VERSION "$Format:%h$"

NS_ :

BS_:

BU_: APB APP APS BCCEN BDY DAS DBG EAS EPAS EPAS2 EPAS3S EPB EPBM ESP GTW GTWU IBST IC MCU OCS PARK PARK3 RADAR RCM RT3000 SCCM SDM SEC TAS TAS2 TAS2DBG TOOL TPMS VCSEATD VCSEATP

BO_ 1481 APS_alertLog: 8 APS
 SG_ APS_alertID M : 0|14@1+ (1,0) [0|0] "" GTW
 SG_ APS_alertSource : 14|1@1+ (1,0) [0|0] "" GTW
 SG_ APS_alertType : 15|1@1+ (1,0) [0|0] "" GTW
 SG_ APS_alertDataW0 m0 : 16|16@1+ (1,0) [0|0] "" GTW
 SG_ APS_alertDataW1 m0 : 32|16@1+ (1,0) [0|0] "" GTW
 SG_ APS_alertDataW2 m0 : 48|16@1+ (1,0) [0|0] "" GTW
 SG_ APS_sw004_radIssue m4 : 16|1@1+ (1,0) [0|0] "" GTW
 SG_ APS_sw004_radHWFailure m4 : 17|1@1+ (1,0) [0|0] "" GTW
 SG_ APS_sw004_radSensorBlind m4 : 18|1@1+ (1,0) [0|0] "" GTW
 SG_ APS_sw004_radSGUFailure m4 : 19|1@1+ (1,0) [0|0] "" GTW
 SG_ APS_sw004_radMia m4 : 20|1@1+ (1,0) [0|0] "" GTW
 SG_ APS_sw004_radDynamicsError m4 : 21|1@1+ (1,0) [0|0] "" GTW
 SG_ APS_sw004_espMIA m4 : 23|1@1+ (1,0) [0|0] "" GTW
 SG_ APS_sw004_accState m4 : 24|4@1+ (1,0) [0|0] "" GTW
 SG_ APS_sw004_appMobileyeStatus m4 : 28|5@1+ (1,0) [0|0] "" GTW
 SG_ APS_sw004_diCruiseStateFault m4 : 33|1@1+ (1,0) [0|0] "" GTW
 SG_ APS_sw004_diMIA m4 : 34|1@1+ (1,0) [0|0] "" GTW
 SG_ APS_sw004_accelPedalInvalid m4 : 35|1@1+ (1,0) [0|0] "" GTW
 SG_ APS_sw004_stwAngleInvalid m4 : 36|1@1+ (1,0) [0|0] "" GTW
 SG_ APS_sw004_accelerationInvalid m4 : 37|1@1+ (1,0) [0|0] "" GTW
 SG_ APS_sw004_diSpeedInvalid m4 : 38|1@1+ (1,0) [0|0] "" GTW
 SG_ APS_sw004_APSFeaturesDisabled m4 : 40|1@1+ (1,0) [0|0] "" GTW
 SG_ APS_sw004_appMobileyeNotInVision m4 : 41|1@1+ (1,0) [0|0] "" GTW
 SG_ APS_sw004_CamCommonMIA m4 : 42|1@1+ (1,0) [0|0] "" GTW
 SG_ APS_sw004_CamObjectsMIA m4 : 43|1@1+ (1,0) [0|0] "" GTW
 SG_ APS_sw004_CamWatchdog m4 : 44|1@1+ (1,0) [0|0] "" GTW
 SG_ APS_sw004_RadarLowVisibility m4 : 45|1@1+ (1,0) [0|0] "" GTW
 SG_ APS_sw004_RadarMisalignment m4 : 46|1@1+ (1,0) [0|0] "" GTW
 SG_ APS_sw004_OutOfFocusImage m4 : 47|1@1+ (1,0) [0|0] "" GTW
 SG_ APS_sw004_ImpairedVD m4 : 48|1@1+ (1,0) [0|0] "" GTW
 SG_ APS_sw004_SunRay m4 : 49|1@1+ (1,0) [0|0] "" GTW
 SG_ APS_sw004_Splashes m4 : 50|1@1+ (1,0) [0|0] "" GTW
 SG_ APS_sw004_BlurredImage m4 : 51|1@1+ (1,0) [0|0] "" GTW
 SG_ APS_sw004_LowSun m4 : 52|1@1+ (1,0) [0|0] "" GTW
 SG_ APS_sw004_SmearedSpots m4 : 53|1@1+ (1,0) [0|0] "" GTW
 SG_ APS_sw004_PartialBlockage m4 : 54|1@1+ (1,0) [0|0] "" GTW
 SG_ APS_sw004_AutofixOutOfCalib m4 : 55|1@1+ (1,0) [0|0] "" GTW
 SG_ APS_sw004_AutofixOutOfCalibHorzn m4 : 56|1@1+ (1,0) [0|0] "" GTW
 SG_ APS_sw004_AutofixOutOfCalibYaw m4 : 57|1@1+ (1,0) [0|0] "" GTW
 SG_ APS_sw004_FullBlockage m4 : 58|1@1+ (1,0) [0|0] "" GTW
 SG_ APS_sw004_SmearedHalos m4 : 59|1@1+ (1,0) [0|0] "" GTW
 SG_ APS_sw004_FoggyLights m4 : 60|1@1+ (1,0) [0|0] "" GTW
 SG_ APS_sw004_SelfGlare m4 : 61|1@1+ (1,0) [0|0] "" GTW
 SG_ APS_sw004_visionNotRunning m4 : 62|1@1+ (1,0) [0|1] "" GTW
 SG_ APS_sw005_AutofixOutOfCalib m5 : 16|1@1+ (1,0) [0|0] "" GTW
 SG_ APS_sw005_AutofixOutOfCalibYaw m5 : 17|1@1+ (1,0) [0|0] "" GTW
 SG_ APS_sw005_RadarMisalignment m5 : 18|1@1+ (1,0) [0|0] "" GTW
 SG_ APS_sw005_partialBlockage m5 : 20|1@1+ (1,0) [0|0] "" GTW
 SG_ APS_sw005_fullBlockage m5 : 21|1@1+ (1,0) [0|0] "" GTW
 SG_ APS_sw005_camObjHeader m5 : 22|1@1+ (1,0) [0|0] "" GTW
 SG_ APS_sw005_camCommonMsg m5 : 23|1@1+ (1,0) [0|0] "" GTW
 SG_ APS_sw005_camFcwPcwMsg m5 : 24|1@1+ (1,0) [0|0] "" GTW
 SG_ APS_sw005_radHWFailure m5 : 25|1@1+ (1,0) [0|0] "" GTW
 SG_ APS_sw005_radSensorBlind m5 : 26|1@1+ (1,0) [0|0] "" GTW
 SG_ APS_sw005_radSGUFailure m5 : 27|1@1+ (1,0) [0|0] "" GTW
 SG_ APS_sw005_radMia m5 : 28|1@1+ (1,0) [0|0] "" GTW
 SG_ APS_sw005_brakePedal m5 : 29|1@1+ (1,0) [0|0] "" GTW
 SG_ APS_sw005_steeringAngle m5 : 30|1@1+ (1,0) [0|0] "" GTW
 SG_ APS_sw005_steeringAngleRate m5 : 31|1@1+ (1,0) [0|0] "" GTW
 SG_ APS_sw005_speed m5 : 32|1@1+ (1,0) [0|0] "" GTW
 SG_ APS_sw005_gear m5 : 33|1@1+ (1,0) [0|0] "" GTW
 SG_ APS_sw005_stabilityControl m5 : 34|1@1+ (1,0) [0|0] "" GTW
 SG_ APS_sw005_blinkers m5 : 35|1@1+ (1,0) [0|0] "" GTW
 SG_ APS_sw005_yaw m5 : 36|1@1+ (1,0) [0|0] "" GTW
 SG_ APS_sw005_longAccel m5 : 37|1@1+ (1,0) [0|0] "" GTW
 SG_ APS_sw005_accelPedal m5 : 38|1@1+ (1,0) [0|0] "" GTW
 SG_ APS_sw005_fcmSensitivity m5 : 41|1@1+ (1,0) [0|0] "" GTW
 SG_ APS_sw005_dasDisabled m5 : 42|1@1+ (1,0) [0|0] "" GTW
 SG_ APS_sw005_speedDerivative m5 : 43|1@1+ (1,0) [0|0] "" GTW
 SG_ APS_sw005_camWatchdog m5 : 44|1@1+ (1,0) [0|0] "" GTW
 SG_ APS_sw005_AutofixOutOfCalibHorzn m5 : 45|1@1+ (1,0) [0|0] "" GTW
 SG_ APS_sw005_RadarLowVisibility m5 : 46|1@1+ (1,0) [0|0] "" GTW
 SG_ APS_sw005_radCalibration m5 : 47|1@1+ (1,0) [0|0] "" GTW
 SG_ APS_sw006_RadarLowVisibility m6 : 16|1@1+ (1,0) [0|0] "" GTW
 SG_ APS_sw006_RadarMisaligned m6 : 17|1@1+ (1,0) [0|0] "" GTW
 SG_ APS_sw006_OutOfFocusImage m6 : 18|1@1+ (1,0) [0|0] "" GTW
 SG_ APS_sw006_SunRay m6 : 19|1@1+ (1,0) [0|0] "" GTW
 SG_ APS_sw006_Splashes m6 : 20|1@1+ (1,0) [0|0] "" GTW
 SG_ APS_sw006_BlurredImage m6 : 21|1@1+ (1,0) [0|0] "" GTW
 SG_ APS_sw006_LowSun m6 : 22|1@1+ (1,0) [0|0] "" GTW
 SG_ APS_sw006_SmearedSpots m6 : 23|1@1+ (1,0) [0|0] "" GTW
 SG_ APS_sw006_PartialBlockage m6 : 24|1@1+ (1,0) [0|0] "" GTW
 SG_ APS_sw006_AutofixOutOfCalib m6 : 25|1@1+ (1,0) [0|0] "" GTW
 SG_ APS_sw006_AutofixOutOfCalibHorzn m6 : 26|1@1+ (1,0) [0|0] "" GTW
 SG_ APS_sw006_AutofixOutOfCalibYaw m6 : 27|1@1+ (1,0) [0|0] "" GTW
 SG_ APS_sw006_FullBlockage m6 : 28|1@1+ (1,0) [0|0] "" GTW
 SG_ APS_sw006_SmearedHalos m6 : 29|1@1+ (1,0) [0|0] "" GTW
 SG_ APS_sw006_FoggyLights m6 : 30|1@1+ (1,0) [0|0] "" GTW
 SG_ APS_sw006_SelfGlare m6 : 31|1@1+ (1,0) [0|0] "" GTW
 SG_ APS_sw006_blinkers m6 : 32|1@1+ (1,0) [0|0] "" GTW
 SG_ APS_sw006_seatbelt m6 : 33|1@1+ (1,0) [0|0] "" GTW
 SG_ APS_sw006_accelPedal m6 : 34|1@1+ (1,0) [0|0] "" GTW
 SG_ APS_sw006_radMia m6 : 35|1@1+ (1,0) [0|0] "" GTW
 SG_ APS_sw006_radHWFailure m6 : 37|1@1+ (1,0) [0|0] "" GTW
 SG_ APS_sw006_radSensorBlind m6 : 38|1@1+ (1,0) [0|0] "" GTW
 SG_ APS_sw006_radSGUFailure m6 : 39|1@1+ (1,0) [0|0] "" GTW
 SG_ APS_sw006_brakePedal m6 : 40|1@1+ (1,0) [0|0] "" GTW
 SG_ APS_sw006_steeringAngle m6 : 41|1@1+ (1,0) [0|0] "" GTW
 SG_ APS_sw006_steeringAngleRate m6 : 42|1@1+ (1,0) [0|0] "" GTW
 SG_ APS_sw006_speed m6 : 43|1@1+ (1,0) [0|0] "" GTW
 SG_ APS_sw006_gear m6 : 44|1@1+ (1,0) [0|0] "" GTW
 SG_ APS_sw006_stabilityControl m6 : 45|1@1+ (1,0) [0|0] "" GTW
 SG_ APS_sw006_dasDisabled m6 : 47|1@1+ (1,0) [0|0] "" GTW
 SG_ APS_sw006_speedDerivative m6 : 48|1@1+ (1,0) [0|0] "" GTW
 SG_ APS_sw006_camWatchdog m6 : 49|1@1+ (1,0) [0|0] "" GTW
 SG_ APS_sw006_camObjHeader m6 : 50|1@1+ (1,0) [0|0] "" GTW
 SG_ APS_sw006_camCommonMsg m6 : 51|1@1+ (1,0) [0|0] "" GTW
 SG_ APS_sw006_camFcwPcwMsg m6 : 52|1@1+ (1,0) [0|0] "" GTW
 SG_ APS_sw006_longAccel m6 : 53|1@1+ (1,0) [0|0] "" GTW
 SG_ APS_sw006_yawRate m6 : 54|1@1+ (1,0) [0|0] "" GTW
 SG_ APS_sw006_DIaebState_SNA m6 : 55|1@1+ (1,0) [0|0] "" GTW
 SG_ APS_sw006_DIaebStateUnavailable m6 : 56|1@1+ (1,0) [0|0] "" GTW
 SG_ APS_sw006_brakeLights m6 : 57|1@1+ (1,0) [0|0] "" GTW
 SG_ APS_sw006_trailerMode m6 : 58|1@1+ (1,0) [0|0] "" GTW
 SG_ APS_sw006_timeOfDay m6 : 59|2@1+ (1,0) [0|0] "" GTW
 SG_ APS_sw006_radCalibration m6 : 61|1@1+ (1,0) [0|0] "" GTW
 SG_ APS_sw009_DIaebState_fault m9 : 16|1@1+ (1,0) [0|0] "" GTW
 SG_ APS_sw009_DI_aeb_unresponsive m9 : 17|1@1+ (1,0) [0|0] "" GTW
 SG_ APS_sw009_DI_MIA m9 : 18|1@1+ (1,0) [0|0] "" GTW
 SG_ APS_sw010_a04calibNotDone m10 : 16|1@1+ (1,0) [0|0] "" GTW
 SG_ APS_sw010_a05calibReqd m10 : 17|1@1+ (1,0) [0|0] "" GTW
 SG_ APS_sw010_a06calibNotOK m10 : 18|1@1+ (1,0) [0|0] "" GTW
 SG_ APS_sw010_a08PlantMode m10 : 19|1@1+ (1,0) [0|0] "" GTW
 SG_ APS_sw010_HorizontalMisalignment m10 : 20|16@1+ (0.00137332,-45) [-45|45.0005262] "deg" GTW
 SG_ APS_sw010_VerticalMisalignment m10 : 36|10@1+ (0.087977,-45) [-45|45.000471] "deg" GTW
 SG_ APS_sw010_unusedBits m10 : 46|2@1+ (1,0) [0|0] "" GTW
 SG_ APS_sw010_VmaPlausibility m10 : 48|16@1+ (1.52587890625005E-05,0) [0|0.99998474121097] "" GTW
 SG_ APS_sw011_scaState m11 : 16|3@1+ (1,0) [0|7] "" GTW
 SG_ APS_sw011_scaLeft m11 : 19|1@1+ (1,0) [0|1] "" GTW
 SG_ APS_sw011_scaRight m11 : 20|1@1+ (1,0) [0|1] "" GTW
 SG_ APS_sw011_scaBlinker m11 : 21|2@1+ (1,0) [0|3] "" GTW
 SG_ APS_sw011_scaThreshold m11 : 23|1@1+ (1,0) [0|1] "" GTW
 SG_ APS_sw011_scaSpeed m11 : 24|7@1+ (1,0) [0|127] "MPH" GTW
 SG_ APS_sw011_scaSonicDist m11 : 31|5@1+ (0.05,0) [0|1.5] "m" GTW
 SG_ APS_sw011_scaSteerAngle m11 : 38|10@1+ (0.1,-51.2) [-51.2|51.1] "deg" GTW
 SG_ APS_sw011_egoRightOfCenter m11 : 48|1@1+ (1,0) [0|1] "" GTW
 SG_ APS_sw011_egoMovingRight m11 : 49|1@1+ (1,0) [0|1] "" GTW
 SG_ APS_sw011_egoLeftOfCenter m11 : 50|1@1+ (1,0) [0|1] "" GTW
 SG_ APS_sw011_egoMovingLeft m11 : 51|1@1+ (1,0) [0|1] "" GTW
 SG_ APS_sw011_polyValid m11 : 52|1@1+ (1,0) [0|1] "" GTW
 SG_ APS_sw011_egoCentered m11 : 53|1@1+ (1,0) [0|1] "" GTW
 SG_ APS_sw011_scaReasonEldw m11 : 54|1@1+ (1,0) [0|1] "" GTW
 SG_ APS_sw011_laneWidth m11 : 56|8@1+ (0.025,0) [0|6.375] "m" GTW
 SG_ APS_sw012_bootTestResults m12 : 16|16@1+ (1,0) [0|65535] "" GTW
 SG_ APS_sw012_bootDDRTempStatus m12 : 32|2@1+ (1,0) [0|3] "" GTW
 SG_ APS_sw012_mespFatalErrCode m12 : 34|8@1+ (1,0) [0|255] "" GTW
 SG_ APS_sw012_mespFatalErrDetails m12 : 42|8@1+ (1,0) [0|255] "" GTW
 SG_ APS_sw012_mespDDRTempStatus m12 : 50|3@1+ (1,0) [0|7] "" GTW
 SG_ APS_sw012_freescaleTemp m12 : 56|8@1- (1,0) [-128|127] "degC" GTW
 SG_ APS_sw013_stateBeforeWatchdog m13 : 16|5@1+ (1,0) [0|0] "" GTW
 SG_ APS_sw013_numEyeqResets m13 : 21|3@1+ (1,0) [0|0] "" GTW
 SG_ APS_sw013_numCrcErrors m13 : 24|8@1+ (1,0) [0|0] "" GTW
 SG_ APS_sw013_numSeqErrors m13 : 32|8@1+ (1,0) [0|0] "" GTW
 SG_ APS_sw013_numNaksReceived m13 : 40|8@1+ (1,0) [0|0] "" GTW
 SG_ APS_sw013_highestSeqRecd m13 : 48|12@1+ (1,0) [0|0] "" GTW
 SG_ APS_sw013_numTransportErrors m13 : 60|4@1+ (1,0) [0|0] "" GTW
 SG_ APS_sw014_fileNameHash m14 : 16|16@1+ (1,0) [0|0] "" GTW
 SG_ APS_sw014_lineNumberInCode m14 : 32|16@1+ (1,0) [0|0] "" GTW
 SG_ APS_sw014_assertData m14 : 48|16@1+ (1,0) [0|0] "" GTW
 SG_ APS_sw015_RadarLowVisibility m15 : 16|2@1+ (1,0) [0|1] "" GTW
 SG_ APS_sw015_RadarMisalignment m15 : 18|2@1+ (1,0) [0|1] "" GTW
 SG_ APS_sw015_LowSun m15 : 20|2@1+ (1,0) [0|1] "" GTW
 SG_ APS_sw015_BlurredImage m15 : 22|2@1+ (1,0) [0|1] "" GTW
 SG_ APS_sw015_FullBlockage m15 : 24|2@1+ (1,0) [0|1] "" GTW
 SG_ APS_sw015_PartialBlockage m15 : 26|2@1+ (1,0) [0|1] "" GTW
 SG_ APS_sw015_AutofixOutOfCalib m15 : 28|2@1+ (1,0) [0|1] "" GTW
 SG_ APS_sw015_AutofixOutOfCalibYaw m15 : 30|2@1+ (1,0) [0|1] "" GTW
 SG_ APS_sw015_AutofixOOfCalibHorizon m15 : 32|2@1+ (1,0) [0|1] "" GTW
 SG_ APS_sw015_Splashes m15 : 34|2@1+ (1,0) [0|1] "" GTW
 SG_ APS_sw015_SmearedSpots m15 : 36|2@1+ (1,0) [0|1] "" GTW
 SG_ APS_sw015_SmearedHalos m15 : 38|2@1+ (1,0) [0|1] "" GTW
 SG_ APS_sw015_FoggyLights m15 : 40|2@1+ (1,0) [0|1] "" GTW
 SG_ APS_sw015_SunRay m15 : 42|2@1+ (1,0) [0|1] "" GTW
 SG_ APS_sw015_ImpairedVD m15 : 44|2@1+ (1,0) [0|1] "" GTW
 SG_ APS_sw015_SelfGlare m15 : 46|2@1+ (1,0) [0|1] "" GTW
 SG_ APS_sw015_OutOfFocusImage m15 : 48|2@1+ (1,0) [0|1] "" GTW
 SG_ APS_sw016_targetDist m16 : 16|9@1+ (0.2,0) [0|102.2] "m" GTW
 SG_ APS_sw016_targetRelSpeed m16 : 25|9@1+ (0.0625,-31) [-31|0.9375] "m/s" GTW
 SG_ APS_sw016_targetOverlap m16 : 34|6@1+ (0.1,0) [0|6.3] "m" GTW
 SG_ APS_sw016_hostSpeed m16 : 40|8@1+ (1,0) [0|255] "kph" GTW
 SG_ APS_sw016_hostLongAccel m16 : 48|7@1+ (0.15625,-10) [-10|10] "m/s^2" GTW
 SG_ APS_sw016_driverPressedAccelPed m16 : 55|1@1+ (1,0) [0|1] "" GTW
 SG_ APS_sw016_driverPressedBrakePed m16 : 56|1@1+ (1,0) [0|1] "" GTW
 SG_ APS_sw016_aebEnable m16 : 57|1@1+ (1,0) [0|1] "" GTW
 SG_ APS_sw016_overrideBlinker m16 : 58|1@1+ (1,0) [0|1] "" GTW
 SG_ APS_sw016_overrideBrake m16 : 59|1@1+ (1,0) [0|1] "" GTW
 SG_ APS_sw016_overrideSteer m16 : 60|1@1+ (1,0) [0|1] "" GTW
 SG_ APS_sw016_fcmModeAtEvent m16 : 61|2@1+ (1,0) [0|3] "" GTW
 SG_ APS_sw016_accActive m16 : 63|1@1+ (1,0) [0|1] "" GTW
 SG_ APS_sw017_Camera_Msg_Lanes_MIA m17 : 16|1@1+ (1,0) [0|1] "" GTW
 SG_ APS_sw017_Camera_Msg_Objects_MIA m17 : 17|1@1+ (1,0) [0|1] "" GTW
 SG_ APS_sw017_Camera_Msg_Tsr_MIA m17 : 18|1@1+ (1,0) [0|1] "" GTW
 SG_ APS_sw017_Camera_Msg_Hlb_MIA m17 : 19|1@1+ (1,0) [0|1] "" GTW
 SG_ APS_sw017_Camera_Msg_Common_MIA m17 : 20|1@1+ (1,0) [0|1] "" GTW
 SG_ APS_sw017_Camera_Msg_FCW_PCW_MIA m17 : 21|1@1+ (1,0) [0|1] "" GTW
 SG_ APS_sw017_Camera_Msg_TFL_MIA m17 : 22|1@1+ (1,0) [0|1] "" GTW
 SG_ APS_sw017_Any_Lanes_Msg_Recd m17 : 23|1@1+ (1,0) [0|1] "" GTW
 SG_ APS_sw017_Any_Objects_Msg_Recd m17 : 24|1@1+ (1,0) [0|1] "" GTW
 SG_ APS_sw017_Any_TFL_Msg_Recd m17 : 25|1@1+ (1,0) [0|1] "" GTW
 SG_ APS_sw017_numCrcErrors m17 : 26|6@1+ (1,0) [0|63] "" GTW
 SG_ APS_sw017_numSeqErrors m17 : 32|8@1+ (1,0) [0|255] "" GTW
 SG_ APS_sw017_numTransportErrors m17 : 40|8@1+ (1,0) [0|0] "" GTW
 SG_ APS_sw017_highestSeqRecd m17 : 48|12@1+ (1,0) [0|0] "" GTW
 SG_ APS_sw017_Any_Tsr_Msg_Recd m17 : 60|1@1+ (1,0) [0|1] "" GTW
 SG_ APS_sw017_Any_Hlb_Msg_Recd m17 : 61|1@1+ (1,0) [0|1] "" GTW
 SG_ APS_sw017_Any_Common_Msg_Recd m17 : 62|1@1+ (1,0) [0|1] "" GTW
 SG_ APS_sw017_Any_FCW_PCW_Msg_Recd m17 : 63|1@1+ (1,0) [0|1] "" GTW
 SG_ APS_sw018_minThreshold m18 : 16|13@1+ (1,0) [0|4500] "mV" GTW
 SG_ APS_sw018_railID m18 : 29|2@1+ (1,0) [0|3] "" GTW
 SG_ APS_sw018_powerSequnceError m18 : 31|1@1+ (1,0) [0|3] "" GTW
 SG_ APS_sw018_maxThreshold m18 : 32|15@1+ (1,0) [50|5500] "mV" GTW
 SG_ APS_sw018_railControl m18 : 47|1@1+ (1,0) [0|1] "" GTW
 SG_ APS_sw018_currentVoltage m18 : 48|16@1+ (1,0) [0|6600] "mV" GTW
 SG_ APS_sw019_taskId m19 : 16|8@1+ (1,0) [0|0] "" GTW
 SG_ APS_sw019_numFreeBytes m19 : 24|8@1+ (1,-191) [-191|64] "# of bytes" GTW
 SG_ APS_sw019_timeStamp m19 : 32|32@1+ (1,0) [0|4294967295] "ms" GTW
 SG_ APS_sw020_unusedW0 m20 : 16|16@1+ (1,0) [0|0] "" GTW
 SG_ APS_sw020_unusedW1 m20 : 32|16@1+ (1,0) [0|0] "" GTW
 SG_ APS_sw020_unusedW2 m20 : 48|16@1+ (1,0) [0|0] "" GTW
 SG_ APS_sw021_tempSensorId m21 : 16|8@1+ (1,0) [0|4] "" GTW
 SG_ APS_sw021_minThreshold m21 : 24|8@1- (1,0) [-128|127] "degC" GTW
 SG_ APS_sw021_maxThreshold m21 : 32|8@1- (1,0) [-128|127] "degC" GTW
 SG_ APS_sw021_currentTemperature m21 : 40|8@1- (1,0) [-128|127] "degC" GTW
 SG_ APS_sw021_unusedWord m21 : 48|16@1+ (1,0) [0|0] "" GTW
 SG_ APS_sw022_operation m22 : 16|4@1+ (1,0) [0|0] "" GTW
 SG_ APS_sw022_recordId m22 : 20|12@1+ (1,0) [0|0] "" GTW
 SG_ APS_sw022_errorCode m22 : 32|32@1+ (1,0) [0|0] "" GTW
 SG_ APS_sw024_Task_ID m24 : 16|4@1+ (1,0) [0|0] "" GTW
 SG_ APS_sw024_numVirtualLaneVeh m24 : 20|4@1+ (1,0) [0|0] "" GTW
 SG_ APS_sw024_currentVehicleApp m24 : 24|8@1+ (1,0) [0|0] "" GTW
 SG_ APS_sw024_taskProgramCounter m24 : 32|32@1+ (1,0) [0|0] "" GTW
 SG_ APS_sw025_state_before_override m25 : 16|4@1+ (1,0) [0|15] "" GTW
 SG_ APS_sw025_road_class m25 : 20|3@1+ (1,0) [0|0] "" GTW
 SG_ APS_sw025_road_match m25 : 23|1@1+ (1,0) [0|0] "" GTW
 SG_ APS_sw025_controlled_access m25 : 24|1@1+ (1,0) [0|0] "" GTW
 SG_ APS_sw025_leftLaneUsage m25 : 25|2@1+ (1,0) [0|3] "" GTW
 SG_ APS_sw025_rightLaneUsage m25 : 27|2@1+ (1,0) [0|3] "" GTW
 SG_ APS_sw025_vehiclesUsage m25 : 29|2@1+ (1,0) [0|3] "" GTW
 SG_ APS_sw025_hppUsage m25 : 31|2@1+ (1,0) [0|3] "" GTW
 SG_ APS_sw025_navigationUsage m25 : 33|2@1+ (1,0) [0|3] "" GTW
 SG_ APS_sw025_modelUsage m25 : 35|2@1+ (1,0) [0|3] "" GTW
 SG_ APS_sw025_bottsDotsUsage m25 : 37|2@1+ (1,0) [0|3] "" GTW
 SG_ APS_sw025_offsetSide m25 : 39|2@1+ (1,0) [0|3] "" GTW
 SG_ APS_sw025_torsionBarTorque m25 : 41|8@1+ (0.1,-12.8) [-12.8|12.7] "Nm" GTW
 SG_ APS_sw026_task_id m26 : 16|2@1+ (1,0) [0|3] "" GTW
 SG_ APS_sw026_tardiness m26 : 18|9@1+ (0.25,0) [0|127.75] "ms" GTW
 SG_ APS_sw026_execution_time m26 : 27|9@1+ (0.125,0) [0|65.411] "ms" GTW
 SG_ APS_sw026_can_mean_utilization m26 : 36|7@1+ (1,0) [0|127] "percent" GTW
 SG_ APS_sw026_uds_mean_utilization m26 : 43|7@1+ (1,0) [0|127] "percent" GTW
 SG_ APS_sw026_mob_mean_utilization m26 : 50|7@1+ (1,0) [0|127] "percent" GTW
 SG_ APS_sw026_veh_mean_utilization m26 : 57|7@1+ (1,0) [0|127] "percent" GTW
 SG_ APS_sw027_JTAG_Reset m27 : 16|1@1+ (1,0) [0|0] "" GTW
 SG_ APS_sw027_Core_Reset m27 : 17|1@1+ (1,0) [0|0] "" GTW
 SG_ APS_sw027_Unused_Bit_0 m27 : 18|1@1+ (1,0) [0|0] "" GTW
 SG_ APS_sw027_CPU_Checkstop_Error m27 : 19|1@1+ (1,0) [0|0] "" GTW
 SG_ APS_sw027_PLL_0_Failure m27 : 20|1@1+ (1,0) [0|0] "" GTW
 SG_ APS_sw027_Clock_Monitor_0_Low m27 : 21|1@1+ (1,0) [0|0] "" GTW
 SG_ APS_sw027_Clock_Monitor_0_Off m27 : 22|1@1+ (1,0) [0|0] "" GTW
 SG_ APS_sw027_LVD_4v5 m27 : 23|1@1+ (1,0) [0|0] "" GTW
 SG_ APS_sw027_Flash_Fatal_Error m27 : 24|1@1+ (1,0) [0|0] "" GTW
 SG_ APS_sw027_PLL_1_Failure m27 : 25|1@1+ (1,0) [0|0] "" GTW
 SG_ APS_sw027_Unused_Bit_1 m27 : 26|1@1+ (1,0) [0|0] "" GTW
 SG_ APS_sw027_f_PLL_1_Off m27 : 27|1@1+ (1,0) [0|0] "" GTW
 SG_ APS_sw027_Unused_Nibble m27 : 28|4@1+ (1,0) [0|0] "" GTW
 SG_ APS_sw027_LVD_1v2 m27 : 32|1@1+ (1,0) [0|0] "" GTW
 SG_ APS_sw027_Unused_Bit_2 m27 : 33|1@1+ (1,0) [0|0] "" GTW
 SG_ APS_sw027_Watchdog m27 : 34|1@1+ (1,0) [0|0] "" GTW
 SG_ APS_sw027_Unused_Bit_3 m27 : 35|1@1+ (1,0) [0|0] "" GTW
 SG_ APS_sw027_LVD_2v7_VREG m27 : 36|1@1+ (1,0) [0|0] "" GTW
 SG_ APS_sw027_LVD_2v7_Flash m27 : 37|1@1+ (1,0) [0|0] "" GTW
 SG_ APS_sw027_LVD_2v7_IO m27 : 38|1@1+ (1,0) [0|0] "" GTW
 SG_ APS_sw027_Unused_Bit_4 m27 : 39|1@1+ (1,0) [0|0] "" GTW
 SG_ APS_sw027_Unused_Byte m27 : 40|8@1+ (1,0) [0|0] "" GTW
 SG_ APS_sw027_ESR0 m27 : 48|1@1+ (1,0) [0|0] "" GTW
 SG_ APS_sw027_ESR1 m27 : 49|1@1+ (1,0) [0|0] "" GTW
 SG_ APS_sw027_SW m27 : 50|1@1+ (1,0) [0|0] "" GTW
 SG_ APS_sw027_STM0 m27 : 51|1@1+ (1,0) [0|0] "" GTW
 SG_ APS_sw027_STM1 m27 : 52|1@1+ (1,0) [0|0] "" GTW
 SG_ APS_sw027_STM2 m27 : 53|1@1+ (1,0) [0|0] "" GTW
 SG_ APS_sw027_CBS_SYSTEM m27 : 54|1@1+ (1,0) [0|0] "" GTW
 SG_ APS_sw027_CBS_DEBUG m27 : 55|1@1+ (1,0) [0|0] "" GTW
 SG_ APS_sw027_CBS_APP m27 : 56|1@1+ (1,0) [0|0] "" GTW
 SG_ APS_sw027_EVR13 m27 : 57|1@1+ (1,0) [0|0] "" GTW
 SG_ APS_sw027_EVR33 m27 : 58|1@1+ (1,0) [0|0] "" GTW
 SG_ APS_sw027_SWD m27 : 59|1@1+ (1,0) [0|0] "" GTW
 SG_ APS_sw027_STDBY_WDG m27 : 60|1@1+ (1,0) [0|0] "" GTW
 SG_ APS_sw027_PORST m27 : 61|1@1+ (1,0) [0|0] "" GTW
 SG_ APS_sw027_Unused_word m27 : 62|2@1+ (1,0) [0|0] "" GTW
 SG_ APS_sw028_rx_buffer_full m28 : 16|1@1+ (1,0) [0|0] "" GTW
 SG_ APS_sw028_rx_inv_len m28 : 17|1@1+ (1,0) [0|0] "" GTW
 SG_ APS_sw028_inv_multifrm_1st m28 : 18|1@1+ (1,0) [0|0] "" GTW
 SG_ APS_sw028_inv_multifrm_id m28 : 19|1@1+ (1,0) [0|0] "" GTW
 SG_ APS_sw028_inv_multifrm_next m28 : 20|1@1+ (1,0) [0|0] "" GTW
 SG_ APS_sw028_unusedBits m28 : 21|11@1+ (1,0) [0|0] "" GTW
 SG_ APS_sw028_highestSeqRcvd m28 : 32|16@1+ (1,0) [0|0] "" GTW
 SG_ APS_sw028_multifrm_rx_len m28 : 48|16@1+ (1,0) [0|0] "" GTW
 SG_ APS_sw029_tx_buffer_full m29 : 16|1@1+ (1,0) [0|0] "" GTW
 SG_ APS_sw029_unusedBits m29 : 17|15@1+ (1,0) [0|0] "" GTW
 SG_ APS_sw029_highestSeqRcvd m29 : 32|16@1+ (1,0) [0|0] "" GTW
 SG_ APS_sw029_unusedW1 m29 : 48|16@1+ (1,0) [0|0] "" GTW
 SG_ APS_sw030_heaterState m30 : 16|8@1+ (1,0) [0|0] "" GTW
 SG_ APS_sw030_unusedByte m30 : 24|8@1+ (1,0) [0|0] "" GTW
 SG_ APS_sw030_unusedW0 m30 : 32|16@1+ (1,0) [0|0] "" GTW
 SG_ APS_sw030_unusedW1 m30 : 48|16@1+ (1,0) [0|0] "" GTW
 SG_ APS_sw031_canBus m31 : 16|4@1+ (1,0) [0|0] "" GTW
 SG_ APS_sw031_errorType m31 : 24|8@1+ (1,0) [0|0] "" GTW
 SG_ APS_sw031_errorData1 m31 : 32|16@1+ (1,0) [0|0] "" GTW
 SG_ APS_sw031_errorData2 m31 : 48|16@1+ (1,0) [0|0] "" GTW
 SG_ APS_sw032_canBus m32 : 16|4@1+ (1,0) [0|0] "" GTW
 SG_ APS_sw032_errorType m32 : 24|8@1+ (1,0) [0|0] "" GTW
 SG_ APS_sw032_errorData1 m32 : 32|16@1+ (1,0) [0|0] "" GTW
 SG_ APS_sw032_errorData2 m32 : 48|16@1+ (1,0) [0|0] "" GTW
 SG_ APS_sw033_gtwMia m33 : 16|8@1+ (1,0) [0|0] "" GTW
 SG_ APS_sw033_unusedByte m33 : 24|8@1+ (1,0) [0|0] "" GTW
 SG_ APS_sw033_bcStatus m33 : 32|1@1+ (1,0) [0|0] "" GTW
 SG_ APS_sw033_carConfig m33 : 33|1@1+ (1,0) [0|0] "" GTW
 SG_ APS_sw033_carState m33 : 34|1@1+ (1,0) [0|0] "" GTW
 SG_ APS_sw033_chNm m33 : 35|1@1+ (1,0) [0|0] "" GTW
 SG_ APS_sw033_odo m33 : 36|1@1+ (1,0) [0|0] "" GTW
 SG_ APS_sw033_status m33 : 37|1@1+ (1,0) [0|0] "" GTW
 SG_ APS_sw033_vip m33 : 38|1@1+ (1,0) [0|0] "" GTW
 SG_ APS_sw034_sccmMia m34 : 16|8@1+ (1,0) [0|0] "" GTW
 SG_ APS_sw034_unusedByte m34 : 24|8@1+ (1,0) [0|0] "" GTW
 SG_ APS_sw034_sbwRq m34 : 32|1@1+ (1,0) [0|0] "" GTW
 SG_ APS_sw034_stwActnRq m34 : 33|1@1+ (1,0) [0|0] "" GTW
 SG_ APS_sw034_stwAnglHpStat m34 : 34|1@1+ (1,0) [0|0] "" GTW
 SG_ APS_sw035_espMia m35 : 16|8@1+ (1,0) [0|0] "" GTW
 SG_ APS_sw035_unusedByte m35 : 24|8@1+ (1,0) [0|0] "" GTW
 SG_ APS_sw035_115h m35 : 32|1@1+ (1,0) [0|0] "" GTW
 SG_ APS_sw035_125h m35 : 33|1@1+ (1,0) [0|0] "" GTW
 SG_ APS_sw035_135h m35 : 34|1@1+ (1,0) [0|0] "" GTW
 SG_ APS_sw035_145h m35 : 35|1@1+ (1,0) [0|0] "" GTW
 SG_ APS_sw035_B m35 : 36|1@1+ (1,0) [0|0] "" GTW
 SG_ APS_sw035_C m35 : 37|1@1+ (1,0) [0|0] "" GTW
 SG_ APS_sw035_wheelSpeeds m35 : 38|1@1+ (1,0) [0|0] "" GTW
 SG_ APS_sw036_bdyMia m36 : 16|8@1+ (1,0) [0|0] "" GTW
 SG_ APS_sw036_unusedByte m36 : 24|8@1+ (1,0) [0|0] "" GTW
 SG_ APS_sw036_status m36 : 32|1@1+ (1,0) [0|0] "" GTW
 SG_ APS_sw037_camera m37 : 16|8@1+ (1,0) [0|0] "" GTW
 SG_ APS_sw037_issue m37 : 24|8@1+ (1,0) [0|0] "" GTW
 SG_ APS_sw037_unusedW0 m37 : 32|16@1+ (1,0) [0|0] "" GTW
 SG_ APS_sw037_unusedW1 m37 : 48|16@1+ (1,0) [0|0] "" GTW
 SG_ APS_sw038_RadarMisalignment m38 : 17|1@1+ (1,0) [0|1] "" GTW
 SG_ APS_sw038_OutOfFocusImage m38 : 18|1@1+ (1,0) [0|1] "" GTW
 SG_ APS_sw038_AutofixOutOfCalib m38 : 19|1@1+ (1,0) [0|1] "" GTW
 SG_ APS_sw038_AutofixOutOfCalibHorzn m38 : 20|1@1+ (1,0) [0|1] "" GTW
 SG_ APS_sw038_AutofixOutOfCalibYaw m38 : 21|1@1+ (1,0) [0|1] "" GTW
 SG_ APS_sw038_FullBlockage m38 : 22|1@1+ (1,0) [0|1] "" GTW
 SG_ APS_sw038_TooManyResets m38 : 23|1@1+ (1,0) [0|1] "" GTW
 SG_ APS_sw039_sdm_rcm_Mia m39 : 16|8@1+ (1,0) [0|0] "" GTW
 SG_ APS_sw039_unusedByte m39 : 24|8@1+ (1,0) [0|0] "" GTW
 SG_ APS_sw039_status m39 : 32|1@1+ (1,0) [0|0] "" GTW
 SG_ APS_sw039_sdm1 m39 : 33|1@1+ (1,0) [0|0] "" GTW
 SG_ APS_sw040_accel_pedal_pos m40 : 16|8@1+ (0.5,0) [0|127.5] "%" GTW
 SG_ APS_sw040_ego_veh_speed m40 : 24|8@1+ (0.2,0) [0|51] "m/s" GTW
 SG_ APS_sw040_das_steering_req m40 : 32|8@1+ (1,-128) [-128|127] "deg" GTW
 SG_ APS_sw040_epas_internal_sas m40 : 40|8@1+ (1,-128) [-128|127] "deg" GTW
 SG_ APS_sw040_torsion_bar_torque m40 : 48|8@1+ (0.1,-12.8) [-12.8|12.7] "Nm" GTW
 SG_ APS_sw040_view_range m40 : 56|8@1+ (1,0) [0|255] "m" GTW
 SG_ APS_sw041_rate m41 : 16|10@1- (1,0) [-512|511] "deg/s" GTW
 SG_ APS_sw041_max_rate m41 : 26|10@1- (1,0) [-512|511] "deg/s" GTW
 SG_ APS_sw041_ego_speed m41 : 36|10@1+ (0.05,0) [0|51.15] "m/s" GTW
 SG_ APS_sw041_unusedW2 m41 : 46|18@1+ (1,0) [0|0] "" GTW
 SG_ APS_sw042_health_state m42 : 16|3@1+ (1,0) [0|0] "" GTW
 SG_ APS_sw042_abort_reason m42 : 19|5@1+ (1,0) [0|31] "" GTW
 SG_ APS_sw042_view_range m42 : 24|8@1+ (1,0) [0|0] "" GTW
 SG_ APS_sw042_state_before_abort m42 : 32|4@1+ (1,0) [0|15] "" GTW
 SG_ APS_sw042_epas_error_code m42 : 36|4@1+ (1,0) [0|15] "" GTW
 SG_ APS_sw042_cam_SunRay m42 : 40|1@1+ (1,0) [0|1] "" GTW
 SG_ APS_sw042_cam_RoadSpray m42 : 41|1@1+ (1,0) [0|1] "" GTW
 SG_ APS_sw042_cam_BlurredImage m42 : 42|1@1+ (1,0) [0|1] "" GTW
 SG_ APS_sw042_cam_LowSun m42 : 43|1@1+ (1,0) [0|1] "" GTW
 SG_ APS_sw042_cam_SmearedSpots m42 : 44|1@1+ (1,0) [0|1] "" GTW
 SG_ APS_sw042_cam_PartialBlock m42 : 45|1@1+ (1,0) [0|1] "" GTW
 SG_ APS_sw042_cam_Autofix m42 : 46|1@1+ (1,0) [0|1] "" GTW
 SG_ APS_sw042_cam_AutofixHorizon m42 : 47|1@1+ (1,0) [0|1] "" GTW
 SG_ APS_sw042_cam_AutofixYaw m42 : 48|1@1+ (1,0) [0|1] "" GTW
 SG_ APS_sw042_cam_FullBlock m42 : 49|1@1+ (1,0) [0|1] "" GTW
 SG_ APS_sw042_cam_SmearedHalos m42 : 50|1@1+ (1,0) [0|1] "" GTW
 SG_ APS_sw042_cam_FoggySpots m42 : 51|1@1+ (1,0) [0|1] "" GTW
 SG_ APS_sw042_cam_SelfGlare m42 : 52|1@1+ (1,0) [0|1] "" GTW
 SG_ APS_sw042_cam_OutofFocus m42 : 53|1@1+ (1,0) [0|1] "" GTW
 SG_ APS_sw042_road_match m42 : 54|1@1+ (1,0) [0|1] "" GTW
 SG_ APS_sw042_controlled_access m42 : 55|1@1+ (1,0) [0|1] "" GTW
 SG_ APS_sw042_road_class m42 : 56|3@1+ (1,0) [0|7] "" GTW
 SG_ APS_sw043_mobileye_status m43 : 16|16@1+ (1,0) [0|0] "" GTW
 SG_ APS_sw043_mesp_health_main_state m43 : 32|16@1+ (1,0) [0|0] "" GTW
 SG_ APS_sw043_camLongRunTime_unused m43 : 48|16@1+ (1,0) [0|0] "" GTW
 SG_ APS_sw044_countLSB m44 : 16|8@1+ (1,0) [0|0] "" GTW
 SG_ APS_sw044_meMainState m44 : 28|4@1+ (1,0) [0|15] "" GTW
 SG_ APS_sw044_timestampms m44 : 32|24@1+ (1,0) [0|16777215] "ms" GTW
 SG_ APS_sw044_appStatus m44 : 56|8@1+ (1,0) [0|63] "" GTW
 SG_ APS_sw045_radMia m45 : 16|8@1+ (1,0) [0|0] "" GTW
 SG_ APS_sw045_unusedByte m45 : 24|8@1+ (1,0) [0|0] "" GTW
 SG_ APS_sw045_radcAlertMatrix m45 : 32|1@1+ (1,0) [0|0] "" GTW
 SG_ APS_sw045_radcInfo m45 : 33|1@1+ (1,0) [0|0] "" GTW
 SG_ APS_sw045_radcAccTargObj1A m45 : 34|1@1+ (1,0) [0|0] "" GTW
 SG_ APS_sw045_lrrAlertMatrix0 m45 : 35|1@1+ (1,0) [0|0] "" GTW
 SG_ APS_sw045_lrrPacketEnder m45 : 36|1@1+ (1,0) [0|0] "" GTW
 SG_ APS_sw045_lrrRadarStatus m45 : 37|1@1+ (1,0) [0|0] "" GTW
 SG_ APS_sw045_lrrObj00A m45 : 38|1@1+ (1,0) [0|0] "" GTW
 SG_ APS_sw046_recordId m46 : 16|16@1+ (1,0) [0|0] "" GTW
 SG_ APS_sw046_errorCode m46 : 32|32@1+ (1,0) [0|0] "" GTW
 SG_ APS_sw047_edrStatus m47 : 16|4@1+ (1,0) [0|0] "" GTW
 SG_ APS_sw047_roadClass m47 : 20|3@1+ (1,0) [0|0] "" GTW
 SG_ APS_sw047_controlledAccess m47 : 23|1@1+ (1,0) [0|0] "" GTW
 SG_ APS_sw047_edrType m47 : 24|6@1+ (1,0) [0|0] "" GTW
 SG_ APS_sw047_edrBlackBox m47 : 30|2@1+ (1,0) [0|0] "" GTW
 SG_ APS_sw047_edrReturn m47 : 32|16@1+ (1,0) [0|0] "" GTW
 SG_ APS_sw047_edrStateMachine m47 : 48|8@1+ (1,0) [0|0] "" GTW
 SG_ APS_sw047_edrLoggerBuffer m47 : 56|2@1+ (1,0) [0|0] "" GTW
 SG_ APS_sw047_unused m47 : 58|6@1+ (1,0) [0|0] "" GTW
 SG_ APS_sw048_swAssert m48 : 16|1@1+ (1,0) [0|1] "" GTW
 SG_ APS_sw048_thermalIssue m48 : 17|1@1+ (1,0) [0|1] "" GTW
 SG_ APS_sw048_powerIssue m48 : 18|1@1+ (1,0) [0|1] "" GTW
 SG_ APS_sw048_stackOverflow m48 : 19|1@1+ (1,0) [0|1] "" GTW
 SG_ APS_sw048_checkStop m48 : 20|1@1+ (1,0) [0|1] "" GTW
 SG_ APS_sw048_ecuWatchdog m48 : 21|1@1+ (1,0) [0|1] "" GTW
 SG_ APS_sw048_ecuReset m48 : 22|1@1+ (1,0) [0|1] "" GTW
 SG_ APS_sw048_radcVersionMismatch m48 : 23|1@1+ (1,0) [0|1] "" GTW
 SG_ APS_sw048_radcCalibration m48 : 24|1@1+ (1,0) [0|1] "" GTW
 SG_ APS_sw048_radcMia m48 : 25|1@1+ (1,0) [0|1] "" GTW
 SG_ APS_sw048_eyeQVersionMismatch m48 : 26|1@1+ (1,0) [0|1] "" GTW
 SG_ APS_sw048_camIssue m48 : 27|1@1+ (1,0) [0|1] "" GTW
 SG_ APS_sw048_parkerIssue m48 : 28|1@1+ (1,0) [0|1] "" GTW
 SG_ APS_sw048_prolongedUiMia m48 : 29|1@1+ (1,0) [0|1] "" GTW
 SG_ APS_sw048_uiMiaAtBootup m48 : 30|1@1+ (1,0) [0|1] "" GTW
 SG_ APS_sw049_boot_version_msw m49 : 16|16@1+ (1,0) [0|0] "" GTW
 SG_ APS_sw049_app_version_msw m49 : 32|16@1+ (1,0) [0|0] "" GTW
 SG_ APS_sw049_ffs_version_msw m49 : 48|16@1+ (1,0) [0|0] "" GTW
 SG_ APS_sw050_targetDist m50 : 16|9@1+ (0.2,0) [0|102.2] "m" GTW
 SG_ APS_sw050_targetRelSpeed m50 : 25|9@1+ (0.0625,-31) [-31|0.9375] "m/s" GTW
 SG_ APS_sw050_targetOverlap m50 : 34|6@1+ (0.1,0) [0|6.3] "m" GTW
 SG_ APS_sw050_hostSpeed m50 : 40|8@1+ (1,0) [0|255] "kph" GTW
 SG_ APS_sw050_hostLongAccel m50 : 48|7@1+ (0.15625,-10) [-10|10] "m/s^2" GTW
 SG_ APS_sw050_driverPressedAccelPed m50 : 55|1@1+ (1,0) [0|1] "" GTW
 SG_ APS_sw050_driverPressedBrakePed m50 : 56|1@1+ (1,0) [0|1] "" GTW
 SG_ APS_sw050_aebEnable m50 : 57|1@1+ (1,0) [0|1] "" GTW
 SG_ APS_sw050_overrideBlinker m50 : 58|1@1+ (1,0) [0|1] "" GTW
 SG_ APS_sw050_overrideBrake m50 : 59|1@1+ (1,0) [0|1] "" GTW
 SG_ APS_sw050_overrideSteer m50 : 60|1@1+ (1,0) [0|1] "" GTW
 SG_ APS_sw050_fcmModeAtEvent m50 : 61|2@1+ (1,0) [0|3] "" GTW
 SG_ APS_sw050_accActive m50 : 63|1@1+ (1,0) [0|1] "" GTW
 SG_ APS_sw051_a01ecuInternalPerf m51 : 16|1@1+ (1,0) [0|1] "" GTW
 SG_ APS_sw051_a02flashPerformance m51 : 17|1@1+ (1,0) [0|1] "" GTW
 SG_ APS_sw051_a03vBatHigh m51 : 18|1@1+ (1,0) [0|1] "" GTW
 SG_ APS_sw051_a09configMismatch m51 : 19|1@1+ (1,0) [0|1] "" GTW
 SG_ APS_sw051_a52radomeHtrInop m51 : 20|1@1+ (1,0) [0|1] "" GTW
 SG_ APS_sw051_unused m51 : 21|3@1+ (1,0) [0|1] "" GTW
 SG_ APS_sw051_SCUTemperature m51 : 24|8@1- (1,0) [-128|127] "" GTW
 SG_ APS_sw051_HWFail m51 : 32|1@1+ (1,0) [0|1] "" GTW
 SG_ APS_sw051_SGUFail m51 : 33|1@1+ (1,0) [0|1] "" GTW
 SG_ APS_sw051_unusedBits m51 : 34|6@1+ (1,0) [0|1] "" GTW
 SG_ APS_sw051_unusedB0 m51 : 40|8@1+ (1,0) [0|1] "" GTW
 SG_ APS_sw051_unusedW1 m51 : 48|16@1+ (1,0) [0|1] "" GTW
 SG_ APS_sw052_a07sensorBlinded m52 : 16|1@1+ (1,0) [0|1] "" GTW
 SG_ APS_sw052_sensorDirty m52 : 17|1@1+ (1,0) [0|1] "" GTW
 SG_ APS_sw052_HWFail m52 : 18|1@1+ (1,0) [0|1] "" GTW
 SG_ APS_sw052_overTemperature m52 : 19|1@1+ (1,0) [0|1] "" GTW
 SG_ APS_sw052_underTemperature m52 : 20|1@1+ (1,0) [0|1] "" GTW
 SG_ APS_sw052_chirpError m52 : 21|1@1+ (1,0) [0|1] "" GTW
 SG_ APS_sw052_rspError m52 : 22|1@1+ (1,0) [0|1] "" GTW
 SG_ APS_sw052_sensorBlocked m52 : 23|1@1+ (1,0) [0|1] "" GTW
 SG_ APS_sw053_a10canBusOff m53 : 16|1@1+ (1,0) [0|1] "" GTW
 SG_ APS_sw053_a11bdyMIA m53 : 17|1@1+ (1,0) [0|1] "" GTW
 SG_ APS_sw053_a12espMIA m53 : 18|1@1+ (1,0) [0|1] "" GTW
 SG_ APS_sw053_a13gtwMIA m53 : 19|1@1+ (1,0) [0|1] "" GTW
 SG_ APS_sw053_a14sccmMIA m53 : 20|1@1+ (1,0) [0|1] "" GTW
 SG_ APS_sw053_a15adasMIA m53 : 21|1@1+ (1,0) [0|1] "" GTW
 SG_ APS_sw053_a16bdyInvalidCount m53 : 22|1@1+ (1,0) [0|1] "" GTW
 SG_ APS_sw053_a17adasInvalidCount m53 : 23|1@1+ (1,0) [0|1] "" GTW
 SG_ APS_sw053_a18espInvalidCount m53 : 24|1@1+ (1,0) [0|1] "" GTW
 SG_ APS_sw053_a19sccmInvalidCount m53 : 25|1@1+ (1,0) [0|1] "" GTW
 SG_ APS_sw053_a20bdyInvalidChkSm m53 : 26|1@1+ (1,0) [0|1] "" GTW
 SG_ APS_sw053_a21espInvalidChkSm m53 : 27|1@1+ (1,0) [0|1] "" GTW
 SG_ APS_sw053_a22sccmInvalidChkSm m53 : 28|1@1+ (1,0) [0|1] "" GTW
 SG_ APS_sw053_a23sccmInvalidChkSm m53 : 29|1@1+ (1,0) [0|1] "" GTW
 SG_ APS_sw053_a24absValidity m53 : 30|1@1+ (1,0) [0|1] "" GTW
 SG_ APS_sw053_a25ambTValidity m53 : 31|1@1+ (1,0) [0|1] "" GTW
 SG_ APS_sw053_a26brakeValidity m53 : 32|1@1+ (1,0) [0|1] "" GTW
 SG_ APS_sw053_a27CntryCdValidity m53 : 33|1@1+ (1,0) [0|1] "" GTW
 SG_ APS_sw053_a28espValidity m53 : 34|1@1+ (1,0) [0|0] "" GTW
 SG_ APS_sw053_a29longAccOffValidity m53 : 35|1@1+ (1,0) [0|1] "" GTW
 SG_ APS_sw053_a30longAccValidity m53 : 36|1@1+ (1,0) [0|1] "" GTW
 SG_ APS_sw053_a31odoValidity m53 : 37|1@1+ (1,0) [0|1] "" GTW
 SG_ APS_sw053_a32gearValidity m53 : 38|1@1+ (1,0) [0|1] "" GTW
 SG_ APS_sw053_a33steerAngValidity m53 : 39|1@1+ (1,0) [0|1] "" GTW
 SG_ APS_sw053_a34steerAngSpdValidity m53 : 40|1@1+ (1,0) [0|1] "" GTW
 SG_ APS_sw053_a35indctrValidity m53 : 41|1@1+ (1,0) [0|1] "" GTW
 SG_ APS_sw053_a36vehStndStllValidty m53 : 42|1@1+ (1,0) [0|1] "" GTW
 SG_ APS_sw053_a37vinValidity m53 : 43|1@1+ (1,0) [0|1] "" GTW
 SG_ APS_sw053_a38whlRotValidity m53 : 44|1@1+ (1,0) [0|1] "" GTW
 SG_ APS_sw053_a39whlSpdValidity m53 : 45|1@1+ (1,0) [0|1] "" GTW
 SG_ APS_sw053_a40whlStndStllValidty m53 : 46|1@1+ (1,0) [0|1] "" GTW
 SG_ APS_sw053_a41wiperValidity m53 : 47|1@1+ (1,0) [0|1] "" GTW
 SG_ APS_sw053_a42xwdValidity m53 : 48|1@1+ (1,0) [0|1] "" GTW
 SG_ APS_sw053_a43yawOffValidity m53 : 49|1@1+ (1,0) [0|1] "" GTW
 SG_ APS_sw053_a44yawValidity m53 : 50|1@1+ (1,0) [0|1] "" GTW
 SG_ APS_sw053_a48steerAngOffSanity m53 : 51|1@1+ (1,0) [0|1] "" GTW
 SG_ APS_sw053_a49tireSizeSanity m53 : 52|1@1+ (1,0) [0|1] "" GTW
 SG_ APS_sw053_a50velocitySanity m53 : 53|1@1+ (1,0) [0|1] "" GTW
 SG_ APS_sw053_a51yawSanity m53 : 54|1@1+ (1,0) [0|1] "" GTW
 SG_ APS_sw053_a53espmodValidity m53 : 55|1@1+ (1,0) [0|1] "" GTW
 SG_ APS_sw053_a54gtwmodValidity m53 : 56|1@1+ (1,0) [0|1] "" GTW
 SG_ APS_sw053_a55stwmodValidity m53 : 57|1@1+ (1,0) [0|1] "" GTW
 SG_ APS_sw053_a56bcmodValidity m53 : 58|1@1+ (1,0) [0|1] "" GTW
 SG_ APS_sw053_a57dimodValidity m53 : 59|1@1+ (1,0) [0|1] "" GTW
 SG_ APS_sw053_a59drmiInvalidChkSm m53 : 60|1@1+ (1,0) [0|1] "" GTW
 SG_ APS_sw053_a60drmiInvalidCount m53 : 61|1@1+ (1,0) [0|1] "" GTW
 SG_ APS_sw053_a61radPositionMismatch m53 : 62|1@1+ (1,0) [0|1] "" GTW
 SG_ APS_sw053_a62strRackMismatch m53 : 63|1@1+ (1,0) [0|1] "" GTW
 SG_ APS_sw054_Autofix_cnvrgnceStatus m54 : 16|8@1+ (1,0) [0|0] "" GTW
 SG_ APS_sw054_Autofix_horizon m54 : 24|8@1+ (1,0) [0|0] "" GTW
 SG_ APS_sw054_Autofix_yaw m54 : 32|8@1+ (1,0) [0|0] "" GTW
 SG_ APS_sw054_unusedByte m54 : 40|8@1+ (1,0) [0|0] "" GTW
 SG_ APS_sw054_unusedW0 m54 : 48|16@1+ (1,0) [0|0] "" GTW
 SG_ APS_sw055_detectedRadcVersion m55 : 16|32@1+ (1,0) [0|0] "" GTW
 SG_ APS_sw055_expectedCrcLsw m55 : 48|16@1+ (1,0) [0|0] "" GTW
 SG_ APS_sw056_diMia m56 : 16|8@1+ (1,0) [0|1] "" GTW
 SG_ APS_sw056_unusedByte m56 : 24|8@1+ (1,0) [0|0] "" GTW
 SG_ APS_sw056_espControl m56 : 32|1@1+ (1,0) [0|0] "" GTW
 SG_ APS_sw056_state2 m56 : 33|1@1+ (1,0) [0|0] "" GTW
 SG_ APS_sw056_state m56 : 34|1@1+ (1,0) [0|0] "" GTW
 SG_ APS_sw056_torque1 m56 : 35|1@1+ (1,0) [0|0] "" GTW
 SG_ APS_sw056_torque2 m56 : 36|1@1+ (1,0) [0|0] "" GTW
 SG_ APS_sw057_chCtrlMia m57 : 32|1@1+ (1,0) [0|1] "" GTW
 SG_ APS_sw057_csaOfframpCurvMia m57 : 33|1@1+ (1,0) [0|1] "" GTW
 SG_ APS_sw057_csaRoadCurvMia m57 : 34|1@1+ (1,0) [0|1] "" GTW
 SG_ APS_sw057_dasControlMia m57 : 35|1@1+ (1,0) [0|1] "" GTW
 SG_ APS_sw057_dasMapDataMia m57 : 36|1@1+ (1,0) [0|1] "" GTW
 SG_ APS_sw057_gpsVehSpeedMia m57 : 37|1@1+ (1,0) [0|1] "" GTW
 SG_ APS_sw057_locStatusMia m57 : 38|1@1+ (1,0) [0|1] "" GTW
 SG_ APS_sw057_radarMapDataMia m57 : 39|1@1+ (1,0) [0|1] "" GTW
 SG_ APS_sw057_roadCurvMia m57 : 40|1@1+ (1,0) [0|1] "" GTW
 SG_ APS_sw057_solarDataMia m57 : 41|1@1+ (1,0) [0|1] "" GTW
 SG_ APS_sw057_telemetryControlMia m57 : 42|1@1+ (1,0) [0|1] "" GTW
 SG_ APS_sw057_statusMia m57 : 43|1@1+ (1,0) [0|1] "" GTW
 SG_ APS_sw057_autopilotControlMia m57 : 44|1@1+ (1,0) [0|1] "" GTW
 SG_ APS_sw057_phoneLocStatusMia m57 : 45|1@1+ (1,0) [0|1] "" GTW
 SG_ APS_sw058_epbMia m58 : 16|8@1+ (1,0) [0|1] "" GTW
 SG_ APS_sw058_unusedByte m58 : 24|8@1+ (1,0) [0|0] "" GTW
 SG_ APS_sw058_status m58 : 32|1@1+ (1,0) [0|0] "" GTW
 SG_ APS_sw059_parkMia m59 : 16|8@1+ (1,0) [0|1] "" GTW
 SG_ APS_sw059_unusedByte m59 : 24|8@1+ (1,0) [0|0] "" GTW
 SG_ APS_sw059_oloDict m59 : 32|1@1+ (1,0) [0|0] "" GTW
 SG_ APS_sw059_oocStatus m59 : 33|1@1+ (1,0) [0|0] "" GTW
 SG_ APS_sw059_pasFrontMiddle m59 : 34|1@1+ (1,0) [0|0] "" GTW
 SG_ APS_sw059_pasRearMiddle m59 : 35|1@1+ (1,0) [0|0] "" GTW
 SG_ APS_sw059_pscStatus m59 : 36|1@1+ (1,0) [0|0] "" GTW
 SG_ APS_sw059_pscVehSlot m59 : 37|1@1+ (1,0) [0|0] "" GTW
 SG_ APS_sw059_sdiFront m59 : 38|1@1+ (1,0) [0|0] "" GTW
 SG_ APS_sw059_sdiRear m59 : 39|1@1+ (1,0) [0|0] "" GTW
 SG_ APS_sw059_sensorStatusFront m59 : 40|1@1+ (1,0) [0|0] "" GTW
 SG_ APS_sw059_sensorStatusRear m59 : 41|1@1+ (1,0) [0|0] "" GTW
 SG_ APS_sw059_status2 m59 : 42|1@1+ (1,0) [0|0] "" GTW
 SG_ APS_sw059_status m59 : 43|1@1+ (1,0) [0|0] "" GTW
 SG_ APS_sw060_targetDist m60 : 16|9@1+ (0.2,0) [0|102.2] "m" GTW
 SG_ APS_sw060_targetRelSpeed m60 : 25|9@1+ (0.0625,-31) [-31|0.9375] "m/s" GTW
 SG_ APS_sw060_targetOverlap m60 : 34|6@1+ (0.1,0) [0|6.3] "m" GTW
 SG_ APS_sw060_hostSpeed m60 : 40|7@1+ (2,0) [0|254] "kph" GTW
 SG_ APS_sw060_hostLongAccel m60 : 47|4@1+ (1,-7.5) [-7.5|7.5] "m/s^2" GTW
 SG_ APS_sw060_RadarAssociationAge m60 : 51|4@1+ (100,0) [0|1500] "ms" GTW
 SG_ APS_sw060_driverPressedBrakePed m60 : 55|1@1+ (1,0) [0|1] "" GTW
 SG_ APS_sw060_overrideAccelPed m60 : 56|1@1+ (1,0) [0|1] "" GTW
 SG_ APS_sw060_overrideBlinker m60 : 57|1@1+ (1,0) [0|1] "" GTW
 SG_ APS_sw060_overrideBrake m60 : 58|1@1+ (1,0) [0|1] "" GTW
 SG_ APS_sw060_overrideSteer m60 : 59|1@1+ (1,0) [0|1] "" GTW
 SG_ APS_sw060_collisionWarningSource m60 : 60|3@1+ (1,0) [0|7] "" GTW
 SG_ APS_sw060_accActive m60 : 63|1@1+ (1,0) [0|1] "" GTW
 SG_ APS_sw061_airSuspensionMia m61 : 16|8@1+ (1,0) [0|1] "" GTW
 SG_ APS_sw061_unusedByte m61 : 24|8@1+ (1,0) [0|0] "" GTW
 SG_ APS_sw061_asdA2 m61 : 32|1@1+ (1,0) [0|0] "" GTW
 SG_ APS_sw061_states m61 : 33|1@1+ (1,0) [0|0] "" GTW
 SG_ APS_sw062_HorizontalMisalignment m62 : 16|16@1+ (0.00137332,-45) [-45|45.0005262] "deg" GTW
 SG_ APS_sw062_VerticalMisalignment m62 : 32|10@1+ (0.087977,-45) [-45|45.000471] "deg" GTW
 SG_ APS_sw062_unusedBits m62 : 42|6@1+ (1,0) [0|1] "" GTW
 SG_ APS_sw062_VmaPlausibility m62 : 48|16@1+ (1.52587890625005E-05,0) [0|0.99998474121097] "" GTW
 SG_ APS_sw063_expectedMajorVer m63 : 16|8@1+ (1,0) [0|255] "" GTW
 SG_ APS_sw063_detectedMajorVer m63 : 24|8@1+ (1,0) [0|255] "" GTW
 SG_ APS_sw063_expectedMinorVer m63 : 32|8@1+ (1,0) [0|255] "" GTW
 SG_ APS_sw063_detectedMinorVer m63 : 40|8@1+ (1,0) [0|255] "" GTW
 SG_ APS_sw063_expectedSubMinorVer m63 : 48|8@1+ (1,0) [0|255] "" GTW
 SG_ APS_sw063_detectedSubMinorVer m63 : 56|8@1+ (1,0) [0|255] "" GTW
 SG_ APS_sw064_epasMia m64 : 16|8@1+ (1,0) [0|1] "" GTW
 SG_ APS_sw064_unusedByte m64 : 24|8@1+ (1,0) [0|0] "" GTW
 SG_ APS_sw064_sysStatus m64 : 32|1@1+ (1,0) [0|0] "" GTW
 SG_ APS_sw065_app_mobileye_status m65 : 16|8@1+ (1,0) [0|21] "" GTW
 SG_ APS_sw065_mobileye_main_state m65 : 24|8@1+ (1,0) [0|255] "" GTW
 SG_ APS_sw065_unusedW0 m65 : 32|16@1+ (1,0) [0|0] "" GTW
 SG_ APS_sw065_unusedW1 m65 : 48|16@1+ (1,0) [0|0] "" GTW
 SG_ APS_sw066_app_mobileye_status m66 : 16|8@1+ (1,0) [0|21] "" GTW
 SG_ APS_sw066_mobileye_main_state m66 : 24|8@1+ (1,0) [0|255] "" GTW
 SG_ APS_sw066_unusedW0 m66 : 32|16@1+ (1,0) [0|0] "" GTW
 SG_ APS_sw066_unusedW1 m66 : 48|16@1+ (1,0) [0|0] "" GTW
 SG_ APS_sw067_sccmSTW m67 : 16|14@1+ (0.1,-819.2) [-819.2|819] "deg" GTW
 SG_ APS_sw067_epasSTW m67 : 30|14@1+ (0.1,-819.2) [-819.2|819] "deg" GTW
 SG_ APS_sw067_vehSpeed m67 : 44|12@1+ (0.1,-50) [-50|359.6] "kph" GTW
 SG_ APS_sw067_offsetEstimator m67 : 56|8@1+ (0.1,-12.8) [-12.8|12.8] "deg" GTW
 SG_ APS_sw068_percentConsistency m68 : 16|10@1+ (0.1,0) [0|100] "%" GTW
 SG_ APS_sw068_virtualLaneSTW m68 : 32|14@1+ (0.1,-819.2) [-819.2|819.2] "deg" GTW
 SG_ APS_sw068_navigationSTW m68 : 48|14@1+ (0.1,-819.2) [-819.2|819.2] "deg" GTW
 SG_ APS_sw069_epasMia m69 : 16|1@1+ (1,0) [0|1] "" GTW
 SG_ APS_sw069_espMia m69 : 17|1@1+ (1,0) [0|1] "" GTW
 SG_ APS_sw069_parkMia m69 : 18|1@1+ (1,0) [0|1] "" GTW
 SG_ APS_sw069_sccmMia m69 : 19|1@1+ (1,0) [0|1] "" GTW
 SG_ APS_sw069_parkMismatch m69 : 20|1@1+ (1,0) [0|1] "" GTW
 SG_ APS_sw069_eacStatus m69 : 21|4@1+ (1,0) [0|1] "" GTW
 SG_ APS_sw069_diAPState m69 : 25|4@1+ (1,0) [0|1] "" GTW
 SG_ APS_sw069_parkCal m69 : 29|1@1+ (1,0) [0|1] "" GTW
 SG_ APS_sw069_torsionBar m69 : 32|12@1+ (0.01,-20.5) [-20.5|20.45] "Nm" GTW
 SG_ APS_sw069_roadClass m69 : 44|4@1+ (1,0) [0|15] "" GTW
 SG_ APS_sw069_drivingLaneLeft m69 : 48|8@1+ (1,0) [0|255] "" GTW
 SG_ APS_sw069_drivingLaneRight m69 : 56|8@1+ (1,0) [0|255] "" GTW
 SG_ APS_sw070_currTireFitment m70 : 16|3@1+ (1,0) [0|7] "" GTW
 SG_ APS_sw070_lastTireFitment m70 : 19|3@1+ (1,0) [0|7] "" GTW
 SG_ APS_sw070_diGear m70 : 22|3@1+ (1,0) [0|7] "" GTW
 SG_ APS_sw070_driveRail m70 : 25|1@1+ (1,0) [0|1] "" GTW
 SG_ APS_sw070_accRail m70 : 26|1@1+ (1,0) [0|1] "" GTW
 SG_ APS_sw070_temperature m70 : 32|8@1+ (0.5,-40) [-40|87.5] "C" GTW
 SG_ APS_sw070_currentSpeed m70 : 40|12@1+ (0.1,-204.7) [-204.7|204.8] "mph" GTW
 SG_ APS_sw071_selfParkType m71 : 16|4@1+ (1,0) [0|15] "" GTW
 SG_ APS_sw071_endPosX m71 : 20|10@1+ (0.05,-25.6) [-25.6|25.5] "m" GTW
 SG_ APS_sw071_endPosY m71 : 30|10@1+ (0.05,-25.6) [-25.6|25.5] "m" GTW
 SG_ APS_sw071_roadClass m71 : 40|3@1+ (1,0) [0|7] "" GTW
 SG_ APS_sw071_driverPresent m71 : 43|1@1+ (1,0) [0|1] "" GTW
 SG_ APS_sw071_airSuspension m71 : 44|3@1+ (1,0) [0|7] "" GTW
 SG_ APS_sw071_temperature m71 : 47|8@1+ (0.5,-40) [-40|87.5] "C" GTW
 SG_ APS_sw071_activationType m71 : 55|2@1+ (1,0) [0|3] "" GTW
 SG_ APS_sw072_vehicleX m72 : 16|10@1+ (0.05,-25.6) [-25.6|25.5] "m" GTW
 SG_ APS_sw072_vehicleY m72 : 26|10@1+ (0.05,-25.6) [-25.6|25.5] "m" GTW
 SG_ APS_sw072_vehicleHeading m72 : 36|10@1+ (0.005,-2.56) [-2.56|2.55] "rad" GTW
 SG_ APS_sw072_endDistance m72 : 46|8@1+ (1,0) [0|255] "cm" GTW
 SG_ APS_sw072_guidanceComplete m72 : 54|1@1+ (1,0) [0|1] "" GTW
 SG_ APS_sw072_guidanceRunaway m72 : 55|1@1+ (1,0) [0|1] "" GTW
 SG_ APS_sw072_guidanceTimer m72 : 56|1@1+ (1,0) [0|1] "" GTW
 SG_ APS_sw072_handlePress m72 : 57|1@1+ (1,0) [0|1] "" GTW
 SG_ APS_sw072_keyfobPress m72 : 58|1@1+ (1,0) [0|1] "" GTW
 SG_ APS_sw072_garageOpened m72 : 59|1@1+ (1,0) [0|1] "" GTW
 SG_ APS_sw072_userTimeout m72 : 60|1@1+ (1,0) [0|1] "" GTW
 SG_ APS_sw073_escalateLDWs m73 : 16|1@1+ (1,0) [0|1] "" GTW
 SG_ APS_sw073_silentEscalatedLDW m73 : 17|1@1+ (1,0) [0|1] "" GTW
 SG_ APS_sw073_escalateLDWreason m73 : 18|2@1+ (1,0) [0|3] "" GTW
 SG_ APS_sw073_rawMobileyeLDW m73 : 20|2@1+ (1,0) [0|3] "" GTW
 SG_ APS_sw073_freespaceLDW m73 : 22|2@1+ (1,0) [0|3] "" GTW
 SG_ APS_sw073_freespaceLeftC0 m73 : 24|8@1+ (0.1,-12.8) [-12.8|12.7] "m" GTW
 SG_ APS_sw073_freespaceRightC0 m73 : 32|8@1+ (0.1,-12.8) [-12.8|12.7] "m" GTW
 SG_ APS_sw073_freespaceLeftC1 m73 : 40|8@1+ (0.0016,-0.2) [-0.2|0.2] "rad" GTW
 SG_ APS_sw073_freespaceRightC1 m73 : 48|8@1+ (0.0016,-0.2) [-0.2|0.2] "rad" GTW
 SG_ APS_sw073_freespaceLeftFarZ m73 : 56|4@1+ (4,0) [0|60] "m" GTW
 SG_ APS_sw073_freespaceRightFarZ m73 : 60|4@1+ (4,0) [0|60] "m" GTW
 SG_ APS_sw074_ipsoDx m74 : 16|6@1+ (2,0) [0|126] "m" GTW
 SG_ APS_sw074_ipsoDy m74 : 22|6@1+ (0.1,-3.2) [-3.2|3.1] "m" GTW
 SG_ APS_sw074_ipsoDz m74 : 28|6@1+ (0.2,-6.4) [-6.4|6.2] "m" GTW
 SG_ APS_sw074_ipsoRCS m74 : 34|8@1+ (1,0) [0|255] "db" GTW
 SG_ APS_sw074_ipsoConfidence m74 : 42|6@1+ (2,0) [0|126] "percent" GTW
 SG_ APS_sw074_ipsowExist m74 : 48|5@1+ (1,0) [0|31] "" GTW
 SG_ APS_sw074_roadClass m74 : 54|3@1+ (1,0) [0|7] "" GTW
 SG_ APS_sw074_cruiseActive m74 : 57|1@1+ (1,0) [0|1] "" GTW
 SG_ APS_sw074_autopilotActive m74 : 58|1@1+ (1,0) [0|1] "" GTW
 SG_ APS_sw075_scMia m75 : 16|8@1+ (1,0) [0|255] "" GTW
 SG_ APS_sw075_unusedByte m75 : 24|8@1+ (1,0) [0|0] "" GTW
 SG_ APS_sw075_status m75 : 32|1@1+ (1,0) [0|0] "" GTW
 SG_ APS_sw076_targetDist m76 : 16|9@1+ (0.2,0) [0|102.2] "m" GTW
 SG_ APS_sw076_targetRelSpeed m76 : 25|9@1+ (0.0625,-31) [-31|0.9375] "m/s" GTW
 SG_ APS_sw076_targetOverlap m76 : 34|6@1+ (0.1,0) [0|6.3] "m" GTW
 SG_ APS_sw076_hostSpeed m76 : 40|8@1+ (1,0) [0|255] "kph" GTW
 SG_ APS_sw076_hostLongAccel m76 : 48|7@1+ (0.15625,-10) [-10|10] "m/s^2" GTW
 SG_ APS_sw076_driverPressedAccelPed m76 : 55|1@1+ (1,0) [0|1] "" GTW
 SG_ APS_sw076_driverPressedBrakePed m76 : 56|1@1+ (1,0) [0|1] "" GTW
 SG_ APS_sw076_overrideAccelPed m76 : 57|1@1+ (1,0) [0|1] "" GTW
 SG_ APS_sw076_overrideBlinker m76 : 58|1@1+ (1,0) [0|1] "" GTW
 SG_ APS_sw076_overrideBrake m76 : 59|1@1+ (1,0) [0|1] "" GTW
 SG_ APS_sw076_overrideSteer m76 : 60|1@1+ (1,0) [0|1] "" GTW
 SG_ APS_sw076_fcmModeAtEvent m76 : 61|2@1+ (1,0) [0|3] "" GTW
 SG_ APS_sw076_accActive m76 : 63|1@1+ (1,0) [0|1] "" GTW
 SG_ APS_sw077_oocDistance m77 : 16|9@1+ (1,0) [0|512] "cm" GTW
 SG_ APS_sw077_oocConfidence m77 : 25|7@1+ (1,0) [0|100] "%" GTW
 SG_ APS_sw077_oocCollisionSide m77 : 32|3@1+ (1,0) [0|7] "" GTW
 SG_ APS_sw077_oocHeight m77 : 35|2@1+ (1,0) [0|4] "" GTW
 SG_ APS_sw077_vehicleSpeed m77 : 37|10@1+ (0.05,-25) [-25|26.15] "MPH" GTW
 SG_ APS_sw077_oocUntrackedTime m77 : 48|6@1+ (0.1,0) [0|6.3] "s" GTW
 SG_ APS_sw077_oocOffCourseDist_cm m77 : 54|10@1- (1,0) [-512|511] "" GTW
 SG_ APS_sw078_camCipv_dx m78 : 16|8@1+ (0.2,0) [0|51] "m" GTW
 SG_ APS_sw078_ttc m78 : 24|8@1+ (0.02,0) [0|5.11] "seconds" GTW
 SG_ APS_sw078_radarTarg5_dx m78 : 32|8@1+ (0.0625,0) [0|15.9375] "m" GTW
 SG_ APS_sw078_radarTarg5_VxRel m78 : 40|8@1+ (0.2,-25.6) [-25.6|25.4] "m/s" GTW
 SG_ APS_sw078_radarTarg1_dx m78 : 48|8@1+ (0.0625,0) [0|15.9375] "m" GTW
 SG_ APS_sw078_radarTarg1_VxRel m78 : 56|8@1+ (0.2,-25.6) [-25.6|25.4] "m/s" GTW
 SG_ APS_sw080_sensors_healty_check m80 : 16|1@1+ (1,0) [0|1] "" GTW
 SG_ APS_sw080_dist_travelled_check m80 : 17|1@1+ (1,0) [0|1] "" GTW
 SG_ APS_sw080_road_class_check m80 : 18|1@1+ (1,0) [0|1] "" GTW
 SG_ APS_sw080_stw_angle_check m80 : 19|1@1+ (1,0) [0|1] "" GTW
 SG_ APS_sw080_rad_tar_5_check m80 : 20|1@1+ (1,0) [0|1] "" GTW
 SG_ APS_sw080_ultrasonic_obs_check m80 : 21|1@1+ (1,0) [0|1] "" GTW
 SG_ APS_sw080_freespace_check m80 : 22|1@1+ (1,0) [0|1] "" GTW
 SG_ APS_sw080_pedestrian_check m80 : 23|1@1+ (1,0) [0|1] "" GTW
 SG_ APS_sw080_rad_tar_5_dist m80 : 24|6@1+ (1,0) [0|63] "m" GTW
 SG_ APS_sw080_stw_angle_deg m80 : 32|8@1+ (1,0) [0|255] "deg" GTW
 SG_ APS_sw080_road_class m80 : 40|3@1+ (1,0) [0|7] "" GTW
 SG_ APS_sw080_ego_speed m80 : 43|5@1+ (1,0) [0|31] "mph" GTW
 SG_ APS_sw080_cipv_valid m80 : 48|1@1+ (1,0) [0|1] "" GTW
 SG_ APS_sw080_min_speed_check m80 : 49|1@1+ (1,0) [0|1] "" GTW
 SG_ APS_sw080_cruise_lever_state m80 : 50|3@1+ (1,0) [0|7] "" GTW
 SG_ APS_sw080_cruise_speed_check m80 : 53|1@1+ (1,0) [0|1] "" GTW
 SG_ APS_sw081_radarDistance m81 : 16|8@1+ (0.0625,0) [0|15.9375] "m" GTW
 SG_ APS_sw081_radarTTC m81 : 24|8@1+ (0.02,0) [0|5.11] "seconds" GTW
 SG_ APS_sw081_cameraDistance m81 : 32|8@1+ (0.0625,0) [0|15.9375] "m" GTW
 SG_ APS_sw081_cameraTTC m81 : 40|8@1+ (0.02,0) [0|5.11] "seconds" GTW
 SG_ APS_sw081_pedalPosition m81 : 48|7@1+ (1,0) [0|127] "%" GTW
 SG_ APS_sw082_L_VL m82 : 16|8@1+ (0.05,-6.4) [-6.4|6.35] "m" GTW
 SG_ APS_sw082_R_VL m82 : 24|8@1+ (0.05,-6.4) [-6.4|6.35] "m" GTW
 SG_ APS_sw082_L_Lane m82 : 32|8@1+ (0.05,-6.4) [-6.4|6.35] "m" GTW
 SG_ APS_sw082_R_Lane m82 : 40|8@1+ (0.05,-6.4) [-6.4|6.35] "m" GTW
 SG_ APS_sw082_road_class m82 : 48|3@1+ (1,0) [0|7] "" GTW
 SG_ APS_sw083_Targ5_RCS m83 : 16|16@1+ (0.0039063096,0) [0|256] "dB" GTW
 SG_ APS_sw083_Targ5_dx m83 : 32|12@1+ (0.0625,0) [0|255.9375] "m" GTW
 SG_ APS_sw083_Targ5_dz m83 : 44|6@1+ (0.25,-5) [-5|10.75] "m" GTW
 SG_ APS_sw083_Targ5_wObj m83 : 50|5@1+ (0.03125,0) [0|0.96875] "%" GTW
 SG_ APS_sw083_Targ5_wNonObj m83 : 55|5@1+ (0.03125,0) [0|0.96875] "%" GTW
 SG_ APS_sw084_ipsoTTC m84 : 16|8@1+ (0.02,0) [0|5.11] "seconds" GTW
 SG_ APS_sw084_ipsoDx m84 : 24|8@1+ (0.1,0) [0|25.5] "m" GTW
 SG_ APS_sw084_ipsoRCS m84 : 32|8@1+ (1,0) [0|255] "" GTW
 SG_ APS_sw084_ipsoDy m84 : 40|8@1+ (0.1,-12.6) [-12.6|12.8] "m" GTW
 SG_ APS_sw085_radarDistance m85 : 16|8@1+ (0.0625,0) [0|15.9375] "m" GTW
 SG_ APS_sw085_radarTTC m85 : 24|8@1+ (0.02,0) [0|5.11] "seconds" GTW
 SG_ APS_sw085_roadClass m85 : 32|3@1+ (1,0) [0|7] "" GTW
 SG_ APS_sw085_leftLaneExist m85 : 36|6@1+ (2,0) [0|128] "%" GTW
 SG_ APS_sw085_rightLaneExist m85 : 42|6@1+ (2,0) [0|128] "%" GTW
 SG_ APS_sw085_averageSpeedHist m85 : 48|6@1+ (0.25,0) [0|16] "mps" GTW
 SG_ APS_sw085_freeSpaceC0Left m85 : 54|5@1+ (1,-15) [-15|16] "m" GTW
 SG_ APS_sw085_freeSpaceC0Right m85 : 59|5@1+ (1,-15) [-15|16] "m" GTW
 SG_ APS_sw086_distanceException m86 : 16|8@1+ (1,-90) [90|165] "m" GTW
 SG_ APS_sw086_distanceEllipse m86 : 24|8@1+ (0.5,0) [0|127.5] "m" GTW
 SG_ APS_sw086_ellipseWidth m86 : 32|8@1+ (0.1,0) [0|25.5] "m" GTW
 SG_ APS_sw086_ellipseOverlap m86 : 40|8@1+ (0.1,-12.5) [-12.5|12.5] "m" GTW
 SG_ APS_sw086_ellipseAge m86 : 48|3@1+ (1,0) [0|7] "" GTW
 SG_ APS_sw086_activeBraking m86 : 51|1@1+ (1,0) [0|1] "" GTW
 SG_ APS_sw086_cipvValid m86 : 52|1@1+ (1,0) [0|1] "" GTW
 SG_ APS_sw086_mcvlValid m86 : 53|1@1+ (1,0) [0|1] "" GTW
 SG_ APS_sw086_mcvrValid m86 : 54|1@1+ (1,0) [0|1] "" GTW
 SG_ APS_sw086_roadClass m86 : 55|3@1+ (1,0) [0|7] "" GTW
 SG_ APS_sw086_ipsoApproved m86 : 58|1@1+ (1,0) [0|1] "" GTW
 SG_ APS_sw086_controlledAccess m86 : 59|1@1+ (1,0) [0|1] "" GTW
 SG_ APS_sw086_driverHandsOn m86 : 60|1@1+ (1,0) [0|1] "" GTW
 SG_ APS_sw103_objectDx m103 : 16|8@1+ (0.5,0) [0|127.5] "m" GTW
 SG_ APS_sw103_objectRCS m103 : 24|8@1+ (1,0) [0|255] "" GTW
 SG_ APS_sw103_objectDy m103 : 32|8@1+ (0.5,-15.5) [-15.5|16] "m" GTW
 SG_ APS_sw103_objectDz m103 : 40|8@1+ (0.25,-5) [-5|10.75] "m" GTW
 SG_ APS_sw103_distanceEllipse m103 : 48|8@1+ (0.5,0) [0|127.5] "m" GTW
 SG_ APS_sw103_ipsoApproved m103 : 56|1@1+ (1,0) [0|1] "" GTW
 SG_ APS_sw103_constArea m103 : 57|2@1+ (1,0) [0|3] "" GTW
 SG_ APS_sw103_radAlignment m103 : 59|5@1+ (0.015625,-0.2343) [-0.2343|0.25] "rad" GTW
 SG_ APS_sw106_torsionBarOffset m106 : 16|8@1+ (0.005,-0.64) [-0.64|0.63] "Nm" GTW
 SG_ APS_sw129_minThreshold m129 : 16|13@1+ (1,0) [0|4500] "mV" GTW
 SG_ APS_sw129_railID m129 : 29|6@1+ (1,0) [0|63] "" GTW
 SG_ APS_sw129_powerSequnceError m129 : 35|1@1+ (1,0) [0|1] "" GTW
 SG_ APS_sw129_maxThreshold m129 : 36|13@1+ (1,0) [50|5500] "mV" GTW
 SG_ APS_sw129_railControl m129 : 49|1@1+ (1,0) [0|1] "" GTW
 SG_ APS_sw129_currentVoltage m129 : 50|14@1+ (1,0) [0|6600] "mV" GTW
 SG_ APS_sw130_shouldBlockOkToPowerAp m130 : 16|1@1+ (1,0) [0|1] "" GTW
 SG_ APS_sw130_shouldForceApPowerOn m130 : 17|1@1+ (1,0) [0|1] "" GTW
 SG_ APS_sw130_tempSensorId m130 : 18|6@1+ (1,0) [0|4] "" GTW
 SG_ APS_sw130_minThreshold m130 : 24|8@1- (1,0) [-128|127] "degC" GTW
 SG_ APS_sw130_maxThreshold m130 : 32|8@1- (1,0) [-128|127] "degC" GTW
 SG_ APS_sw130_currentTemperature m130 : 40|8@1- (1,0) [-128|127] "degC" GTW
 SG_ APS_sw130_unusedWord m130 : 48|16@1+ (1,0) [0|0] "" GTW
 SG_ APS_sw131_trapClass m131 : 16|3@1+ (1,0) [0|7] "" GTW
 SG_ APS_sw131_trapTIN m131 : 19|3@1+ (1,0) [0|1] "" GTW
 SG_ APS_sw131_trapAddr m131 : 24|32@1+ (1,0) [0|1] "" GTW
 SG_ APS_sw131_trapTaskPrio m131 : 56|8@1+ (1,0) [0|16] "" GTW
 SG_ APS_sw132_mismatchType m132 : 16|8@1+ (1,0) [0|1] "" GTW
 SG_ APS_sw132_expectedHash m132 : 24|16@1+ (1,0) [0|65535] "" GTW
 SG_ APS_sw132_actualHash m132 : 40|24@1+ (1,0) [0|16777215] "" GTW
 SG_ APS_sw133_switchInReset m133 : 16|1@1+ (1,0) [0|0] "" GTW
 SG_ APS_sw133_failedInitStep m133 : 17|8@1+ (1,0) [0|0] "" GTW
 SG_ APS_sw133_unused m133 : 25|39@1+ (1,0) [0|0] "" GTW
 SG_ APS_sw134_appCameraLux m134 : 16|1@1+ (1,0) [0|1] "" GTW
 SG_ APS_sw134_appCamCalibStatus m134 : 17|1@1+ (1,0) [0|1] "" GTW
 SG_ APS_sw134_appInfo m134 : 18|1@1+ (1,0) [0|1] "" GTW
 SG_ APS_sw134_appStatus m134 : 19|1@1+ (1,0) [0|1] "" GTW
 SG_ APS_sw134_dasBodyControls m134 : 20|1@1+ (1,0) [0|1] "" GTW
 SG_ APS_sw134_dasControl m134 : 21|1@1+ (1,0) [0|1] "" GTW
 SG_ APS_sw134_dasIntSafetyFront m134 : 22|1@1+ (1,0) [0|1] "" GTW
 SG_ APS_sw134_dasLanes m134 : 23|1@1+ (1,0) [0|1] "" GTW
 SG_ APS_sw134_dasObject m134 : 24|1@1+ (1,0) [0|1] "" GTW
 SG_ APS_sw134_dasPscControl m134 : 25|1@1+ (1,0) [0|1] "" GTW
 SG_ APS_sw134_dasStatus2 m134 : 26|1@1+ (1,0) [0|1] "" GTW
 SG_ APS_sw134_dasStatus m134 : 27|1@1+ (1,0) [0|1] "" GTW
 SG_ APS_sw134_dasSteeringControl m134 : 28|1@1+ (1,0) [0|1] "" GTW
 SG_ APS_sw134_dasVisualDebug m134 : 29|1@1+ (1,0) [0|1] "" GTW
 SG_ APS_sw134_dasSteeringControlPty m134 : 30|1@1+ (1,0) [0|1] "" GTW
 SG_ APS_sw134_dasChNm m134 : 31|1@1+ (1,0) [0|1] "" GTW
 SG_ APS_sw134_appSummon m134 : 32|1@1+ (1,0) [0|1] "" GTW
 SG_ APS_sw134_appEnvironment m134 : 33|1@1+ (1,0) [0|1] "" GTW
 SG_ APS_sw134_dasControlPt m134 : 34|1@1+ (1,0) [0|1] "" GTW
 SG_ APS_sw134_dasLongControlPt m134 : 35|1@1+ (1,0) [0|1] "" GTW
 SG_ APS_sw134_dasStatusPt m134 : 36|1@1+ (1,0) [0|1] "" GTW
 SG_ APS_sw134_dasStatus2Pt m134 : 37|1@1+ (1,0) [0|1] "" GTW
 SG_ APS_sw134_timeSinceLastMsg m134 : 48|16@1+ (1,0) [0|65535] "ms" GTW
 SG_ APS_sw135_appCriticalReason m135 : 16|4@1+ (1,0) [0|1] "" GTW
 SG_ APS_sw136_gpsCommIrrecoverable m136 : 16|1@1+ (1,0) [0|0] "" GTW
 SG_ APS_sw136_fusionIrrecoverable m136 : 17|1@1+ (1,0) [0|0] "" GTW
 SG_ APS_sw136_antennaUnplugged m136 : 18|1@1+ (1,0) [0|0] "" GTW
 SG_ APS_sw136_badgpsfix m136 : 19|1@1+ (1,0) [0|0] "" GTW
 SG_ APS_sw137_gpsCommMissing m137 : 16|1@1+ (1,0) [0|0] "" GTW
 SG_ APS_sw137_gpsJunkData m137 : 17|1@1+ (1,0) [0|0] "" GTW
 SG_ APS_sw137_gpsNMEAmissing m137 : 18|1@1+ (1,0) [0|0] "" GTW
 SG_ APS_sw137_gpsUBXmissing m137 : 19|1@1+ (1,0) [0|0] "" GTW
 SG_ APS_sw137_fusionModeDisabled m137 : 20|1@1+ (1,0) [0|0] "" GTW
 SG_ APS_sw137_gpsCfgFail m137 : 21|1@1+ (1,0) [0|0] "" GTW
 SG_ APS_sw137_esfStatusMsgMIA m137 : 22|1@1+ (1,0) [0|0] "" GTW
 SG_ APS_sw137_wheelTickCfgMissmatch m137 : 23|1@1+ (1,0) [0|0] "" GTW
 SG_ APS_sw137_exitTransportMode m137 : 24|1@1+ (1,0) [0|0] "" GTW
 SG_ APS_sw137_satRejectionTimeout m137 : 25|1@1+ (1,0) [0|0] "" GTW
 SG_ APS_sw138_cfgBufNull m138 : 16|1@1+ (1,0) [0|0] "" GTW
 SG_ APS_sw138_invalidID m138 : 17|1@1+ (1,0) [0|0] "" GTW
 SG_ APS_sw138_gpsBufferOverflow m138 : 18|1@1+ (1,0) [0|0] "" GTW
 SG_ APS_sw138_navx5CfgFailed m138 : 19|1@1+ (1,0) [0|0] "" GTW
 SG_ APS_sw138_mcuNMEAmsgUDPinvalid m138 : 20|1@1+ (1,0) [0|0] "" GTW
 SG_ APS_sw138_mcuDbgMsgInvalid m138 : 21|1@1+ (1,0) [0|0] "" GTW
 SG_ APS_sw138_mcuDbgMsgTooBig m138 : 22|1@1+ (1,0) [0|0] "" GTW
 SG_ APS_sw138_mcuFwdNMEAfail m138 : 23|1@1+ (1,0) [0|0] "" GTW
 SG_ APS_sw138_NMEAinvalidChecksum m138 : 24|1@1+ (1,0) [0|0] "" GTW
 SG_ APS_sw138_unexpectedNMEAmsg m138 : 25|1@1+ (1,0) [0|0] "" GTW
 SG_ APS_sw138_UARTbusFull m138 : 26|1@1+ (1,0) [0|0] "" GTW
 SG_ APS_sw138_UARTframeError m138 : 27|1@1+ (1,0) [0|0] "" GTW
 SG_ APS_sw138_UBXrxFrameTooBig m138 : 28|1@1+ (1,0) [0|0] "" GTW
 SG_ APS_sw138_emptyValidNMEA m138 : 29|1@1+ (1,0) [0|0] "" GTW
 SG_ APS_sw138_invalidAsciiNMEA m138 : 30|1@1+ (1,0) [0|0] "" GTW
 SG_ APS_sw138_wheeltickUARTfault m138 : 31|1@1+ (1,0) [0|0] "" GTW
 SG_ APS_sw138_baudrateMismatch m138 : 32|1@1+ (1,0) [0|0] "" GTW
 SG_ APS_sw138_wheelTickInvalidSrc m138 : 33|1@1+ (1,0) [0|0] "" GTW
 SG_ APS_sw138_UARTparityError m138 : 34|1@1+ (1,0) [0|0] "" GTW
 SG_ APS_sw138_UARTrxFifoOverflow m138 : 35|1@1+ (1,0) [0|0] "" GTW
 SG_ APS_sw138_UARTrxFifoUnderflow m138 : 36|1@1+ (1,0) [0|0] "" GTW
 SG_ APS_sw138_UARTtxFifoOverflow m138 : 37|1@1+ (1,0) [0|0] "" GTW
 SG_ APS_sw138_esfWtMsgTimeout m138 : 38|1@1+ (1,0) [0|0] "" GTW
 SG_ APS_sw138_PFLASHReadError m138 : 39|1@1+ (1,0) [0|0] "" GTW
 SG_ APS_sw138_PFLASHWriteError m138 : 40|1@1+ (1,0) [0|0] "" GTW
 SG_ APS_sw138_gpsCfgNack m138 : 41|1@1+ (1,0) [0|0] "" GTW
 SG_ APS_sw138_gpsCfgIdFail m138 : 42|6@1+ (1,0) [0|63] "" GTW
 SG_ APS_sw138_gpsSetCfgNoAck m138 : 48|1@1+ (1,0) [0|0] "" GTW
 SG_ APS_sw138_gpsReadCfgNoResponse m138 : 49|1@1+ (1,0) [0|0] "" GTW
 SG_ APS_sw138_ubxErrorReported m138 : 50|1@1+ (1,0) [0|0] "" GTW
 SG_ APS_sw139_numMessagesRx m139 : 16|8@1+ (1,0) [0|255] "" GTW
 SG_ APS_sw139_numMessagesDropped m139 : 24|8@1+ (1,0) [0|255] "" GTW
 SG_ APS_sw139_overflowBus m139 : 32|4@1+ (1,0) [0|15] "" GTW
 SG_ APS_sw146_sysStatus m146 : 16|1@1+ (1,0) [0|1] "" GTW
 SG_ APS_sw151_apGpioState m151 : 16|2@1+ (1,0) [0|3] "" GTW
 SG_ APS_sw151_apWatchDogState m151 : 18|3@1+ (1,0) [0|7] "" GTW
 SG_ APS_sw151_diGear m151 : 21|3@1+ (1,0) [0|7] "" GTW
 SG_ APS_sw151_recoveryPathway m151 : 24|2@1+ (1,0) [0|3] "" GTW
 SG_ APS_sw151_parkerType m151 : 26|1@1+ (1,0) [0|1] "" GTW
 SG_ APS_sw152_fusionStatus m152 : 16|2@1+ (1,0) [0|3] "" GTW
 SG_ APS_sw153_eacInhibitReason m153 : 16|3@1+ (1,0) [0|6] "" GTW
 SG_ APS_sw153_eacInternalState m153 : 19|3@1+ (1,0) [0|5] "" GTW
 SG_ APS_sw154_ethSwitchState m154 : 16|1@1+ (1,0) [0|3] "" GTW
 SG_ APS_sw155_InUnicastError m155 : 17|1@1+ (1,0) [0|1] "" GTW
 SG_ APS_sw155_UDPRecvError m155 : 18|1@1+ (1,0) [0|1] "" GTW
 SG_ APS_sw155_UDPMiscError m155 : 19|1@1+ (1,0) [0|1] "" GTW
 SG_ APS_sw155_UDPRTEError m155 : 20|1@1+ (1,0) [0|1] "" GTW
 SG_ APS_sw155_UDPDropError m155 : 21|1@1+ (1,0) [0|1] "" GTW
 SG_ APS_sw155_UDPCheckError m155 : 22|1@1+ (1,0) [0|1] "" GTW
 SG_ APS_sw155_UDPMemError m155 : 23|1@1+ (1,0) [0|1] "" GTW
 SG_ APS_sw155_UDPProtoError m155 : 25|1@1+ (1,0) [0|1] "" GTW
 SG_ APS_sw155_IPRecvError m155 : 26|1@1+ (1,0) [0|1] "" GTW
 SG_ APS_sw155_IPMiscError m155 : 27|1@1+ (1,0) [0|1] "" GTW
 SG_ APS_sw155_IPRTEError m155 : 28|1@1+ (1,0) [0|1] "" GTW
 SG_ APS_sw155_IPDropError m155 : 29|1@1+ (1,0) [0|1] "" GTW
 SG_ APS_sw155_IPCheckError m155 : 30|1@1+ (1,0) [0|1] "" GTW
 SG_ APS_sw155_IPMemError m155 : 31|1@1+ (1,0) [0|1] "" GTW
 SG_ APS_sw155_IPProtoError m155 : 33|1@1+ (1,0) [0|1] "" GTW
 SG_ APS_sw156_LWIPAssertLine m156 : 16|16@1+ (1,0) [0|65535] "" GTW
 SG_ APS_sw158_apbInfo m158 : 16|1@1+ (1,0) [0|1] "" GTW
 SG_ APS_sw158_apbStatus m158 : 17|1@1+ (1,0) [0|1] "" GTW
 SG_ APS_sw158_dasBodyControlsVEH m158 : 18|1@1+ (1,0) [0|1] "" GTW
 SG_ APS_sw158_dasControl m158 : 19|1@1+ (1,0) [0|1] "" GTW
 SG_ APS_sw158_dasControlPty m158 : 20|1@1+ (1,0) [0|1] "" GTW
 SG_ APS_sw158_dasIntSafetyFrontPty m158 : 21|1@1+ (1,0) [0|1] "" GTW
 SG_ APS_sw158_dasLanes m158 : 22|1@1+ (1,0) [0|1] "" GTW
 SG_ APS_sw158_dasObject m158 : 23|1@1+ (1,0) [0|1] "" GTW
 SG_ APS_sw158_dasPscControl m158 : 24|1@1+ (1,0) [0|1] "" GTW
 SG_ APS_sw158_dasStatus m158 : 25|1@1+ (1,0) [0|1] "" GTW
 SG_ APS_sw158_dasStatus2 m158 : 26|1@1+ (1,0) [0|1] "" GTW
 SG_ APS_sw158_dasSteeringControl m158 : 27|1@1+ (1,0) [0|1] "" GTW
 SG_ APS_sw158_dasVisualDebug m158 : 28|1@1+ (1,0) [0|1] "" GTW
 SG_ APS_sw158_dasSteeringControlPty m158 : 29|1@1+ (1,0) [0|1] "" GTW
 SG_ APS_sw158_dasChNm m158 : 30|1@1+ (1,0) [0|1] "" GTW
 SG_ APS_sw158_timeSinceLastMsg m158 : 32|24@1+ (1,0) [0|16777215] "" GTW
 SG_ APS_sw159_apbCriticalReason m159 : 16|4@1+ (1,0) [0|5] "" GTW
 SG_ APS_sw160_mismatchType m160 : 16|8@1+ (1,0) [0|1] "" GTW
 SG_ APS_sw160_expectedHash m160 : 24|16@1+ (1,0) [0|65535] "" GTW
 SG_ APS_sw160_actualHash m160 : 40|24@1+ (1,0) [0|16777215] "" GTW
 SG_ APS_sw161_antennaDisconnected m161 : 16|1@1+ (1,0) [0|1] "" GTW
 SG_ APS_sw171_1HzTask m171 : 16|1@1+ (1,0) [0|1] "" GTW
 SG_ APS_sw171_1kHzTask m171 : 17|1@1+ (1,0) [0|1] "" GTW
 SG_ APS_sw171_taskUtilizationPercent m171 : 18|8@1+ (1,0) [0|1] "" GTW
 SG_ APS_sw172_prolongedUiMia m172 : 16|1@1+ (1,0) [0|1] "" GTW
 SG_ APS_sw172_uiMiaAtBootup m172 : 17|1@1+ (1,0) [0|1] "" GTW
 SG_ APS_sw173_aphw2WithInfohw2 m173 : 16|1@1+ (1,0) [0|1] "" GTW
 SG_ APS_sw187_1HzTask m187 : 16|1@1+ (1,0) [0|1] "" GTW
 SG_ APS_sw187_1kHzTask m187 : 17|1@1+ (1,0) [0|1] "" GTW
 SG_ APS_sw187_taskUtilizationPercent m187 : 18|8@1+ (1,0) [0|1] "" GTW
 SG_ APS_sw188_otherTurbo m188 : 16|2@1+ (1,0) [0|1] "" GTW
 SG_ APS_sw189_vcseatdRestraintStatus m189 : 16|1@1+ (1,0) [0|1] "" GTW
 SG_ APS_sw192_CANbus m192 : 16|4@1+ (1,0) [0|1] "" GTW
 SG_ APS_sw192_SWTxQueueFull m192 : 20|1@1+ (1,0) [0|1] "" GTW
 SG_ APS_sw192_Busoff m192 : 21|1@1+ (1,0) [0|1] "" GTW
 SG_ APS_sw192_UncorrectedBitError m192 : 22|1@1+ (1,0) [0|1] "" GTW
 SG_ APS_sw192_CorrectedBitError m192 : 23|1@1+ (1,0) [0|1] "" GTW
 SG_ APS_sw192_ErrorPassive m192 : 24|1@1+ (1,0) [0|1] "" GTW
 SG_ APS_sw192_RamAccessFailed m192 : 25|1@1+ (1,0) [0|1] "" GTW
 SG_ APS_sw192_RxMsgLost m192 : 26|1@1+ (1,0) [0|1] "" GTW
 SG_ APS_sw193_outOfFocusImage m193 : 16|1@1+ (1,0) [0|1] "" GTW
 SG_ APS_sw193_impairedVD m193 : 17|1@1+ (1,0) [0|1] "" GTW
 SG_ APS_sw193_blurredImage m193 : 18|1@1+ (1,0) [0|1] "" GTW
 SG_ APS_sw193_smearedSpots m193 : 19|1@1+ (1,0) [0|1] "" GTW
 SG_ APS_sw193_partialBlockage m193 : 20|1@1+ (1,0) [0|1] "" GTW
 SG_ APS_sw193_fullBlockage m193 : 21|1@1+ (1,0) [0|1] "" GTW
 SG_ APS_sw193_smearedHalos m193 : 22|1@1+ (1,0) [0|1] "" GTW
 SG_ APS_sw194_numObstacles m194 : 16|4@1+ (1,0) [0|7] "" GTW
 SG_ APS_sw194_numPedstrian m194 : 20|4@1+ (1,0) [0|7] "" GTW
 SG_ APS_sw194_timeInHold m194 : 31|16@0+ (1,0) [0|1] "" GTW
 SG_ APS_sw194_leadDx m194 : 40|8@1+ (0.1,0) [0|25] "m" GTW
 SG_ APS_sw194_leadVx m194 : 48|6@1- (0.2,0) [-6|6] "m/s" GTW
 SG_ APS_sw194_leadAx m194 : 54|6@1- (0.2,0) [-6|6] "m/s^2" GTW
 SG_ APS_sw194_reasonForHold m194 : 60|4@1+ (1,0) [0|15] "" GTW
 SG_ APS_sw195_sdiSystemStatus m195 : 16|1@1+ (1,0) [0|1] "" GTW
 SG_ APS_sw195_sdiSystemNoise m195 : 17|2@1+ (1,0) [0|3] "" GTW
 SG_ APS_sw195_sdiFrontCC m195 : 24|5@1+ (1,0) [0|31] "" GTW
 SG_ APS_sw195_s1Blocked m195 : 29|1@1+ (1,0) [0|1] "" GTW
 SG_ APS_sw195_s6Blocked m195 : 30|1@1+ (1,0) [0|1] "" GTW
 SG_ APS_sw195_s7Blocked m195 : 31|1@1+ (1,0) [0|1] "" GTW
 SG_ APS_sw195_sdiRearCC m195 : 32|5@1+ (1,0) [0|31] "" GTW
 SG_ APS_sw195_s11Blocked m195 : 37|1@1+ (1,0) [0|1] "" GTW
 SG_ APS_sw195_s12Blocked m195 : 38|1@1+ (1,0) [0|1] "" GTW
 SG_ APS_sw195_s8Blocked m195 : 39|1@1+ (1,0) [0|1] "" GTW
 SG_ APS_sw195_vehicleSpeed m195 : 40|12@1+ (0.1,0) [0|409.6] "kph" GTW
 SG_ APS_sw198_tsrMsgInvalid m198 : 16|1@1+ (1,0) [0|1] "" GTW
 SG_ APS_sw198_tflMsgInvalid m198 : 17|1@1+ (1,0) [0|1] "" GTW
 SG_ APS_sw198_partialBlockage m198 : 18|1@1+ (1,0) [0|1] "" GTW
 SG_ APS_sw198_fullBlockage m198 : 19|1@1+ (1,0) [0|1] "" GTW
 SG_ APS_sw199_numShifts m199 : 16|4@1+ (1,0) [0|15] "" GTW
 SG_ APS_sw199_internalState m199 : 20|4@1+ (1,0) [0|15] "" GTW
 SG_ APS_sw199_abortCodePARK m199 : 24|5@1+ (1,0) [0|15] "" GTW
 SG_ APS_sw199_currentSTW m199 : 29|14@1+ (0.1,-819.2) [-819.2|819] "deg" GTW
 SG_ APS_sw199_abortCodeDas m199 : 43|5@1+ (1,0) [0|31] "" GTW
 SG_ APS_sw199_maxSpeed m199 : 48|8@1+ (0.1,-12.2) [-12.2|12.2] "mph" GTW
 SG_ APS_sw199_currentSpeed m199 : 56|8@1+ (0.1,-12.2) [-12.2|12.2] "mph" GTW
 SG_ APS_sw200_startSpeed m200 : 16|10@1+ (0.1,-50) [-10|92.3] "m/s" GTW
 SG_ APS_sw200_endSpeed m200 : 26|10@1+ (0.1,-50) [-10|92.3] "m/s" GTW
 SG_ APS_sw200_epasHandsOnDetected m200 : 36|1@1+ (1,0) [0|1] "" GTW
 SG_ APS_sw200_autopilotRestricted m200 : 37|1@1+ (1,0) [0|1] "" GTW
 SG_ APS_sw200_autopilotIntState m200 : 40|4@1+ (1,0) [0|1] "" GTW
 SG_ APS_sw201_timeHorizon m201 : 16|8@1+ (0.1,0) [0|25.5] "s" GTW
 SG_ APS_sw201_vehSpeed m201 : 24|8@1+ (1,0) [0|255] "kph" GTW
 SG_ APS_sw201_stwAngleReq m201 : 32|8@1- (1,0) [-128|127] "deg" GTW
 SG_ APS_sw201_viewRangeOAL m201 : 43|3@1+ (1,0) [0|5] "" GTW
 SG_ APS_sw201_steeringErrorOAL m201 : 55|3@1+ (1,0) [0|5] "" GTW
 SG_ APS_sw201_virtualLaneInputOAL m201 : 61|3@1+ (1,0) [0|5] "" GTW
 SG_ APS_sw202_sdiSystemStatus m202 : 16|1@1+ (1,0) [0|1] "" GTW
 SG_ APS_sw202_sdiSystemNoise m202 : 17|2@1+ (1,0) [0|3] "" GTW
 SG_ APS_sw202_sdiFrontCC m202 : 24|5@1+ (1,0) [0|31] "" GTW
 SG_ APS_sw202_s1Blocked m202 : 29|1@1+ (1,0) [0|1] "" GTW
 SG_ APS_sw202_s6Blocked m202 : 30|1@1+ (1,0) [0|1] "" GTW
 SG_ APS_sw202_s7Blocked m202 : 31|1@1+ (1,0) [0|1] "" GTW
 SG_ APS_sw202_sdiRearCC m202 : 32|5@1+ (1,0) [0|31] "" GTW
 SG_ APS_sw202_s8Blocked m202 : 37|1@1+ (1,0) [0|1] "" GTW
 SG_ APS_sw202_s11Blocked m202 : 38|1@1+ (1,0) [0|1] "" GTW
 SG_ APS_sw202_s12Blocked m202 : 39|1@1+ (1,0) [0|1] "" GTW
 SG_ APS_sw202_vehicleSpeed m202 : 40|12@1+ (0.1,0) [0|409.6] "kph" GTW
 SG_ APS_sw203_slotSizeX m203 : 16|8@1+ (4,0) [0|1020] "cm" GTW
 SG_ APS_sw203_slotSizeY m203 : 24|8@1+ (4,0) [0|1020] "cm" GTW
 SG_ APS_sw203_startDistance m203 : 32|11@1+ (1,0) [0|2047] "cm" GTW
 SG_ APS_sw203_roadClass m203 : 43|3@1+ (1,0) [0|7] "" GTW
 SG_ APS_sw203_curbType m203 : 46|2@1+ (1,0) [0|3] "" GTW
 SG_ APS_sw203_controlType m203 : 48|4@1+ (1,0) [0|15] "" GTW
 SG_ APS_sw203_vehicleSkew m203 : 52|12@1+ (0.002,0) [0|8.19] "radians" GTW
 SG_ APS_sw204_frLeftMiddle m204 : 16|8@1+ (1,0) [0|255] "cm" GTW
 SG_ APS_sw204_frRightMiddle m204 : 24|8@1+ (1,0) [0|255] "cm" GTW
 SG_ APS_sw204_frRight m204 : 32|8@1+ (1,0) [0|255] "cm" GTW
 SG_ APS_sw204_frLeft m204 : 40|8@1+ (1,0) [0|255] "cm" GTW
 SG_ APS_sw204_frMiddle m204 : 48|8@1+ (1,0) [0|255] "cm" GTW
 SG_ APS_sw204_maxSpeed m204 : 56|8@1+ (0.1,-12.2) [-12.2|12.2] "mph" GTW
 SG_ APS_sw205_rrRightMiddle m205 : 16|8@1+ (1,0) [0|255] "cm" GTW
 SG_ APS_sw205_rrLeftMiddle m205 : 24|8@1+ (1,0) [0|255] "cm" GTW
 SG_ APS_sw205_rrRight m205 : 32|8@1+ (1,0) [0|255] "cm" GTW
 SG_ APS_sw205_rrLeft m205 : 40|8@1+ (1,0) [0|255] "cm" GTW
 SG_ APS_sw205_rrMiddle m205 : 48|8@1+ (1,0) [0|255] "cm" GTW
 SG_ APS_sw205_oocDistance m205 : 56|8@1+ (1,0) [0|255] "cm" GTW
 SG_ APS_sw207_lcUnavailableReason m207 : 16|8@1+ (1,0) [0|255] "" GTW
 SG_ APS_sw207_appMobileyeStatus m207 : 24|8@1+ (1,0) [0|255] "" GTW
 SG_ APS_sw207_eyeq3MainState m207 : 32|8@1+ (1,0) [0|255] "" GTW
 SG_ APS_sw213_startSpeed m213 : 16|10@1+ (0.1,-50) [-10|92.3] "m/s" GTW
 SG_ APS_sw213_endSpeed m213 : 26|10@1+ (0.1,-50) [-10|92.3] "m/s" GTW
 SG_ APS_sw213_epasHandsOnDetected m213 : 36|1@1+ (1,0) [0|1] "" GTW
 SG_ APS_sw213_autopilotRestricted m213 : 37|1@1+ (1,0) [0|1] "" GTW
 SG_ APS_sw213_autopilotIntState m213 : 40|4@1+ (1,0) [0|1] "" GTW
 SG_ APS_sw218_pedalPosition m218 : 16|7@1+ (1,0) [0|127] "%" GTW
 SG_ APS_sw218_cipvDist m218 : 24|8@1+ (0.2,0) [0|51] "m" GTW
 SG_ APS_sw218_handsOnState m218 : 32|4@1+ (1,0) [0|0] "" GTW
 SG_ APS_sw218_mcuAutosteerRestricted m218 : 36|1@1+ (1,0) [0|0] "" GTW
 SG_ APS_sw218_drivingOnHighway m218 : 37|1@1+ (1,0) [0|0] "" GTW
 SG_ APS_sw219_vehicleSpeed m219 : 16|12@1+ (0.05,-25) [-25|179.75] "mph" GTW
 SG_ APS_sw219_controlledAccess m219 : 28|1@1+ (1,0) [0|0] "" GTW
 SG_ APS_sw219_roadClass m219 : 29|3@1+ (1,0) [0|0] "" GTW
 SG_ APS_sw220_vehicleSpeed m220 : 16|12@1+ (0.05,-25) [-25|179.75] "mph" GTW
 SG_ APS_sw220_controlledAccess m220 : 28|1@1+ (1,0) [0|0] "" GTW
 SG_ APS_sw220_roadClass m220 : 29|3@1+ (1,0) [0|0] "" GTW
 SG_ APS_sw227_sensorSide m227 : 16|4@1+ (1,0) [0|15] "" GTW
 SG_ APS_sw227_sensorNumber m227 : 20|4@1+ (1,0) [0|15] "" GTW
 SG_ APS_sw227_sensorMeasurement m227 : 24|9@1+ (1,0) [0|511] "cm" GTW
 SG_ APS_sw227_vehicleSpeed m227 : 33|12@1+ (0.05,-25) [-25|179.75] "mph" GTW
 SG_ APS_sw227_ambientTemperature m227 : 45|8@1+ (0.5,-40) [-40|87.5] "C" GTW
 SG_ APS_sw230_sensor1Blocked m230 : 16|1@1+ (1,0) [0|1] "" GTW
 SG_ APS_sw230_sensor2Blocked m230 : 17|1@1+ (1,0) [0|1] "" GTW
 SG_ APS_sw230_sensor3Blocked m230 : 18|1@1+ (1,0) [0|1] "" GTW
 SG_ APS_sw230_sensor4Blocked m230 : 19|1@1+ (1,0) [0|1] "" GTW
 SG_ APS_sw230_sensor5Blocked m230 : 20|1@1+ (1,0) [0|1] "" GTW
 SG_ APS_sw230_sensor6Blocked m230 : 21|1@1+ (1,0) [0|1] "" GTW
 SG_ APS_sw230_sensor7Blocked m230 : 22|1@1+ (1,0) [0|1] "" GTW
 SG_ APS_sw230_sensor8Blocked m230 : 23|1@1+ (1,0) [0|1] "" GTW
 SG_ APS_sw230_sensor9Blocked m230 : 24|1@1+ (1,0) [0|1] "" GTW
 SG_ APS_sw230_sensor10Blocked m230 : 25|1@1+ (1,0) [0|1] "" GTW
 SG_ APS_sw230_sensor11Blocked m230 : 26|1@1+ (1,0) [0|1] "" GTW
 SG_ APS_sw230_sensor12Blocked m230 : 27|1@1+ (1,0) [0|1] "" GTW
 SG_ APS_sw231_timeToImpact m231 : 16|9@1+ (1,0) [0|511] "ms" GTW
 SG_ APS_sw231_predImpactVelocity m231 : 25|7@1+ (0.5,0) [0|63.5] "m/s" GTW
 SG_ APS_sw231_targetDistance m231 : 32|7@1+ (0.1,0) [0|12.7] "m" GTW
 SG_ APS_sw231_targetRelVelocity m231 : 39|6@1+ (0.5,0) [0|31.5] "m/s" GTW
 SG_ APS_sw231_targetRelAcceleration m231 : 45|8@1+ (0.1,-12.8) [-12.8|12.7] "m/s2" GTW
 SG_ APS_sw231_targetIsACar m231 : 53|1@1+ (1,0) [0|0] "" GTW
 SG_ APS_sw231_egoVehicleSpeed m231 : 54|5@1+ (5,0) [0|155] "kph" GTW
 SG_ APS_sw231_steeringOverride m231 : 59|1@1+ (1,0) [0|1] "" GTW
 SG_ APS_sw231_predOverlap m231 : 60|4@1+ (10,0) [0|150] "%" GTW

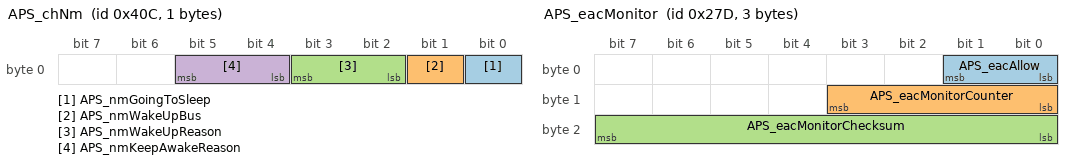
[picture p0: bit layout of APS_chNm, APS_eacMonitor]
BO_ 1036 APS_chNm: 1 APS
 SG_ APS_nmGoingToSleep : 0|1@1+ (1,0) [0|0] "" GTW
 SG_ APS_nmWakeUpBus : 1|1@1+ (1,0) [0|0] "" GTW
 SG_ APS_nmWakeUpReason : 2|2@1+ (1,0) [0|0] "" GTW
 SG_ APS_nmKeepAwakeReason : 4|2@1+ (1,0) [0|0] "" GTW

BO_ 637 APS_eacMonitor: 3 APS
 SG_ APS_eacAllow : 0|2@1+ (1,0) [0|0] "" EPAS3S
 SG_ APS_eacMonitorCounter : 8|4@1+ (1,0) [0|0] "" EPAS3S
 SG_ APS_eacMonitorChecksum : 16|8@1+ (1,0) [0|0] "" EPAS3S

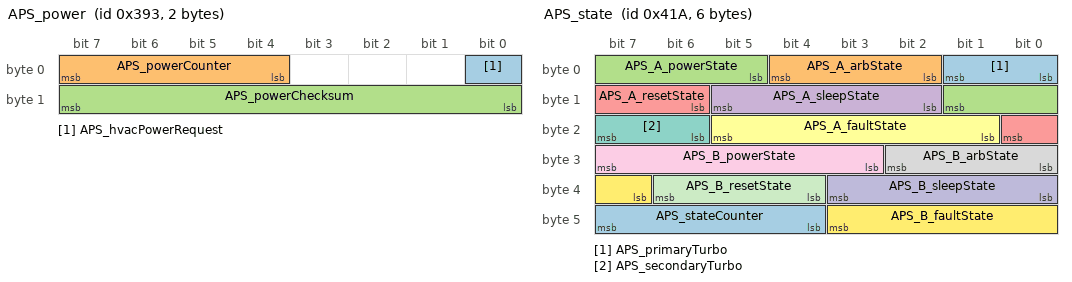
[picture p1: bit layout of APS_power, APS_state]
BO_ 915 APS_power: 2 APS
 SG_ APS_hvacPowerRequest : 0|1@1+ (1,0) [0|1] "" GTW
 SG_ APS_powerCounter : 4|4@1+ (1,0) [0|15] "" GTW
 SG_ APS_powerChecksum : 8|8@1+ (1,0) [0|255] "" GTW

BO_ 1050 APS_state: 6 APS
 SG_ APS_primaryTurbo : 0|2@1+ (1,0) [0|0] "" GTW
 SG_ APS_A_arbState : 2|3@1+ (1,0) [0|0] "" GTW
 SG_ APS_A_powerState : 5|5@1+ (1,0) [0|0] "" GTW
 SG_ APS_A_sleepState : 10|4@1+ (1,0) [0|0] "" GTW
 SG_ APS_A_resetState : 14|3@1+ (1,0) [0|0] "" GTW
 SG_ APS_A_faultState : 17|5@1+ (1,0) [0|0] "" GTW
 SG_ APS_secondaryTurbo : 22|2@1+ (1,0) [0|0] "" GTW
 SG_ APS_B_arbState : 24|3@1+ (1,0) [0|0] "" GTW
 SG_ APS_B_powerState : 27|5@1+ (1,0) [0|0] "" GTW
 SG_ APS_B_sleepState : 32|4@1+ (1,0) [0|0] "" GTW
 SG_ APS_B_resetState : 36|3@1+ (1,0) [0|0] "" GTW
 SG_ APS_B_faultState : 39|5@1+ (1,0) [0|0] "" GTW
 SG_ APS_stateCounter : 44|4@1+ (1,0) [0|0] "" GTW

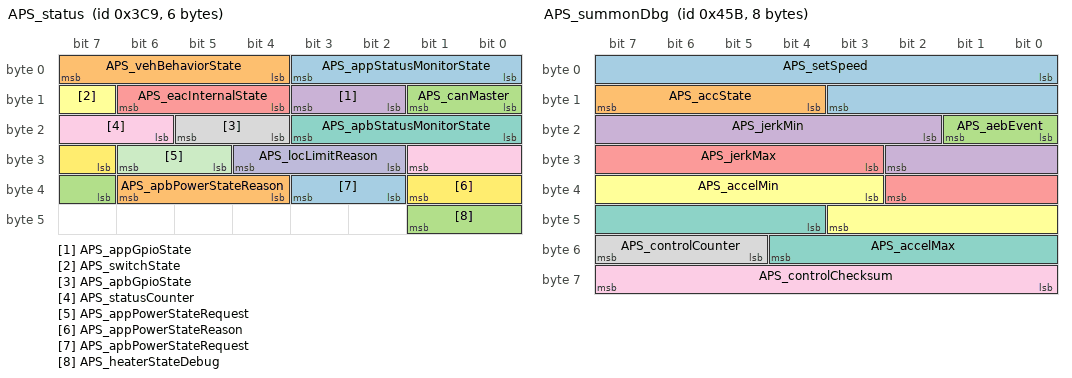
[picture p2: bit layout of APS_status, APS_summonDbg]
BO_ 969 APS_status: 6 APS
 SG_ APS_appStatusMonitorState : 0|4@1+ (1,0) [0|15] "" GTW
 SG_ APS_vehBehaviorState : 4|4@1+ (1,0) [0|15] "" GTW
 SG_ APS_canMaster : 8|2@1+ (1,0) [0|15] "" GTW
 SG_ APS_appGpioState : 10|2@1+ (1,0) [0|3] "" GTW
 SG_ APS_eacInternalState : 12|3@1+ (1,0) [0|5] "" GTW
 SG_ APS_switchState : 15|1@1+ (1,0) [0|1] "" GTW
 SG_ APS_apbStatusMonitorState : 16|4@1+ (1,0) [0|15] "" GTW
 SG_ APS_apbGpioState : 20|2@1+ (1,0) [0|3] "" GTW
 SG_ APS_statusCounter : 22|4@1+ (1,0) [0|15] "" GTW
 SG_ APS_locLimitReason : 26|3@1+ (1,0) [0|7] "" GTW
 SG_ APS_appPowerStateRequest : 29|2@1+ (1,0) [0|2] "" APP,GTW
 SG_ APS_appPowerStateReason : 31|3@1+ (1,0) [0|8] "" GTW
 SG_ APS_apbPowerStateRequest : 34|2@1+ (1,0) [0|2] "" APP,GTW
 SG_ APS_apbPowerStateReason : 36|3@1+ (1,0) [0|8] "" GTW
 SG_ APS_heaterStateDebug : 39|3@1+ (1,0) [0|7] "" APP,GTW

BO_ 1115 APS_summonDbg: 8 APS
 SG_ APS_setSpeed : 0|12@1+ (0.1,0) [0|409.4] "kph" APP
 SG_ APS_accState : 12|4@1+ (1,0) [0|0] "" APP
 SG_ APS_aebEvent : 16|2@1+ (1,0) [0|3] "" APP
 SG_ APS_jerkMin : 18|9@1+ (0.03,-15.232) [-15.232|0.098] "m/s^3" APP
 SG_ APS_jerkMax : 27|8@1+ (0.059,0) [0|15.045] "m/s^3" APP
 SG_ APS_accelMin : 35|9@1+ (0.04,-15) [-15|5.44] "m/s^2" APP
 SG_ APS_accelMax : 44|9@1+ (0.04,-15) [-15|5.44] "m/s^2" APP
 SG_ APS_controlCounter : 53|3@1+ (1,0) [0|0] "" APP
 SG_ APS_controlChecksum : 56|8@1+ (1,0) [0|0] "" APP

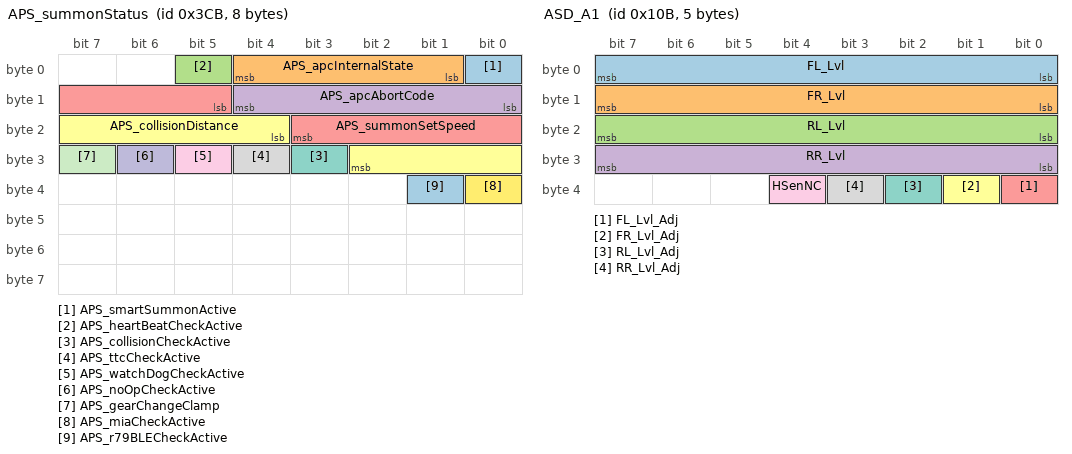
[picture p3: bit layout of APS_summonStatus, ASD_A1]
BO_ 971 APS_summonStatus: 8 APS
 SG_ APS_smartSummonActive : 0|1@1+ (1,0) [0|1] "" APP,BCCEN,GTW
 SG_ APS_apcInternalState : 1|4@1+ (1,0) [0|15] "" APP,GTW
 SG_ APS_heartBeatCheckActive : 5|1@1+ (1,0) [0|1] "" APP,GTW
 SG_ APS_apcAbortCode : 8|5@1+ (1,0) [0|31] "" APP
 SG_ APS_summonSetSpeed : 13|7@1+ (0.1,0) [0|12.7] "kph" APP
 SG_ APS_collisionDistance : 20|7@1+ (0.05,0) [0|6.35] "m" APP
 SG_ APS_collisionCheckActive : 27|1@1+ (1,0) [0|1] "" APP
 SG_ APS_ttcCheckActive : 28|1@1+ (1,0) [0|1] "" APP
 SG_ APS_watchDogCheckActive : 29|1@1+ (1,0) [0|1] "" APP
 SG_ APS_noOpCheckActive : 30|1@1+ (1,0) [0|1] "" APP
 SG_ APS_gearChangeClamp : 31|1@1+ (1,0) [0|1] "" APP
 SG_ APS_miaCheckActive : 32|1@1+ (1,0) [0|1] "" APP
 SG_ APS_r79BLECheckActive : 33|1@1+ (1,0) [0|1] "" APP

BO_ 811 APS_warningMatrix0: 8 APS
 SG_ APS_w002_ldwDisabled : 1|1@1+ (1,0) [0|1] "" GTW,MCU
 SG_ APS_w003_isaDisabled : 2|1@1+ (1,0) [0|1] "" GTW,MCU
 SG_ APS_w004_accDisabled : 3|1@1+ (1,0) [0|1] "" GTW,MCU
 SG_ APS_w005_fcwCancelled : 4|1@1+ (1,0) [0|1] "" GTW,MCU
 SG_ APS_w006_aebCancelled : 5|1@1+ (1,0) [0|1] "" GTW,MCU
 SG_ APS_w007_ahlbDisabled : 6|1@1+ (1,0) [0|1] "" GTW,MCU
 SG_ APS_w008_parkDisabled : 7|1@1+ (1,0) [0|1] "" GTW,MCU
 SG_ APS_w009_aebFault : 8|1@1+ (1,0) [0|1] "" GTW,MCU
 SG_ APS_w010_radcCalibIssue : 9|1@1+ (1,0) [0|0] "" GTW,MCU
 SG_ APS_w011_scaEvent : 10|1@1+ (1,0) [0|0] "" GTW,MCU
 SG_ APS_w012_Cam_BootFailure : 11|1@1+ (1,0) [0|0] "" GTW,MCU
 SG_ APS_w013_Cam_Watchdog : 12|1@1+ (1,0) [0|0] "" GTW,MCU
 SG_ APS_w014_swAssert : 13|1@1+ (1,0) [0|0] "" GTW,MCU
 SG_ APS_w015_Camera_Failsafes : 14|1@1+ (1,0) [0|0] "" GTW,MCU
 SG_ APS_w016_aeb_e_event : 15|1@1+ (1,0) [0|0] "" GTW,MCU
 SG_ APS_w017_Cam_Msg_MIA : 16|1@1+ (1,0) [0|0] "" GTW,MCU
 SG_ APS_w018_ECU_Power_Issue : 17|1@1+ (1,0) [0|0] "" GTW,MCU
 SG_ APS_w019_ECU_Stack_Overflow : 18|1@1+ (1,0) [0|0] "" GTW,MCU
 SG_ APS_w020_ECU_checkstopError : 19|1@1+ (1,0) [0|0] "" GTW,MCU
 SG_ APS_w021_ECU_Temperature_Issue : 20|1@1+ (1,0) [0|0] "" GTW,MCU
 SG_ APS_w022_ECU_EEPROM_Failure : 21|1@1+ (1,0) [0|0] "" GTW,MCU
 SG_ APS_w023_ECU_Cam_Statemismatc : 22|1@1+ (1,0) [0|0] "" GTW,MCU
 SG_ APS_w024_ECU_Watchdog_Reset : 23|1@1+ (1,0) [0|0] "" GTW,MCU
 SG_ APS_w025_LC_Steering_Override : 24|1@1+ (1,0) [0|0] "" GTW,MCU
 SG_ APS_w026_ECU_timingIssue : 25|1@1+ (1,0) [0|0] "" GTW,MCU
 SG_ APS_w027_ECU_Reset_Fault : 26|1@1+ (1,0) [0|0] "" GTW,MCU
 SG_ APS_w028_spi_rx_error : 27|1@1+ (1,0) [0|0] "" GTW,MCU
 SG_ APS_w029_spi_tx_error : 28|1@1+ (1,0) [0|0] "" GTW,MCU
 SG_ APS_w030_Heater_Issue : 29|1@1+ (1,0) [0|0] "" GTW,MCU
 SG_ APS_w031_canRxError : 30|1@1+ (1,0) [0|0] "" GTW,MCU
 SG_ APS_w032_canTxError : 31|1@1+ (1,0) [0|0] "" GTW,MCU
 SG_ APS_w033_gtwMia : 32|1@1+ (1,0) [0|0] "" GTW,MCU
 SG_ APS_w034_sccmMia : 33|1@1+ (1,0) [0|0] "" GTW,MCU
 SG_ APS_w035_espMia : 34|1@1+ (1,0) [0|0] "" GTW,MCU
 SG_ APS_w036_bdyMia : 35|1@1+ (1,0) [0|0] "" GTW,MCU
 SG_ APS_w037_camTacIssue : 36|1@1+ (1,0) [0|0] "" GTW,MCU
 SG_ APS_w038_camFailure : 37|1@1+ (1,0) [0|0] "" GTW,MCU
 SG_ APS_w039_sdm_rcm_Mia : 38|1@1+ (1,0) [0|0] "" GTW,MCU
 SG_ APS_w040_autopilotAngleSaturated : 39|1@1+ (1,0) [0|0] "" GTW,MCU
 SG_ APS_w041_autopilotRateSaturated : 40|1@1+ (1,0) [0|0] "" GTW,MCU
 SG_ APS_w042_autopilotAborting : 41|1@1+ (1,0) [0|1] "" GTW,MCU
 SG_ APS_w043_camLongRunTime : 42|1@1+ (1,0) [0|1] "" GTW,MCU
 SG_ APS_w044_appMobileyeFailure : 43|1@1+ (1,0) [0|0] "" GTW,MCU
 SG_ APS_w045_radMia : 44|1@1+ (1,0) [0|0] "" GTW,MCU
 SG_ APS_w046_eepromRecordAbsent : 45|1@1+ (1,0) [0|1] "" GTW,MCU
 SG_ APS_w047_edrEvent : 46|1@1+ (1,0) [0|0] "" GTW,MCU
 SG_ APS_w048_APS_Features_Disabled : 47|1@1+ (1,0) [0|0] "" GTW,MCU
 SG_ APS_w049_eyeqVersionMismatch : 48|1@1+ (1,0) [0|1] "" GTW,MCU
 SG_ APS_w050_aeb_event : 49|1@1+ (1,0) [0|1] "" GTW,MCU
 SG_ APS_w051_radcEcuIssue : 50|1@1+ (1,0) [0|1] "" GTW,MCU
 SG_ APS_w052_radcSensorIssue : 51|1@1+ (1,0) [0|1] "" GTW,MCU
 SG_ APS_w053_radcCommIssue : 52|1@1+ (1,0) [0|1] "" GTW,MCU
 SG_ APS_w054_camAutofix : 53|1@1+ (1,0) [0|1] "" GTW,MCU
 SG_ APS_w055_radcVersionMismatch : 54|1@1+ (1,0) [0|1] "" GTW,MCU
 SG_ APS_w056_diMia : 55|1@1+ (1,0) [0|1] "" GTW,MCU
 SG_ APS_w057_mcuMia : 56|1@1+ (1,0) [0|1] "" GTW,MCU
 SG_ APS_w058_epbMia : 57|1@1+ (1,0) [0|1] "" GTW,MCU
 SG_ APS_w059_parkMia : 58|1@1+ (1,0) [0|1] "" GTW,MCU
 SG_ APS_w060_fcw_event : 59|1@1+ (1,0) [0|1] "" GTW,MCU
 SG_ APS_w061_airSuspensionMia : 60|1@1+ (1,0) [0|1] "" GTW,MCU
 SG_ APS_w062_radcAlignment : 61|1@1+ (1,0) [0|1] "" GTW,MCU
 SG_ APS_w063_parkVersionMismatch : 62|1@1+ (1,0) [0|1] "" GTW,MCU
 SG_ APS_w064_epasMia : 63|1@1+ (1,0) [0|1] "" GTW,MCU

BO_ 876 APS_warningMatrix1: 8 APS
 SG_ APS_w065_deserializerOvercurrent : 0|1@1+ (1,0) [0|1] "" GTW,MCU
 SG_ APS_w066_deserializerLockLost : 1|1@1+ (1,0) [0|1] "" GTW,MCU
 SG_ APS_w067_steeringAlignment : 2|1@1+ (1,0) [0|1] "" GTW,MCU
 SG_ APS_w068_vlInconsistency : 3|1@1+ (1,0) [0|1] "" GTW,MCU
 SG_ APS_w069_apcSpaceMasked : 4|1@1+ (1,0) [0|1] "" GTW,MCU
 SG_ APS_w070_apcIncompleteCal : 5|1@1+ (1,0) [0|1] "" GTW,MCU
 SG_ APS_w071_selfparkStarted : 6|1@1+ (1,0) [0|1] "" GTW,MCU
 SG_ APS_w072_selfparkComplete : 7|1@1+ (1,0) [0|1] "" GTW,MCU
 SG_ APS_w073_issueEscalatedLDW : 8|1@1+ (1,0) [0|1] "" GTW,MCU
 SG_ APS_w074_inPathStationaryObst : 9|1@1+ (1,0) [0|1] "" GTW,MCU
 SG_ APS_w075_scMia : 10|1@1+ (1,0) [0|1] "" GTW,MCU
 SG_ APS_w076_mobilEyeSetC : 11|1@1+ (1,0) [0|1] "" GTW,MCU
 SG_ APS_w077_pmmActive : 12|1@1+ (1,0) [0|1] "" GTW,MCU
 SG_ APS_w078_pmmActive2 : 13|1@1+ (1,0) [0|1] "" GTW,MCU
 SG_ APS_w079_edrAvailable : 14|1@1+ (1,0) [0|1] "" GTW,MCU
 SG_ APS_w080_accFailedActivation : 15|1@1+ (1,0) [0|1] "" GTW,MCU
 SG_ APS_w081_pmmActiveBraking : 16|1@1+ (1,0) [0|1] "" GTW,MCU
 SG_ APS_w082_inPathFSviolation : 17|1@1+ (1,0) [0|1] "" GTW,MCU
 SG_ APS_w083_inPathRADObject : 18|1@1+ (1,0) [0|1] "" GTW,MCU
 SG_ APS_w084_pmmIPSO : 19|1@1+ (1,0) [0|1] "" GTW,MCU
 SG_ APS_w085_pmmSteering : 20|1@1+ (1,0) [0|1] "" GTW,MCU
 SG_ APS_w086_robCollision : 21|1@1+ (1,0) [0|1] "" GTW,MCU
 SG_ APS_w087_DEPRECATED : 22|1@1+ (1,0) [0|1] "" GTW,MCU
 SG_ APS_w088_DEPRECATED : 23|1@1+ (1,0) [0|1] "" GTW,MCU
 SG_ APS_w089_DEPRECATED : 24|1@1+ (1,0) [0|1] "" GTW,MCU
 SG_ APS_w090_DEPRECATED : 25|1@1+ (1,0) [0|1] "" GTW,MCU
 SG_ APS_w091_DEPRECATED : 26|1@1+ (1,0) [0|1] "" GTW,MCU
 SG_ APS_w092_DEPRECATED : 27|1@1+ (1,0) [0|1] "" GTW,MCU
 SG_ APS_w093_DEPRECATED : 28|1@1+ (1,0) [0|1] "" GTW,MCU
 SG_ APS_w094_DEPRECATED : 29|1@1+ (1,0) [0|1] "" GTW,MCU
 SG_ APS_w095_DEPRECATED : 30|1@1+ (1,0) [0|1] "" GTW,MCU
 SG_ APS_w096_DEPRECATED : 31|1@1+ (1,0) [0|1] "" GTW,MCU
 SG_ APS_w097_DEPRECATED : 32|1@1+ (1,0) [0|1] "" GTW,MCU
 SG_ APS_w098_DEPRECATED : 33|1@1+ (1,0) [0|1] "" GTW,MCU
 SG_ APS_w099_DEPRECATED : 34|1@1+ (1,0) [0|1] "" GTW,MCU
 SG_ APS_w100_DEPRECATED : 35|1@1+ (1,0) [0|1] "" GTW,MCU
 SG_ APS_w101_DEPRECATED : 36|1@1+ (1,0) [0|1] "" GTW,MCU
 SG_ APS_w102_DEPRECATED : 37|1@1+ (1,0) [0|1] "" GTW,MCU
 SG_ APS_w103_robExperimentalAEB : 38|1@1+ (1,0) [0|1] "" GTW,MCU
 SG_ APS_w104_DEPRECATED : 39|1@1+ (1,0) [0|1] "" GTW,MCU
 SG_ APS_w105_DEPRECATED : 40|1@1+ (1,0) [0|1] "" GTW,MCU
 SG_ APS_w106_torsionBarCalibrated : 41|1@1+ (1,0) [0|1] "" GTW,MCU

BO_ 1113 APS_warningMatrix2: 8 APS
 SG_ APS_w129_ECU_Power_Issue : 0|1@1+ (1,0) [0|1] "" GTW,MCU
 SG_ APS_w130_ECU_Thermal_Issue : 1|1@1+ (1,0) [0|1] "" GTW,MCU
 SG_ APS_w131_trap_exception : 2|1@1+ (1,0) [0|1] "" GTW,MCU
 SG_ APS_w132_appVersionMismatch : 3|1@1+ (1,0) [0|1] "" GTW,MCU
 SG_ APS_w133_ETHSwitchError : 4|1@1+ (1,0) [0|1] "" GTW,MCU
 SG_ APS_w134_appMia : 5|1@1+ (1,0) [0|1] "" GTW,MCU
 SG_ APS_w135_appCritical : 6|1@1+ (1,0) [0|1] "" GTW,MCU
 SG_ APS_w136_gpsDisabled : 7|1@1+ (1,0) [0|1] "" GTW,MCU
 SG_ APS_w137_gpsFaultReset : 8|1@1+ (1,0) [0|1] "" GTW,MCU
 SG_ APS_w138_gpsComIssue : 9|1@1+ (1,0) [0|1] "" GTW,MCU
 SG_ APS_w139_udpBufferOverflow : 10|1@1+ (1,0) [0|1] "" GTW,MCU
 SG_ APS_w146_epas3pMiaPartyBus : 17|1@1+ (1,0) [0|1] "" GTW,MCU
 SG_ APS_w151_apRecovered : 22|1@1+ (1,0) [0|1] "" GTW,MCU
 SG_ APS_w152_gpsFusionStatus : 23|1@1+ (1,0) [0|1] "" GTW,MCU
 SG_ APS_w153_eacInhibit : 24|1@1+ (1,0) [0|1] "" GTW,MCU
 SG_ APS_w154_secEthPacketMIA : 25|1@1+ (1,0) [0|1] "" GTW,MCU
 SG_ APS_w155_ethLwipError : 26|1@1+ (1,0) [0|1] "" GTW,MCU
 SG_ APS_w156_lwipAssert : 27|1@1+ (1,0) [0|1] "" GTW,MCU
 SG_ APS_w157_autopilotReboot : 28|1@1+ (1,0) [0|1] "" GTW,MCU
 SG_ APS_w158_apbMia : 29|1@1+ (1,0) [0|1] "" GTW,MCU
 SG_ APS_w159_apbCritical : 30|1@1+ (1,0) [0|1] "" GTW,MCU
 SG_ APS_w160_apbVersionMismatch : 31|1@1+ (1,0) [0|1] "" GTW,MCU
 SG_ APS_w161_gpsAntennaDisconnected : 32|1@1+ (1,0) [0|1] "" GTW,MCU
 SG_ APS_w162_TurboA_DisRegPgoodErr : 33|1@1+ (1,0) [0|1] "" GTW,MCU
 SG_ APS_w163_TurboA_DisRegNFault : 34|1@1+ (1,0) [0|1] "" GTW,MCU
 SG_ APS_w164_TurboA_12VFuseFault : 35|1@1+ (1,0) [0|1] "" GTW,MCU
 SG_ APS_w165_TurboA_Temp_NOS : 36|1@1+ (1,0) [0|1] "" GTW,MCU
 SG_ APS_w166_TurboA_SMSLockStepErr : 37|1@1+ (1,0) [0|1] "" GTW,MCU
 SG_ APS_w167_TurboA_TMU_Throttle : 38|1@1+ (1,0) [0|1] "" GTW,MCU
 SG_ APS_w168_TurboA_SMS_WDOG : 39|1@1+ (1,0) [0|1] "" GTW,MCU
 SG_ APS_w169_TurboA_SCS_LKUP : 40|1@1+ (1,0) [0|1] "" GTW,MCU
 SG_ APS_w170_TurboA_A72_watchdog : 41|1@1+ (1,0) [0|1] "" GTW,MCU
 SG_ APS_w171_TurboA_SMS_taskUtilErr : 42|1@1+ (1,0) [0|1] "" GTW,MCU
 SG_ APS_w172_apFeaturesUnavailable : 43|1@1+ (1,0) [0|1] "" GTW,MCU
 SG_ APS_w173_unsupportedConfig : 44|1@1+ (1,0) [0|1] "" GTW,MCU
 SG_ APS_w178_TurboB_DisRegPgoodErr : 49|1@1+ (1,0) [0|1] "" GTW,MCU
 SG_ APS_w179_TurboB_DisRegNFault : 50|1@1+ (1,0) [0|1] "" GTW,MCU
 SG_ APS_w180_TurboB_12VFuseFault : 51|1@1+ (1,0) [0|1] "" GTW,MCU
 SG_ APS_w181_TurboB_Temp_NOS : 52|1@1+ (1,0) [0|1] "" GTW,MCU
 SG_ APS_w182_TurboB_SMSLockStepErr : 53|1@1+ (1,0) [0|1] "" GTW,MCU
 SG_ APS_w183_TurboB_TMU_Throttle : 54|1@1+ (1,0) [0|1] "" GTW,MCU
 SG_ APS_w184_TurboB_SMS_WDOG : 55|1@1+ (1,0) [0|1] "" GTW,MCU
 SG_ APS_w185_TurboB_SCS_LKUP : 56|1@1+ (1,0) [0|1] "" GTW,MCU
 SG_ APS_w186_TurboB_A72_watchdog : 57|1@1+ (1,0) [0|1] "" GTW,MCU
 SG_ APS_w187_TurboB_SMS_taskUtilErr : 58|1@1+ (1,0) [0|1] "" GTW,MCU
 SG_ APS_w188_otherTurboUartMIA : 59|1@1+ (1,0) [0|1] "" GTW,MCU
 SG_ APS_w189_vcseatMIA : 60|1@1+ (1,0) [0|1] "" GTW,MCU
 SG_ APS_w192_CANFault : 63|1@1+ (1,0) [0|1] "" GTW,MCU

BO_ 848 APS_warningMatrix3: 8 APS
 SG_ APS_w193_camWindshieldUnclean : 0|1@1+ (1,0) [0|0] "" GTW,MCU
 SG_ APS_w194_accDriverResumeRqrd : 1|1@1+ (1,0) [0|0] "" GTW,MCU
 SG_ APS_w195_scwUnavailable : 2|1@1+ (1,0) [0|0] "" GTW,MCU
 SG_ APS_w196_stopSignWarning : 3|1@1+ (1,0) [0|0] "" GTW,MCU
 SG_ APS_w197_redLightWarning : 4|1@1+ (1,0) [0|0] "" GTW,MCU
 SG_ APS_w198_tsrUnavailable : 5|1@1+ (1,0) [0|0] "" GTW,MCU
 SG_ APS_w199_apcAbort : 6|1@1+ (1,0) [0|0] "" GTW,MCU
 SG_ APS_w200_lcSlowdown : 7|1@1+ (1,0) [0|0] "" GTW,MCU
 SG_ APS_w201_lcAborting : 8|1@1+ (1,0) [0|0] "" GTW,MCU
 SG_ APS_w202_scwNoisyEnvironment : 9|1@1+ (1,0) [0|0] "" GTW,MCU
 SG_ APS_w203_apcActivation : 10|1@1+ (1,0) [0|0] "" GTW,MCU
 SG_ APS_w204_apcFinalFront : 11|1@1+ (1,0) [0|0] "" GTW,MCU
 SG_ APS_w205_apcFinalRear : 12|1@1+ (1,0) [0|0] "" GTW,MCU
 SG_ APS_w206_autosteerNotEnabled : 13|1@1+ (1,0) [0|0] "" GTW,MCU
 SG_ APS_w207_autosteerUnavailable : 14|1@1+ (1,0) [0|0] "" GTW,MCU
 SG_ APS_w208_rackDetected : 15|1@1+ (1,0) [0|0] "" GTW,MCU
 SG_ APS_w209_autoSummonRequest : 16|1@1+ (1,0) [0|0] "" GTW,MCU
 SG_ APS_w210_camObstrcted : 17|1@1+ (1,0) [0|0] "" GTW,MCU
 SG_ APS_w211_accNoSeatBelt : 18|1@1+ (1,0) [0|0] "" GTW,MCU
 SG_ APS_w212_lcUnavailableStrikeOut : 19|1@1+ (1,0) [0|0] "" GTW,MCU
 SG_ APS_w213_autosteerStruckOut : 20|1@1+ (1,0) [0|0] "" GTW,MCU
 SG_ APS_w214_driverNotIntracting : 21|1@1+ (1,0) [0|0] "" GTW,MCU
 SG_ APS_w215_contDriverNotIntracting : 22|1@1+ (1,0) [0|0] "" GTW,MCU
 SG_ APS_w216_driverOverriding : 23|1@1+ (1,0) [0|0] "" GTW,MCU
 SG_ APS_w217_lcUnavailableSpeeding : 24|1@1+ (1,0) [0|0] "" GTW,MCU
 SG_ APS_w218_lcSpeedExceededLimit : 25|1@1+ (1,0) [0|0] "" GTW,MCU
 SG_ APS_w219_lcTempUnavailableSpeed : 26|1@1+ (1,0) [0|0] "" GTW,MCU
 SG_ APS_w220_lcTempUnavailableRoad : 27|1@1+ (1,0) [0|0] "" GTW,MCU
 SG_ APS_w221_accRadarBlind : 28|1@1+ (1,0) [0|0] "" GTW,MCU
 SG_ APS_w222_accCameraBlind : 29|1@1+ (1,0) [0|0] "" GTW,MCU
 SG_ APS_w223_accObjectInPath : 30|1@1+ (1,0) [0|0] "" GTW,MCU
 SG_ APS_w224_accCameraCalibration : 31|1@1+ (1,0) [0|0] "" GTW,MCU
 SG_ APS_w225_lcDegradedVisSpeedLmt : 32|1@1+ (1,0) [0|0] "" GTW,MCU
 SG_ APS_w226_lcCamCalNeededSpeedLmt : 33|1@1+ (1,0) [0|0] "" GTW,MCU
 SG_ APS_w227_virtualWallBlocked : 34|1@1+ (1,0) [0|0] "" GTW,MCU
 SG_ APS_w228_DEPRECATED : 35|1@1+ (1,0) [0|0] "" GTW,MCU
 SG_ APS_w229_alcUltrasoundDamaged : 36|1@1+ (1,0) [0|1] "" GTW,MCU
 SG_ APS_w230_alcUltrasoundBlocked : 37|1@1+ (1,0) [0|1] "" GTW,MCU
 SG_ APS_w231_idfEvent : 38|1@1+ (1,0) [0|1] "" GTW,MCU
 SG_ APS_w232_laneChangeRequested : 39|1@1+ (1,0) [0|1] "" GTW,MCU
 SG_ APS_w233_laneChangeCancelled : 40|1@1+ (1,0) [0|1] "" GTW,MCU

BO_ 267 ASD_A1: 5 EAS
 SG_ FL_Lvl : 0|8@1+ (1,-100) [-100|153] "mm" GTW
 SG_ FR_Lvl : 8|8@1+ (1,-100) [-100|153] "mm" GTW
 SG_ RL_Lvl : 16|8@1+ (1,-100) [-100|153] "mm" GTW
 SG_ RR_Lvl : 24|8@1+ (1,-100) [-100|153] "mm" GTW
 SG_ FL_Lvl_Adj : 32|1@1+ (1,0) [0|1] "" GTW
 SG_ FR_Lvl_Adj : 33|1@1+ (1,0) [0|1] "" GTW
 SG_ RL_Lvl_Adj : 34|1@1+ (1,0) [0|1] "" GTW
 SG_ RR_Lvl_Adj : 35|1@1+ (1,0) [0|1] "" GTW
 SG_ HSenNC : 36|1@1+ (1,0) [0|1] "" GTW

BO_ 283 ASD_A2: 5 EAS
 SG_ Wala_LC_red : 0|1@1+ (1,0) [0|1] "" GTW
 SG_ Wala_LC_yel : 1|1@1+ (1,0) [0|1] "" GTW
 SG_ EAS_extremeHighLevel : 2|1@1+ (1,0) [0|0] "" GTW
 SG_ EAS_extremeLowLevel : 3|1@1+ (1,0) [0|0] "" GTW
 SG_ CompRun : 4|1@1+ (1,0) [0|1] "" GTW
 SG_ LC_LimpHomeMode : 5|3@1- (1,0) [0|7] "" GTW
 SG_ EAS_Req_VLimit : 8|1@1+ (1,0) [0|0] "" GTW
 SG_ EAS_Req_ESP : 9|1@1+ (1,0) [0|0] "" GTW
 SG_ EAS_reqReduceSpeedDisp : 10|1@1+ (1,0) [0|0] "" GTW
 SG_ SysDisabled : 11|1@1+ (1,0) [0|1] "" GTW
 SG_ TargetLevel : 12|3@1+ (1,0) [0|7] "" GTW
 SG_ CurrentLevel : 16|3@1+ (1,0) [0|7] "" DAS,GTW
 SG_ ASD_A2_Counter : 20|4@1+ (1,0) [0|15] "" GTW
 SG_ EAS_LowLevelLamp : 24|1@1+ (1,0) [0|0] "" GTW
 SG_ EAS_NormalLevelLamp : 25|1@1+ (1,0) [0|0] "" GTW
 SG_ EAS_HighLevelLamp : 26|1@1+ (1,0) [0|0] "" GTW
 SG_ EAS_JackModeLamp : 27|1@1+ (1,0) [0|0] "" GTW
 SG_ EAS_VeryHighLevelLamp : 28|1@1+ (1,0) [0|0] "" GTW
 SG_ EAS_LevelingNotPossible : 29|1@1+ (1,0) [0|0] "" GTW
 SG_ EAS_LevelingNotAllowed : 30|1@1+ (1,0) [0|0] "" GTW
 SG_ EAS_VeryLowLevelLamp : 31|1@1+ (1,0) [0|0] "" GTW
 SG_ ASD_A2_Checksum : 32|8@1+ (1,0) [0|255] "" GTW

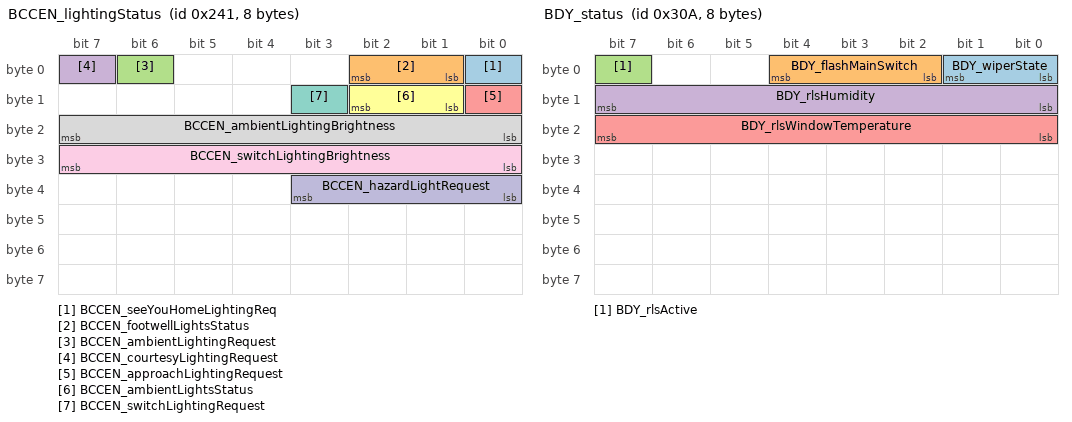
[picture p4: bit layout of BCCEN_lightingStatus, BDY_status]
BO_ 577 BCCEN_lightingStatus: 8 GTW
 SG_ BCCEN_seeYouHomeLightingReq : 0|1@0+ (1,0) [0|1] "" Vector__XXX
 SG_ BCCEN_footwellLightsStatus : 2|2@0+ (1,0) [0|3] "" Vector__XXX
 SG_ BCCEN_ambientLightingRequest : 6|1@0+ (1,0) [0|1] "" Vector__XXX
 SG_ BCCEN_courtesyLightingRequest : 7|1@0+ (1,0) [0|1] "" VCSEATD
 SG_ BCCEN_approachLightingRequest : 8|1@0+ (1,0) [0|1] "" Vector__XXX
 SG_ BCCEN_ambientLightsStatus : 10|2@0+ (1,0) [0|3] "" Vector__XXX
 SG_ BCCEN_switchLightingRequest : 11|1@0+ (1,0) [0|1] "" Vector__XXX
 SG_ BCCEN_ambientLightingBrightness : 23|8@0+ (0.5,0) [0|100] "%" Vector__XXX
 SG_ BCCEN_switchLightingBrightness : 31|8@0+ (0.5,0) [0|100] "%" Vector__XXX
 SG_ BCCEN_hazardLightRequest : 35|4@0+ (1,0) [0|8] "" Vector__XXX

BO_ 652 BCS2L_firstRowRecall: 8 GTW
 SG_ BCS2L_firstRowRecallIndex M : 0|1@1+ (1,0) [0|1] "" VCSEATD,VCSEATP
 SG_ BCS2L_firstRowRecallStop : 1|1@1+ (1,0) [0|1] "" VCSEATD,VCSEATP
 SG_ BCS2L_driverSeatRecallActive m0 : 2|1@1+ (1,0) [0|1] "" VCSEATD
 SG_ BCS2L_driverSeatTrackPos m0 : 3|10@1- (4,0) [-2048|2044] "mm" VCSEATD
 SG_ BCS2L_driverSeatBackPos m0 : 18|12@1- (0.1,0) [-204.8|204.7] "deg" VCSEATD
 SG_ BCS2L_driverSeatLiftPos m0 : 33|10@1- (4,0) [-2048|2044] "mm" VCSEATD
 SG_ BCS2L_driverSeatTiltPos m0 : 48|12@1- (0.1,0) [-204.8|204.7] "deg" VCSEATD
 SG_ BCS2L_passengerSeatRecallActive m1 : 2|1@1+ (1,0) [0|1] "" VCSEATP
 SG_ BCS2L_passengerSeatTrackPos m1 : 3|10@1- (4,0) [-2048|2044] "mm" VCSEATP
 SG_ BCS2L_passengerSeatBackPos m1 : 18|12@1- (0.1,0) [-204.8|204.7] "deg" VCSEATP
 SG_ BCS2L_passengerSeatLiftPos m1 : 33|10@1- (4,0) [-2048|2044] "mm" VCSEATP
 SG_ BCS2L_passengerSeatTiltPos m1 : 48|12@1- (0.1,0) [-204.8|204.7] "deg" VCSEATP

BO_ 653 BCS2R_firstRowRecall: 8 GTW
 SG_ BCS2R_firstRowRecallIndex M : 0|1@1+ (1,0) [0|1] "" VCSEATD,VCSEATP
 SG_ BCS2R_firstRowRecallStop : 1|1@1+ (1,0) [0|1] "" VCSEATD,VCSEATP
 SG_ BCS2R_driverSeatRecallActive m0 : 2|1@1+ (1,0) [0|1] "" VCSEATD
 SG_ BCS2R_driverSeatTrackPos m0 : 3|10@1- (4,0) [-2048|2044] "mm" VCSEATD
 SG_ BCS2R_driverSeatBackPos m0 : 18|12@1- (0.1,0) [-204.8|204.7] "deg" VCSEATD
 SG_ BCS2R_driverSeatLiftPos m0 : 33|10@1- (4,0) [-2048|2044] "mm" VCSEATD
 SG_ BCS2R_driverSeatTiltPos m0 : 48|12@1- (0.1,0) [-204.8|204.7] "deg" VCSEATD
 SG_ BCS2R_passengerSeatRecallActive m1 : 2|1@1+ (1,0) [0|1] "" VCSEATP
 SG_ BCS2R_passengerSeatTrackPos m1 : 3|10@1- (4,0) [-2048|2044] "mm" VCSEATP
 SG_ BCS2R_passengerSeatBackPos m1 : 18|12@1- (0.1,0) [-204.8|204.7] "deg" VCSEATP
 SG_ BCS2R_passengerSeatLiftPos m1 : 33|10@1- (4,0) [-2048|2044] "mm" VCSEATP
 SG_ BCS2R_passengerSeatTiltPos m1 : 48|12@1- (0.1,0) [-204.8|204.7] "deg" VCSEATP

BO_ 778 BDY_status: 8 BDY
 SG_ BDY_wiperState : 1|2@0+ (1,0) [0|0] "" DAS,GTW
 SG_ BDY_flashMainSwitch : 4|3@0+ (1,0) [0|7] "" DAS,GTW
 SG_ BDY_rlsActive : 7|1@0+ (1,0) [0|0] "" DAS,GTW
 SG_ BDY_rlsHumidity : 15|8@0+ (0.5,0) [0|100] "%" DAS,GTW
 SG_ BDY_rlsWindowTemperature : 23|8@0+ (0.5,-40) [-40|85] "C" DAS,GTW

CM_ SG_ 1481 APS_sw019_numFreeBytes "A positive value denotes the number of bytes remaining in the stack before it will overflow. A negative value indicates that the stack has overflown by those many bytes. Any overflow beyond 191 bytes is snapped back and reported as -191 byte overflow.";
CM_ SG_ 1481 APS_sw019_timeStamp "Time stamp in milliseconds after the ECU health monitor gets initialized.";
CM_ SG_ 1481 APS_sw027_Clock_Monitor_0_Low "External crystal oscillator, PLL 0 or Internal RC oscillator  under the rated frequency limits.";
CM_ SG_ 1481 APS_sw027_Clock_Monitor_0_Off "External crystal oscillator, PLL 0 or Internal RC oscillator either over or under the rated frequency limits.";
CM_ SG_ 1481 APS_sw027_f_PLL_1_Off "PLL 1 frequency over or under allowable limits.";
CM_ SG_ 1481 APS_sw194_timeInHold "Time in ms since ACC entered HOLD state";
CM_ SG_ 637 APS_eacAllow "Inhibit / Allow for EPAS EAC feature";
CM_ SG_ 915 APS_hvacPowerRequest "Set to get GTW to turn on the hvac rail. Clear when hvac rail no longer needed for this function";
CM_ SG_ 1050 APS_primaryTurbo "The Turbo that currently has control of the CAN bus and cameras";
CM_ SG_ 1050 APS_A_arbState "ARB state machine state of the primary Turbo";
CM_ SG_ 1050 APS_A_powerState "POWER state machine state of the primary Turbo";
CM_ SG_ 1050 APS_A_sleepState "SLEEP state machine state of the primary Turbo";
CM_ SG_ 1050 APS_A_resetState "RESET state machine state of the primary Turbo";
CM_ SG_ 1050 APS_A_faultState "FAULT state machine state of the primary Turbo";
CM_ SG_ 1050 APS_secondaryTurbo "The Turbo that does not have control of the CAN bus and cameras";
CM_ SG_ 1050 APS_B_arbState "ARB state machine state of the secondary Turbo";
CM_ SG_ 1050 APS_B_powerState "POWER state machine state of the secondary Turbo";
CM_ SG_ 1050 APS_B_sleepState "SLEEP state machine state of the secondary Turbo";
CM_ SG_ 1050 APS_B_resetState "RESET state machine state of the secondary Turbo";
CM_ SG_ 1050 APS_B_faultState "FAULT state machine state of the secondary Turbo";
CM_ SG_ 267 FL_Lvl "Front left height in mm (with offset -100 mm); 0mm is standard (nominal); zeroed by ride height calibration.";
CM_ SG_ 267 FR_Lvl "Front right height in mm (with offset -100 mm); 0mm is standard (nominal); zeroed by ride height calibration.";
CM_ SG_ 267 RL_Lvl "Rear left height in mm (with offset -100 mm); 0mm is standard (nominal); zeroed by ride height calibration.";
CM_ SG_ 267 RR_Lvl "Rear right height in mm (with offset -100 mm); 0mm is standard (nominal); zeroed by ride height calibration.";
CM_ SG_ 267 FL_Lvl_Adj "Is set when FL corner is leveling";
CM_ SG_ 267 FR_Lvl_Adj "Is set when FR corner is leveling";
CM_ SG_ 267 RL_Lvl_Adj "Is set when RL corner is leveling";
CM_ SG_ 267 RR_Lvl_Adj "Is set when RR corner is leveling";
CM_ SG_ 283 Wala_LC_red "Warning lamp level control No level functionality";
CM_ SG_ 283 Wala_LC_yel "Warning lamp level control Limited functionality";
CM_ SG_ 283 CompRun "Is set when the compressor is running";
CM_ SG_ 283 LC_LimpHomeMode "Actual limp home mode Level control";
CM_ SG_ 283 EAS_Req_VLimit "EAS requests 30 kph speed limit due to EAS failure.";
CM_ SG_ 283 EAS_Req_ESP "EAS requests ESP is engaged due to EAS failure. Overrides user initiated disable";
CM_ SG_ 283 EAS_reqReduceSpeedDisp "EAS failure, EAS requests display shows Please Reduce Speed.";
CM_ SG_ 283 SysDisabled "Is set when Level control is disabled";
CM_ SG_ 283 TargetLevel "ECU height commanded.";
CM_ SG_ 283 CurrentLevel "ECU height observed.";
CM_ SG_ 283 ASD_A2_Counter "Message counter for ASD_A2 message: increments in each message.";
CM_ SG_ 283 EAS_LowLevelLamp "EAS to HMI Low Level Lamp On";
CM_ SG_ 283 EAS_NormalLevelLamp "EAS to HMI Normal Level Lamp On";
CM_ SG_ 283 EAS_HighLevelLamp "EAS to HMI High Level Lamp On";
CM_ SG_ 283 EAS_JackModeLamp "EAS to HMI Jack Mode Lamp On";
CM_ SG_ 283 EAS_VeryHighLevelLamp "EAS to HMI Very High Level Lamp On";
CM_ SG_ 283 EAS_LevelingNotPossible "EAS to HMI Leveling Not Possible Displayed";
CM_ SG_ 283 EAS_LevelingNotAllowed "EAS to HMI Leveling Not Allowed Displayed";
CM_ SG_ 283 EAS_VeryLowLevelLamp "EAS to HMI Very Low Level Lamp On";
CM_ SG_ 283 ASD_A2_Checksum "Message checksum for ASD_A2 message: sum of all bytes in message (Unused fields are set to 0) + originating CAN ID (0x1 + 0x1B = 0x1C).";
CM_ SG_ 577 BCCEN_hazardLightRequest "Tells if hazard lights are requested and why";
CM_ SG_ 652 BCS2L_firstRowRecallIndex "multiplexer";
CM_ SG_ 652 BCS2L_firstRowRecallStop "notifies controller to stop profile recall action";
CM_ SG_ 652 BCS2L_driverSeatRecallActive "signals when driver seat presets are being recalled";
CM_ SG_ 652 BCS2L_driverSeatTrackPos "Track position of front driver seat";
CM_ SG_ 652 BCS2L_driverSeatBackPos "Back tilt position of front driver seat";
CM_ SG_ 652 BCS2L_driverSeatLiftPos "Lift position of front driver seat";
CM_ SG_ 652 BCS2L_driverSeatTiltPos "Tilt position of front driver seat";
CM_ SG_ 652 BCS2L_passengerSeatRecallActive "signals when passenger seat presets are being recalled";
CM_ SG_ 652 BCS2L_passengerSeatTrackPos "Track position of front passenger seat";
CM_ SG_ 652 BCS2L_passengerSeatBackPos "Back tilt position of front passenger seat";
CM_ SG_ 652 BCS2L_passengerSeatLiftPos "Lift position of front passenger seat";
CM_ SG_ 652 BCS2L_passengerSeatTiltPos "Tilt position of front passenger seat";
CM_ SG_ 653 BCS2R_firstRowRecallIndex "multiplexer";
CM_ SG_ 653 BCS2R_firstRowRecallStop "notifies controller to stop profile recall action";
CM_ SG_ 653 BCS2R_driverSeatRecallActive "signals when driver seat presets are being recalled";
CM_ SG_ 653 BCS2R_driverSeatTrackPos "Track position of front driver seat";
CM_ SG_ 653 BCS2R_driverSeatBackPos "Back tilt position of front driver seat";
CM_ SG_ 653 BCS2R_driverSeatLiftPos "Lift position of front driver seat";
CM_ SG_ 653 BCS2R_driverSeatTiltPos "Tilt position of front driver seat";
CM_ SG_ 653 BCS2R_passengerSeatRecallActive "signals when passenger seat presets are being recalled";
CM_ SG_ 653 BCS2R_passengerSeatTrackPos "Track position of front passenger seat";
CM_ SG_ 653 BCS2R_passengerSeatBackPos "Back tilt position of front passenger seat";
CM_ SG_ 653 BCS2R_passengerSeatLiftPos "Lift position of front passenger seat";
CM_ SG_ 653 BCS2R_passengerSeatTiltPos "Tilt position of front passenger seat";
BA_DEF_ BO_ "AlertLogSubSystemId" INT 0 0;
BA_DEF_ BO_ "AlertType" INT 0 4;
BA_DEF_ BO_ "AppBotschaft" ENUM "nein","ja";
BA_DEF_ BO_ "DiagRequest" ENUM "No","Yes";
BA_DEF_ BO_ "DiagResponse" ENUM "No","Yes";
BA_DEF_ BO_ "ETHGatewayMessageSendType" ENUM "UseGenMsgSendType","onWrite","noAutoCode";
BA_DEF_ BO_ "ETHId" STRING ;
BA_DEF_ BO_ "GatewayHandlerEnum" ENUM "noHandler","uds","alertLog","messageLogOnReception","udsClient";
BA_DEF_ BO_ "GatewayMessageAtomic" ENUM "No","Yes";
BA_DEF_ BO_ "GatewayMessageSendType" ENUM "UseGenMsgSendType","onWrite","noAutoCode";
BA_DEF_ BO_ "GenMsgCycleTime" INT 0 0;
BA_DEF_ BO_ "GenMsgCycleTimeFast" INT 0 0;
BA_DEF_ BO_ "GenMsgDelayTime" INT 0 0;
BA_DEF_ BO_ "GenMsgForceMiaCheck" ENUM "No","Yes";
BA_DEF_ BO_ "GenMsgGatewayNotification" STRING ;
BA_DEF_ BO_ "GenMsgILSupport" ENUM "No","Yes";
BA_DEF_ BO_ "GenMsgSaltingFunction" ENUM "No","Yes";
BA_DEF_ BO_ "GenMsgSendType" ENUM "Cyclic","NotUsed","NotUsed","NotUsed","NotUsed","NotUsed","NotUsed","IfActive","NoMsgSendType","Sporadic";
BA_DEF_ BO_ "GenMsgStartValue" STRING ;
BA_DEF_ BO_ "GenMsgTimeOut" INT 0 0;
BA_DEF_ BO_ "MessageIdType" ENUM "normal","udsRequest","udsResponse","udsReserved","udsFunctionalRequest","networkManagement","bootloader","xcp","dtc","diagnostic","vendorExempt";
BA_DEF_ BO_ "NWMBotschaft" ENUM "nein","ja";
BA_DEF_ BO_ "NmMessage" ENUM "No","Yes";
BA_DEF_ BO_ "SubSystemId" INT 0 256;
BA_DEF_ BO_ "UsesChecksum" ENUM "No","Yes";
BA_DEF_ SG_ "FieldType" STRING ;
BA_DEF_ SG_ "FlexKomComment" STRING ;
BA_DEF_ SG_ "FlexKomIsMotorola" ENUM "nein","ja";
BA_DEF_ SG_ "FlexKomSID" INT 0 2147483647;
BA_DEF_ SG_ "FlexKomSigLaenge" INT 0 64;
BA_DEF_ SG_ "FlexKomSigName" STRING ;
BA_DEF_ SG_ "FlexKomSigStartPos" INT 0 63;
BA_DEF_ SG_ "FlexKomSigStartValue" STRING ;
BA_DEF_ SG_ "Gatewaysignal" INT 0 1;
BA_DEF_ SG_ "GenSigCycleTime" INT 0 0;
BA_DEF_ SG_ "GenSigCycleTimeActive" INT 0 0;
BA_DEF_ SG_ "GenSigPersistent" ENUM "No","Yes";
BA_DEF_ SG_ "GenSigSNA" STRING ;
BA_DEF_ SG_ "GenSigSendType" ENUM "Cyclic","OnWrite","OnWriteWithRepetition","OnChange","OnChangeWithRepetition","IfActive","IfActiveWithRepetition","NoSigSendType","NotUsed","NotUsed","NotUsed","NotUsed","NotUsed";
BA_DEF_ SG_ "GenSigStartValue" INT 0 0;
BA_DEF_ SG_ "GenSigTimeout_CGW" INT 0 65535;
BA_DEF_ SG_ "GenSigTimeout_DRVU" INT 0 65535;
BA_DEF_ SG_ "GenSigTimeout_ECM" INT 0 65535;
BA_DEF_ SG_ "GenSigTimeout_EIS" INT 0 65535;
BA_DEF_ SG_ "GenSigTimeout_EPS" INT 0 65535;
BA_DEF_ SG_ "GenSigTimeout_ESP_ABR" INT 0 65535;
BA_DEF_ SG_ "GenSigTimeout_IC" INT 0 65535;
BA_DEF_ SG_ "GenSigTimeout_MPC" INT 0 65535;
BA_DEF_ SG_ "GenSigTimeout_NV" INT 0 65535;
BA_DEF_ SG_ "GenSigTimeout_ORC" INT 0 65535;
BA_DEF_ SG_ "GenSigTimeout_PTS" INT 0 65535;
BA_DEF_ SG_ "GenSigTimeout_RBTM_FL" INT 0 65535;
BA_DEF_ SG_ "GenSigTimeout_RBTM_FR" INT 0 65535;
BA_DEF_ SG_ "GenSigTimeout_RDU" INT 0 65535;
BA_DEF_ SG_ "GenSigTimeout_SCCM" INT 0 65535;
BA_DEF_ SG_ "GenSigTimeout_SPC" INT 0 65535;
BA_DEF_ SG_ "GenSigTimeout_TPM" INT 0 65535;
BA_DEF_ SG_ "LogSignal" STRING ;
BA_DEF_ SG_ "PektronUpdateBitType" ENUM "Not used","Has update bit","Is update bit";
BA_DEF_REL_ BU_SG_REL_ "GenSigTimeoutTime" INT 0 0;

BA_DEF_DEF_ "AlertLogSubSystemId" 0;
BA_DEF_DEF_ "AlertType" 4;
BA_DEF_DEF_ "AppBotschaft" "nein";
BA_DEF_DEF_ "DiagRequest" "No";
BA_DEF_DEF_ "DiagResponse" "No";
BA_DEF_DEF_ "ETHGatewayMessageSendType" "UseGenMsgSendType";
BA_DEF_DEF_ "ETHId" "";
BA_DEF_DEF_ "FieldType" "";
BA_DEF_DEF_ "FlexKomComment" "";
BA_DEF_DEF_ "FlexKomIsMotorola" "";
BA_DEF_DEF_ "FlexKomSID" 0;
BA_DEF_DEF_ "FlexKomSigLaenge" 0;
BA_DEF_DEF_ "FlexKomSigName" "";
BA_DEF_DEF_ "FlexKomSigStartPos" 0;
BA_DEF_DEF_ "FlexKomSigStartValue" "";
BA_DEF_DEF_ "GatewayHandlerEnum" "noHandler";
BA_DEF_DEF_ "GatewayMessageAtomic" "No";
BA_DEF_DEF_ "GatewayMessageSendType" "UseGenMsgSendType";
BA_DEF_DEF_ "Gatewaysignal" 0;
BA_DEF_DEF_ "GenMsgCycleTime" 0;
BA_DEF_DEF_ "GenMsgCycleTimeFast" 0;
BA_DEF_DEF_ "GenMsgDelayTime" 0;
BA_DEF_DEF_ "GenMsgForceMiaCheck" "No";
BA_DEF_DEF_ "GenMsgGatewayNotification" "";
BA_DEF_DEF_ "GenMsgILSupport" "Yes";
BA_DEF_DEF_ "GenMsgSaltingFunction" "No";
BA_DEF_DEF_ "GenMsgSendType" "Cyclic";
BA_DEF_DEF_ "GenMsgStartValue" "";
BA_DEF_DEF_ "GenMsgTimeOut" 0;
BA_DEF_DEF_ "GenSigCycleTime" 0;
BA_DEF_DEF_ "GenSigCycleTimeActive" 0;
BA_DEF_DEF_ "GenSigPersistent" "No";
BA_DEF_DEF_ "GenSigSNA" "";
BA_DEF_DEF_ "GenSigSendType" "Cyclic";
BA_DEF_DEF_ "GenSigStartValue" 0;
BA_DEF_DEF_ "GenSigTimeout_CGW" 0;
BA_DEF_DEF_ "GenSigTimeout_DRVU" 0;
BA_DEF_DEF_ "GenSigTimeout_ECM" 0;
BA_DEF_DEF_ "GenSigTimeout_EIS" 0;
BA_DEF_DEF_ "GenSigTimeout_EPS" 0;
BA_DEF_DEF_ "GenSigTimeout_ESP_ABR" 0;
BA_DEF_DEF_ "GenSigTimeout_IC" 0;
BA_DEF_DEF_ "GenSigTimeout_MPC" 0;
BA_DEF_DEF_ "GenSigTimeout_NV" 0;
BA_DEF_DEF_ "GenSigTimeout_ORC" 0;
BA_DEF_DEF_ "GenSigTimeout_PTS" 0;
BA_DEF_DEF_ "GenSigTimeout_RBTM_FL" 0;
BA_DEF_DEF_ "GenSigTimeout_RBTM_FR" 0;
BA_DEF_DEF_ "GenSigTimeout_RDU" 0;
BA_DEF_DEF_ "GenSigTimeout_SCCM" 0;
BA_DEF_DEF_ "GenSigTimeout_SPC" 0;
BA_DEF_DEF_ "GenSigTimeout_TPM" 0;
BA_DEF_DEF_ "LogSignal" "";
BA_DEF_DEF_ "MessageIdType" "normal";
BA_DEF_DEF_ "NWMBotschaft" "nein";
BA_DEF_DEF_ "NmMessage" "No";
BA_DEF_DEF_ "PektronUpdateBitType" "Not used";
BA_DEF_DEF_ "SubSystemId" 0;
BA_DEF_DEF_ "UsesChecksum" "No";
BA_DEF_DEF_REL_ "GenSigTimeoutTime" 0;
BA_ "AlertLogSubSystemId" BO_ 1481 254;
BA_ "GatewayHandlerEnum" BO_ 1481 2;
BA_ "GenMsgSendType" BO_ 1481 8;
BA_ "GenMsgCycleTime" BO_ 1036 100;
BA_ "GenMsgCycleTime" BO_ 637 100;
BA_ "GenMsgCycleTime" BO_ 915 500;
BA_ "GenMsgGatewayNotification" BO_ 915 "apsPowerHandler";
BA_ "GenMsgCycleTime" BO_ 1050 100;
BA_ "GatewayMessageSendType" BO_ 969 1;
BA_ "GenMsgCycleTime" BO_ 969 500;
BA_ "GenMsgCycleTime" BO_ 1115 40;
BA_ "GenMsgCycleTime" BO_ 971 100;
BA_ "AlertType" BO_ 811 0;
BA_ "ETHId" BO_ 811 "RETAIN_ID";
BA_ "GatewayMessageSendType" BO_ 811 1;
BA_ "GenMsgCycleTime" BO_ 811 1000;
BA_ "AlertType" BO_ 876 0;
BA_ "ETHId" BO_ 876 "RETAIN_ID";
BA_ "GatewayMessageSendType" BO_ 876 1;
BA_ "GenMsgCycleTime" BO_ 876 1000;
BA_ "AlertType" BO_ 1113 0;
BA_ "ETHId" BO_ 1113 "RETAIN_ID";
BA_ "GatewayMessageSendType" BO_ 1113 1;
BA_ "GenMsgCycleTime" BO_ 1113 1000;
BA_ "AlertType" BO_ 848 1;
BA_ "ETHId" BO_ 848 "RETAIN_ID";
BA_ "GatewayMessageSendType" BO_ 848 1;
BA_ "GenMsgCycleTime" BO_ 848 1000;
BA_ "GenMsgCycleTime" BO_ 267 100;
BA_ "GenMsgCycleTimeFast" BO_ 267 100;
BA_ "GenMsgDelayTime" BO_ 267 20;
BA_ "GenMsgTimeOut" BO_ 267 500;
BA_ "GenMsgCycleTime" BO_ 283 100;
BA_ "GenMsgCycleTimeFast" BO_ 283 100;
BA_ "GenMsgDelayTime" BO_ 283 20;
BA_ "GenMsgTimeOut" BO_ 283 500;
BA_ "GenMsgCycleTime" BO_ 577 100;
BA_ "GatewayMessageSendType" BO_ 652 1;
BA_ "GenMsgCycleTime" BO_ 652 500;
BA_ "GatewayMessageSendType" BO_ 653 1;
BA_ "GenMsgCycleTime" BO_ 653 500;
BA_ "GenMsgCycleTime" BO_ 778 1000;
BA_ "FieldType" SG_ 1481 APS_alertID "APS_alertID";
BA_ "GenSigStartValue" SG_ 1481 APS_sw018_maxThreshold 50;
BA_ "GenSigStartValue" SG_ 1481 APS_sw019_numFreeBytes 191;
BA_ "FieldType" SG_ 1481 APS_sw024_currentVehicleApp "APS_vehicleApp";
BA_ "GenSigSNA" SG_ 1481 APS_sw042_health_state "7";
BA_ "GenSigSNA" SG_ 1481 APS_sw042_epas_error_code "15";
BA_ "FieldType" SG_ 1481 APS_sw060_collisionWarningSource "FCM_collisionWarningSource";
BA_ "GenSigStartValue" SG_ 1481 APS_sw062_HorizontalMisalignment 32767.3084205;
BA_ "GenSigStartValue" SG_ 1481 APS_sw062_VerticalMisalignment 511.497323164;
BA_ "GenSigSNA" SG_ 1481 APS_sw069_diAPState "15";
BA_ "GenSigSNA" SG_ 1481 APS_sw070_currTireFitment "3";
BA_ "GenSigSNA" SG_ 1481 APS_sw070_lastTireFitment "3";
BA_ "GenSigSNA" SG_ 1481 APS_sw070_diGear "7";
BA_ "GenSigSNA" SG_ 1481 APS_sw071_selfParkType "7";
BA_ "GenSigSNA" SG_ 1481 APS_sw071_roadClass "0";
BA_ "FieldType" SG_ 1481 APS_sw073_escalateLDWreason "LC_escalateLDWreason";
BA_ "GenSigSNA" SG_ 1481 APS_sw074_roadClass "0";
BA_ "FieldType" SG_ 1481 APS_sw131_trapClass "APS_sw131_trapClass";
BA_ "FieldType" SG_ 1481 APS_sw132_mismatchType "AP_versionMismatchType";
BA_ "FieldType" SG_ 1481 APS_sw135_appCriticalReason "AP_criticalReason";
BA_ "GenSigSNA" SG_ 1481 APS_sw151_apWatchDogState "7";
BA_ "GenSigSNA" SG_ 1481 APS_sw151_diGear "7";
BA_ "FieldType" SG_ 1481 APS_sw151_recoveryPathway "AP_recoveryPathway";
BA_ "FieldType" SG_ 1481 APS_sw151_parkerType "AP_parkerType";
BA_ "FieldType" SG_ 1481 APS_sw153_eacInhibitReason "APS_eacInhibitReason";
BA_ "FieldType" SG_ 1481 APS_sw153_eacInternalState "APS_eacInternalState";
BA_ "FieldType" SG_ 1481 APS_sw154_ethSwitchState "APS_switchState";
BA_ "FieldType" SG_ 1481 APS_sw159_apbCriticalReason "AP_criticalReason";
BA_ "FieldType" SG_ 1481 APS_sw160_mismatchType "AP_versionMismatchType";
BA_ "GenSigSNA" SG_ 1481 APS_sw194_leadDx "255";
BA_ "GenSigSNA" SG_ 1481 APS_sw194_leadVx "31";
BA_ "GenSigSNA" SG_ 1481 APS_sw194_leadAx "31";
BA_ "GenSigSNA" SG_ 1481 APS_sw194_reasonForHold "15";
BA_ "GenSigSNA" SG_ 1481 APS_sw199_abortCodePARK "31";
BA_ "GenSigSNA" SG_ 1481 APS_sw203_roadClass "0";
BA_ "GenSigSNA" SG_ 1481 APS_sw203_controlType "15";
BA_ "GenSigSNA" SG_ 1481 APS_sw204_frLeftMiddle "255";
BA_ "GenSigSNA" SG_ 1481 APS_sw204_frRightMiddle "255";
BA_ "GenSigSNA" SG_ 1481 APS_sw204_frRight "255";
BA_ "GenSigSNA" SG_ 1481 APS_sw204_frLeft "255";
BA_ "GenSigSNA" SG_ 1481 APS_sw204_frMiddle "255";
BA_ "GenSigSNA" SG_ 1481 APS_sw205_rrRightMiddle "255";
BA_ "GenSigSNA" SG_ 1481 APS_sw205_rrLeftMiddle "255";
BA_ "GenSigSNA" SG_ 1481 APS_sw205_rrRight "255";
BA_ "GenSigSNA" SG_ 1481 APS_sw205_rrLeft "255";
BA_ "GenSigSNA" SG_ 1481 APS_sw205_rrMiddle "255";
BA_ "GenSigSNA" SG_ 1481 APS_sw205_oocDistance "255";
BA_ "FieldType" SG_ 1481 APS_sw207_lcUnavailableReason "LC_unavailableReason";
BA_ "GenSigSNA" SG_ 1481 APS_sw218_handsOnState "15";
BA_ "FieldType" SG_ 1036 APS_nmKeepAwakeReason "APS_NM_keepAwakeReason";
BA_ "GenSigSNA" SG_ 1036 APS_nmKeepAwakeReason "0";
BA_ "LogSignal" SG_ 1036 APS_nmKeepAwakeReason "onChange";
BA_ "FieldType" SG_ 637 APS_eacAllow "APS_eacAllow";
BA_ "GenSigSNA" SG_ 637 APS_eacAllow "3";
BA_ "LogSignal" SG_ 637 APS_eacAllow "onChange";
BA_ "LogSignal" SG_ 915 APS_hvacPowerRequest "onChange";
BA_ "FieldType" SG_ 1050 APS_primaryTurbo "APS_turbo";
BA_ "LogSignal" SG_ 1050 APS_primaryTurbo "onChange";
BA_ "FieldType" SG_ 1050 APS_A_arbState "APS_turboArbState";
BA_ "LogSignal" SG_ 1050 APS_A_arbState "onChange";
BA_ "FieldType" SG_ 1050 APS_A_powerState "APS_turboPowerState";
BA_ "LogSignal" SG_ 1050 APS_A_powerState "onChange";
BA_ "FieldType" SG_ 1050 APS_A_sleepState "APS_turboSleepState";
BA_ "LogSignal" SG_ 1050 APS_A_sleepState "onChange";
BA_ "FieldType" SG_ 1050 APS_A_resetState "APS_turboResetState";
BA_ "LogSignal" SG_ 1050 APS_A_resetState "onChange";
BA_ "FieldType" SG_ 1050 APS_A_faultState "APS_turboFaultState";
BA_ "LogSignal" SG_ 1050 APS_A_faultState "onChange";
BA_ "FieldType" SG_ 1050 APS_secondaryTurbo "APS_turbo";
BA_ "LogSignal" SG_ 1050 APS_secondaryTurbo "onChange";
BA_ "FieldType" SG_ 1050 APS_B_arbState "APS_turboArbState";
BA_ "LogSignal" SG_ 1050 APS_B_arbState "onChange";
BA_ "FieldType" SG_ 1050 APS_B_powerState "APS_turboPowerState";
BA_ "LogSignal" SG_ 1050 APS_B_powerState "onChange";
BA_ "FieldType" SG_ 1050 APS_B_sleepState "APS_turboSleepState";
BA_ "LogSignal" SG_ 1050 APS_B_sleepState "onChange";
BA_ "FieldType" SG_ 1050 APS_B_resetState "APS_turboResetState";
BA_ "LogSignal" SG_ 1050 APS_B_resetState "onChange";
BA_ "FieldType" SG_ 1050 APS_B_faultState "APS_turboFaultState";
BA_ "LogSignal" SG_ 1050 APS_B_faultState "onChange";
BA_ "FieldType" SG_ 969 APS_appStatusMonitorState "APS_statusMonitorState";
BA_ "LogSignal" SG_ 969 APS_appStatusMonitorState "onChange";
BA_ "FieldType" SG_ 969 APS_vehBehaviorState "APS_vehBehaviorState";
BA_ "LogSignal" SG_ 969 APS_vehBehaviorState "onChange";
BA_ "FieldType" SG_ 969 APS_canMaster "APS_canMaster";
BA_ "GenSigSNA" SG_ 969 APS_canMaster "3";
BA_ "LogSignal" SG_ 969 APS_canMaster "onChange";
BA_ "FieldType" SG_ 969 APS_appGpioState "APS_parkerGpioState";
BA_ "LogSignal" SG_ 969 APS_appGpioState "onChange";
BA_ "FieldType" SG_ 969 APS_eacInternalState "APS_eacInternalState";
BA_ "FieldType" SG_ 969 APS_switchState "APS_switchState";
BA_ "LogSignal" SG_ 969 APS_switchState "onChange";
BA_ "FieldType" SG_ 969 APS_apbStatusMonitorState "APS_statusMonitorState";
BA_ "LogSignal" SG_ 969 APS_apbStatusMonitorState "onChange";
BA_ "FieldType" SG_ 969 APS_apbGpioState "APS_parkerGpioState";
BA_ "LogSignal" SG_ 969 APS_apbGpioState "onChange";
BA_ "FieldType" SG_ 969 APS_locLimitReason "APS_locLimitReason";
BA_ "LogSignal" SG_ 969 APS_locLimitReason "onChange";
BA_ "FieldType" SG_ 969 APS_appPowerStateRequest "APS_apPowerStateRequest";
BA_ "LogSignal" SG_ 969 APS_appPowerStateRequest "onChange";
BA_ "FieldType" SG_ 969 APS_appPowerStateReason "APS_apPowerStateReason";
BA_ "LogSignal" SG_ 969 APS_appPowerStateReason "onChange";
BA_ "FieldType" SG_ 969 APS_apbPowerStateRequest "APS_apPowerStateRequest";
BA_ "LogSignal" SG_ 969 APS_apbPowerStateRequest "onChange";
BA_ "FieldType" SG_ 969 APS_apbPowerStateReason "APS_apPowerStateReason";
BA_ "LogSignal" SG_ 969 APS_apbPowerStateReason "onChange";
BA_ "FieldType" SG_ 969 APS_heaterStateDebug "APS_heaterState";
BA_ "GenSigSNA" SG_ 969 APS_heaterStateDebug "7";
BA_ "GenSigSNA" SG_ 1115 APS_setSpeed "4095";
BA_ "GenSigSNA" SG_ 1115 APS_accState "15";
BA_ "GenSigSNA" SG_ 1115 APS_aebEvent "3";
BA_ "GenSigSNA" SG_ 1115 APS_jerkMin "511";
BA_ "GenSigSNA" SG_ 1115 APS_jerkMax "255";
BA_ "GenSigSNA" SG_ 1115 APS_accelMin "511";
BA_ "GenSigSNA" SG_ 1115 APS_accelMax "511";
BA_ "LogSignal" SG_ 971 APS_smartSummonActive "onChange";
BA_ "LogSignal" SG_ 971 APS_apcInternalState "onChange";
BA_ "LogSignal" SG_ 971 APS_heartBeatCheckActive "onChange";
BA_ "GenSigCycleTime" SG_ 267 FL_Lvl 100;
BA_ "GenSigCycleTimeActive" SG_ 267 FL_Lvl 100;
BA_ "GenSigSNA" SG_ 267 FL_Lvl "255";
BA_ "GenSigStartValue" SG_ 267 FL_Lvl 100;
BA_ "LogSignal" SG_ 267 FL_Lvl "periodic ONE_SECOND fastLogLevel,periodic TEN_MINUTES driveModeModelS";
BA_ "GenSigCycleTime" SG_ 267 FR_Lvl 100;
BA_ "GenSigCycleTimeActive" SG_ 267 FR_Lvl 100;
BA_ "GenSigSNA" SG_ 267 FR_Lvl "255";
BA_ "GenSigStartValue" SG_ 267 FR_Lvl 100;
BA_ "LogSignal" SG_ 267 FR_Lvl "periodic ONE_SECOND fastLogLevel,periodic TEN_MINUTES driveModeModelS";
BA_ "GenSigCycleTime" SG_ 267 RL_Lvl 100;
BA_ "GenSigCycleTimeActive" SG_ 267 RL_Lvl 100;
BA_ "GenSigSNA" SG_ 267 RL_Lvl "255";
BA_ "GenSigStartValue" SG_ 267 RL_Lvl 100;
BA_ "LogSignal" SG_ 267 RL_Lvl "periodic ONE_SECOND fastLogLevel,periodic TEN_MINUTES driveModeModelS";
BA_ "GenSigCycleTime" SG_ 267 RR_Lvl 100;
BA_ "GenSigCycleTimeActive" SG_ 267 RR_Lvl 100;
BA_ "GenSigSNA" SG_ 267 RR_Lvl "255";
BA_ "GenSigStartValue" SG_ 267 RR_Lvl 100;
BA_ "LogSignal" SG_ 267 RR_Lvl "periodic ONE_SECOND fastLogLevel,periodic TEN_MINUTES driveModeModelS";
BA_ "GenSigCycleTime" SG_ 267 FL_Lvl_Adj 100;
BA_ "GenSigCycleTimeActive" SG_ 267 FL_Lvl_Adj 100;
BA_ "GenSigCycleTime" SG_ 267 FR_Lvl_Adj 100;
BA_ "GenSigCycleTimeActive" SG_ 267 FR_Lvl_Adj 100;
BA_ "GenSigCycleTime" SG_ 267 RL_Lvl_Adj 100;
BA_ "GenSigCycleTimeActive" SG_ 267 RL_Lvl_Adj 100;
BA_ "GenSigCycleTime" SG_ 267 RR_Lvl_Adj 100;
BA_ "GenSigCycleTimeActive" SG_ 267 RR_Lvl_Adj 100;
BA_ "GenSigCycleTime" SG_ 267 HSenNC 100;
BA_ "GenSigCycleTimeActive" SG_ 267 HSenNC 100;
BA_ "GenSigCycleTime" SG_ 283 Wala_LC_red 100;
BA_ "GenSigCycleTimeActive" SG_ 283 Wala_LC_red 100;
BA_ "LogSignal" SG_ 283 Wala_LC_red "onChange";
BA_ "GenSigCycleTime" SG_ 283 Wala_LC_yel 100;
BA_ "GenSigCycleTimeActive" SG_ 283 Wala_LC_yel 100;
BA_ "LogSignal" SG_ 283 Wala_LC_yel "onChange";
BA_ "LogSignal" SG_ 283 EAS_extremeLowLevel "onChange";
BA_ "GenSigCycleTime" SG_ 283 CompRun 100;
BA_ "GenSigCycleTimeActive" SG_ 283 CompRun 100;
BA_ "GenSigCycleTime" SG_ 283 LC_LimpHomeMode 100;
BA_ "GenSigCycleTimeActive" SG_ 283 LC_LimpHomeMode 100;
BA_ "LogSignal" SG_ 283 LC_LimpHomeMode "onChange";
BA_ "GenSigCycleTime" SG_ 283 SysDisabled 100;
BA_ "GenSigCycleTimeActive" SG_ 283 SysDisabled 100;
BA_ "GenSigCycleTime" SG_ 283 TargetLevel 100;
BA_ "GenSigCycleTimeActive" SG_ 283 TargetLevel 100;
BA_ "LogSignal" SG_ 283 TargetLevel "onChange";
BA_ "GenSigCycleTime" SG_ 283 CurrentLevel 100;
BA_ "GenSigCycleTimeActive" SG_ 283 CurrentLevel 100;
BA_ "LogSignal" SG_ 283 CurrentLevel "onChange";
BA_ "FlexKomComment" SG_ 283 ASD_A2_Counter "Momentenanforderung ESP";
BA_ "FlexKomIsMotorola" SG_ 283 ASD_A2_Counter 1;
BA_ "FlexKomSID" SG_ 283 ASD_A2_Counter 33554835;
BA_ "FlexKomSigLaenge" SG_ 283 ASD_A2_Counter 40;
BA_ "FlexKomSigStartPos" SG_ 283 ASD_A2_Counter 15;
BA_ "FlexKomSigStartValue" SG_ 283 ASD_A2_Counter "8000001FFFh";
BA_ "GenSigCycleTime" SG_ 283 ASD_A2_Counter 10;
BA_ "LogSignal" SG_ 283 EAS_LowLevelLamp "onChange";
BA_ "LogSignal" SG_ 283 EAS_NormalLevelLamp "onChange";
BA_ "LogSignal" SG_ 283 EAS_HighLevelLamp "onChange";
BA_ "LogSignal" SG_ 283 EAS_JackModeLamp "onChange";
BA_ "LogSignal" SG_ 283 EAS_VeryHighLevelLamp "onChange";
BA_ "LogSignal" SG_ 283 EAS_LevelingNotPossible "onChange";
BA_ "LogSignal" SG_ 283 EAS_LevelingNotAllowed "onChange";
BA_ "GenSigCycleTime" SG_ 283 ASD_A2_Checksum 10;
BA_ "FieldType" SG_ 577 BCCEN_seeYouHomeLightingReq "lightingRequest";
BA_ "FieldType" SG_ 577 BCCEN_footwellLightsStatus "lightStatus";
BA_ "GenSigSNA" SG_ 577 BCCEN_footwellLightsStatus "3";
BA_ "FieldType" SG_ 577 BCCEN_ambientLightingRequest "lightingRequest";
BA_ "FieldType" SG_ 577 BCCEN_courtesyLightingRequest "lightingRequest";
BA_ "FieldType" SG_ 577 BCCEN_approachLightingRequest "lightingRequest";
BA_ "FieldType" SG_ 577 BCCEN_ambientLightsStatus "lightStatus";
BA_ "GenSigSNA" SG_ 577 BCCEN_ambientLightsStatus "3";
BA_ "FieldType" SG_ 577 BCCEN_switchLightingRequest "lightingRequest";
BA_ "FieldType" SG_ 577 BCCEN_hazardLightRequest "hazardLightRequest";
BA_ "LogSignal" SG_ 778 BDY_wiperState "onChange";
BA_ "GenSigStartValue" SG_ 778 BDY_flashMainSwitch 7;
BA_ "GenSigSNA" SG_ 778 BDY_rlsHumidity "255";
BA_ "GenSigStartValue" SG_ 778 BDY_rlsHumidity 255;
BA_ "GenSigSNA" SG_ 778 BDY_rlsWindowTemperature "255";
BA_ "GenSigStartValue" SG_ 778 BDY_rlsWindowTemperature 255;
VAL_ 1481 APS_alertID 233 "APS_w233_laneChangeCancelled" 232 "APS_w232_laneChangeRequested" 231 "APS_w231_idfEvent" 230 "APS_w230_alcUltrasoundBlocked" 229 "APS_w229_alcUltrasoundDamaged" 227 "APS_w227_virtualWallBlocked" 226 "APS_w226_lcCamCalNeededSpeedLmt" 225 "APS_w225_lcDegradedVisSpeedLmt" 224 "APS_w224_accCameraCalibration" 223 "APS_w223_accObjectInPath" 222 "APS_w222_accCameraBlind" 221 "APS_w221_accRadarBlind" 220 "APS_w220_lcTempUnavailableRoad" 219 "APS_w219_lcTempUnavailableSpeed" 218 "APS_w218_lcSpeedExceededLimit" 217 "APS_w217_lcUnavailableSpeeding" 216 "APS_w216_driverOverriding" 215 "APS_w215_contDriverNotIntracting" 214 "APS_w214_driverNotIntracting" 213 "APS_w213_autosteerStruckOut" 212 "APS_w212_lcUnavailableStrikeOut" 211 "APS_w211_accNoSeatBelt" 210 "APS_w210_camObstrcted" 209 "APS_w209_autoSummonRequest" 208 "APS_w208_rackDetected" 207 "APS_w207_autosteerUnavailable" 206 "APS_w206_autosteerNotEnabled" 205 "APS_w205_apcFinalRear" 204 "APS_w204_apcFinalFront" 203 "APS_w203_apcActivation" 202 "APS_w202_scwNoisyEnvironment" 201 "APS_w201_lcAborting" 200 "APS_w200_lcSlowdown" 199 "APS_w199_apcAbort" 198 "APS_w198_tsrUnavailable" 197 "APS_w197_redLightWarning" 196 "APS_w196_stopSignWarning" 195 "APS_w195_scwUnavailable" 194 "APS_w194_accDriverResumeRqrd" 193 "APS_w193_camWindshieldUnclean" 192 "APS_w192_CANFault" 189 "APS_w189_vcseatMIA" 188 "APS_w188_otherTurboUartMIA" 187 "APS_w187_TurboB_SMS_taskUtilErr" 186 "APS_w186_TurboB_A72_watchdog" 185 "APS_w185_TurboB_SCS_LKUP" 184 "APS_w184_TurboB_SMS_WDOG" 183 "APS_w183_TurboB_TMU_Throttle" 182 "APS_w166_TurboB_SMS_LockStepError" 181 "APS_w181_TurboB_Temp_NOS" 180 "APS_w180_TurboB_12VFuseFault" 179 "APS_w179_TurboB_DisRegNFault" 178 "APS_w178_TurboB_DisRegPgoodErr" 173 "APS_w173_unsupportedConfig" 172 "APS_w172_apFeaturesUnavailable" 171 "APS_w171_TurboA_SMS_taskUtilErr" 170 "APS_w170_TurboA_A72_watchdog" 169 "APS_w169_TurboA_SCS_LKUP" 168 "APS_w168_TurboA_SMS_WDOG" 167 "APS_w167_TurboA_TMU_Throttle" 166 "APS_w166_TurboA_SMSLockStepErr" 165 "APS_w165_TurboA_Temp_NOS" 164 "APS_w164_TurboA_12VFuseFault" 163 "APS_w163_TurboA_DisRegNFault" 162 "APS_w162_TurboA_DisRegPgoodErr" 161 "APS_w161_gpsAntennaDisconnected" 160 "APS_w160_apbVersionMismatch" 159 "APS_w159_apbCritical" 158 "APS_w158_apbMia" 157 "APS_w157_autopilotReboot" 156 "APS_w156_lwipAssert" 155 "APS_w155_ethLwipError" 154 "APS_w154_secEthPacketMIA" 153 "APS_w153_eacInhibit" 152 "APS_w152_gpsFusionStatus" 151 "APS_w151_apRecovered" 146 "APS_w146_epas3pMiaPartyBus" 139 "APS_w139_udpBufferOverflow" 138 "APS_w138_gpsComIssue" 137 "APS_w137_gpsFaultReset" 136 "APS_w136_gpsDisabled" 135 "APS_w135_appCritical" 134 "APS_w134_appMia" 133 "APS_w133_ETHSwitchError" 132 "APS_w132_appVersionMismatch" 131 "APS_w131_trap_exception" 130 "APS_w130_ECU_Thermal_Issue" 129 "APS_w129_ECU_Power_Issue" 106 "APS_w106_torsionBarCalibrated" 103 "APS_w103_robExperimentalAEB" 86 "APS_w086_robCollision" 85 "APS_w085_pmmSteering" 84 "APS_w084_pmmIPSO" 83 "APS_w083_inPathRADObject" 82 "APS_w082_inPathFSviolation" 81 "APS_w081_pmmActiveBraking" 80 "APS_w080_accFailedActivation" 79 "APS_w079_edrAvailable" 78 "APS_w078_pmmActive2" 77 "APS_w077_pmmActive" 76 "APS_w076_mobilEyeSetC" 75 "APS_w075_scMia" 74 "APS_w074_inPathStationaryObst" 73 "APS_w073_issueEscalatedLDW" 72 "APS_w072_selfparkComplete" 71 "APS_w071_selfparkStarted" 70 "APS_w070_apcIncompleteCal" 69 "APS_w069_apcSpaceMasked" 68 "APS_w068_vlInconsistency" 67 "APS_w067_steeringAlignment" 66 "APS_w066_deserializerLockLost" 65 "APS_w065_deserializerOvercurrent" 64 "APS_w064_epasMia" 63 "APS_w063_parkVersionMismatch" 62 "APS_w062_radcAlignment" 61 "APS_w061_airSuspensionMia" 60 "APS_w060_fcw_event" 59 "APS_w059_parkMia" 58 "APS_w058_epbMia" 57 "APS_w057_mcuMia" 56 "APS_w056_diMia" 55 "APS_w055_radcVersionMismatch" 54 "APS_w054_camAutofix" 53 "APS_w053_radcCommIssue" 52 "APS_w052_radcSensorIssue" 51 "APS_w051_radcEcuIssue" 50 "APS_w050_aeb_event" 49 "APS_w049_eyeqVersionMismatch" 48 "APS_w048_APS_Features_Disabled" 47 "APS_w047_edrEvent" 46 "APS_w046_eepromRecordAbsent" 45 "APS_w045_radMia" 44 "APS_w044_appMobileyeFailure" 43 "APS_w043_camLongRunTime" 42 "APS_w042_autopilotAborting" 41 "APS_w041_autopilotRateSaturated" 40 "APS_w040_autopilotAngleSaturated" 39 "APS_w039_sdm_rcm_Mia" 38 "APS_w038_camFailure" 37 "APS_w037_camTacIssue" 36 "APS_w036_bdyMia" 35 "APS_w035_espMia" 34 "APS_w034_sccmMia" 33 "APS_w033_gtwMia" 32 "APS_w032_canTxError" 31 "APS_w031_canRxError" 30 "APS_w030_Heater_Issue" 29 "APS_w029_spi_tx_error" 28 "APS_w028_spi_rx_error" 27 "APS_w027_ECU_Reset_Fault" 26 "APS_w026_ECU_timingIssue" 25 "APS_w025_LC_Steering_Override" 24 "APS_w024_ECU_Watchdog_Reset" 23 "APS_w023_ECU_Cam_Statemismatch" 22 "APS_w022_ECU_EEPROM_Failure" 21 "APS_w021_ECU_Temperature_Issue" 20 "APS_w020_ECU_checkstopError" 19 "APS_w019_ECU_Stack_Overflow" 18 "APS_w018_ECU_Power_Issue" 17 "APS_w017_Cam_Msg_MIA" 16 "APS_w016_aeb_e_event" 15 "APS_w015_Camera_Failsafes" 14 "APS_w014_swAssert" 13 "APS_w013_Cam_Watchdog" 12 "APS_w012_Cam_BootFailure" 11 "APS_w011_scaEvent" 10 "APS_w010_radcCalibIssue" 9 "APS_w009_aebFault" 8 "APS_w008_parkDisabled" 7 "APS_w007_ahlbDisabled" 6 "APS_w006_aebCancelled" 5 "APS_w005_fcwCancelled" 4 "APS_w004_accDisabled" 3 "APS_w003_isaDisabled" 2 "APS_w002_ldwDisabled" 0 "APS_w000_reserved" ;
VAL_ 1481 APS_alertSource 1 "TURBO_B" 0 "TURBO_A" ;
VAL_ 1481 APS_sw004_accState 11 "CANCEL_OUT_OF_CALIBRATION" 10 "CANCEL_GENERIC_SILENT" 9 "CANCEL_PATH_NOT_CLEAR" 8 "FAULT" 7 "CANCEL_RADAR" 6 "CANCEL_CAMERA" 5 "CANCEL_GENERIC" 4 "READY_FOR_RESUME" 3 "HOLD" 2 "STANDSTILL" 1 "ACTIVE" 0 "IDLE" ;
VAL_ 1481 APS_sw004_appMobileyeStatus 24 "MOBILEYE_STATUS_UNDEFINED" 23 "MOBILEYE_STATUS_TEARDOWN_FLASH_ACCESS_MODE" 22 "MOBILEYE_STATUS_FLASH_READ_MODE" 21 "MOBILEYE_STATUS_SETUP_FLASH_ACCESS_MODE" 20 "MOBILEYE_STATUS_RUNNING_SPTAC_MODE" 19 "MOBILEYE_STATUS_SPTAC_INIT_SENT" 18 "MOBILEYE_STATUS_WAITING_FOR_SPTAC_INIT" 17 "MOBILEYE_STATUS_BURN_EDR_MODE" 16 "MOBILEYE_STATUS_SPC_INIT_SENT" 15 "MOBILEYE_STATUS_WAITING_FOR_SPC_INIT" 14 "MOBILEYE_STATUS_ERROR" 13 "MOBILEYE_STATUS_LATCHING_FAILURE" 12 "MOBILEYE_STATUS_UPDATING" 11 "MOBILEYE_STATUS_RUNNING_DV_MODE" 10 "MOBILEYE_STATUS_WAITING_FOR_DV" 9 "MOBILEYE_STATUS_RUNNING_TAC_MODE" 8 "MOBILEYE_STATUS_RUNNING_SPC_MODE" 7 "MOBILEYE_STATUS_RUNNING_VISION_MODE" 6 "MOBILEYE_STATUS_TAC_INIT_SENT" 5 "MOBILEYE_STATUS_WAITING_FOR_TAC_INIT" 4 "MOBILEYE_STATUS_VISION_INIT_SENT" 3 "MOBILEYE_STATUS_WAITING_FOR_VISION_INIT" 2 "MOBILEYE_STATUS_WAITING_FOR_BOOT" 1 "MOBILEYE_STATUS_POWER_OFF" 0 "MOBILEYE_STATUS_POWER_CYCLE" ;
VAL_ 1481 APS_sw006_timeOfDay 2 "TIME_DUSK" 1 "TIME_NIGHT" 0 "TIME_DAY" ;
VAL_ 1481 APS_sw010_a04calibNotDone 1 "True" 0 "False" ;
VAL_ 1481 APS_sw010_a05calibReqd 1 "True" 0 "False" ;
VAL_ 1481 APS_sw010_a06calibNotOK 1 "True" 0 "False" ;
VAL_ 1481 APS_sw010_a08PlantMode 1 "True" 0 "False" ;
VAL_ 1481 APS_sw011_scaState 4 "FAULT" 3 "AVOIDANCE" 2 "AVAILABLE" 1 "UNAVAILABLE" 0 "DISABLED" ;
VAL_ 1481 APS_sw012_bootDDRTempStatus 3 "SDRAM high temperature" 2 "temperature grater than 85 C" 1 "temperature less or equal to 85 C" 0 "SDRAM low temperatue" ;
VAL_ 1481 APS_sw012_mespDDRTempStatus 7 "Temperature error" 3 "Temperature above 85" 2 "Termperature above spec" 1 "Temperature below spec" 0 "Temperature ok" ;
VAL_ 1481 APS_sw013_stateBeforeWatchdog 24 "MOBILEYE_STATUS_UNDEFINED" 23 "MOBILEYE_STATUS_TEARDOWN_FLASH_ACCESS_MODE" 22 "MOBILEYE_STATUS_FLASH_READ_MODE" 21 "MOBILEYE_STATUS_SETUP_FLASH_ACCESS_MODE" 20 "MOBILEYE_STATUS_RUNNING_SPTAC_MODE" 19 "MOBILEYE_STATUS_SPTAC_INIT_SENT" 18 "MOBILEYE_STATUS_WAITING_FOR_SPTAC_INIT" 17 "MOBILEYE_STATUS_BURN_EDR_MODE" 16 "MOBILEYE_STATUS_SPC_INIT_SENT" 15 "MOBILEYE_STATUS_WAITING_FOR_SPC_INIT" 14 "MOBILEYE_STATUS_ERROR" 13 "MOBILEYE_STATUS_LATCHING_FAILURE" 12 "MOBILEYE_STATUS_UPDATING" 11 "MOBILEYE_STATUS_RUNNING_DV_MODE" 10 "MOBILEYE_STATUS_WAITING_FOR_DV" 9 "MOBILEYE_STATUS_RUNNING_TAC_MODE" 8 "MOBILEYE_STATUS_RUNNING_SPC_MODE" 7 "MOBILEYE_STATUS_RUNNING_VISION_MODE" 6 "MOBILEYE_STATUS_TAC_INIT_SENT" 5 "MOBILEYE_STATUS_WAITING_FOR_TAC_INIT" 4 "MOBILEYE_STATUS_VISION_INIT_SENT" 3 "MOBILEYE_STATUS_WAITING_FOR_VISION_INIT" 2 "MOBILEYE_STATUS_WAITING_FOR_BOOT" 1 "MOBILEYE_STATUS_POWER_OFF" 0 "MOBILEYE_STATUS_POWER_CYCLE" ;
VAL_ 1481 APS_sw014_fileNameHash 32617 "HW_GPIO_PAD.c" 32602 "UDS_FlowControl.c" 32601 "ACC_compute.c" 32576 "app_CAN.c" 32563 "IO_RGM.c" 32315 "IQmath.c" 32314 "HW_CGM.c" 32299 "HW_RGM.c" 32074 "trajectory_planner_main.c" 32054 "HW_ADC.c" 32006 "NVM_Manager_component_specific.c" 31862 "IO_queue_component_specific.c" 31831 "fixquat.c" 31790 "IO_ADC.c" 31784 "UDS_TP.c" 31764 "lib_UDS_EEPROM.c" 31604 "HW_GPIO_pad_definitions.c" 31348 "app_mobileye_version_matrix.c" 31343 "HW_ECSM.c" 31291 "UDS_RC.c" 31247 "fixvector2d.c" 31246 "fixvector3d.c" 31032 "IO_radar_alert.c" 31009 "IO_CAN.c" 30055 "UDS_TRD.c" 29810 "app_tsr.c" 29797 "IO_watchdog.c" 29787 "SCA_monitor.c" 29561 "UDS_ctrlDTC.c" 29531 "IO_Mobileye.c" 29280 "AlertManagerCfg.c" 29243 "Interpolate_IQ15.c" 29033 "app_ahb.c" 29024 "UDS_readDTC.c" 28726 "HW_LIN.c" 28722 "HW_SIU.c" 28720 "HW_PIT.c" 28519 "IO_PWMInput.c" 28465 "IO_PWM.c" 28459 "IO_SWT.c" 28211 "HW_SWT.c" 28197 "HW_APS_SIU.c" 27947 "HW_OTP.c" 27946 "HW_STM.c" 27914 "util_queue.c" 27750 "IO_mutex_component_specific.c" 27699 "IO_OTP.c" 27516 "IO_CAN_data.c" 27451 "UDS_CC.c" 27444 "HW_CRC.c" 27262 "HW_WKPU.c" 27233 "app_vehicle.c" 27179 "HW_MSR.c" 26995 "xcp_par.c" 26981 "app_ldw.c" 26926 "HW_SPI.c" 26232 "ACC_speed_limit.c" 25952 "das_app.c" 25866 "RTOS_interrupt.c" 25713 "ACC_fleet_speed.c" 25691 "ACC_monitor.c" 25190 "UDS_DSC.c" 25164 "road_furniture_main.c" 25154 "app_ECU.c" 24957 "CSA.c" 24907 "lib_HSD.c" 24678 "IO_UART.c" 24636 "HW_RGM_APS.c" 24145 "fix16_exp.c" 23589 "app_mobileye_country_codes.c" 22573 "utils_math.c" 22548 "IO_Vehicle.c" 22364 "util_codeDescriptor_ghs.c" 22082 "NVM_Manager.c" 21614 "LC_calculate_health.c" 21599 "watchdog_manager_component_specific.c" 21295 "app_heater.c" 21266 "IO_Environment.c" 21063 "lib_mobileye_mesp_utils.c" 20331 "util_ringBuffer.c" 20237 "UDS_SecurityAccess.c" 19731 "LC_follow_path.c" 19318 "fix16.c" 19037 "fix16_str.c" 18253 "Interpolate.c" 17980 "HW_interrupt_componentSpecific.c" 17972 "UDS_SendSM.c" 17933 "IO_quadDecoder.c" 17433 "util_crc_j1850.c" 17419 "UDS_RQ_ULDL_common.c" 17259 "util_codeDescriptor.c" 17168 "ACC_filter.c" 17016 "lib_mobileye_mesp_basic_service.c" 16910 "ACC_output.c" 16194 "UDS_SIDs.c" 16151 "IO_ECU_component_specific.c" 15973 "UDS_RQDL.c" 15965 "app_mobileye_EDR.c" 15928 "UDS_Processor.c" 15733 "UDS_WDBI.c" 15732 "UDS_WMBA.c" 15721 "profiler.c" 15678 "task_mobileye.c" 15616 "lib_mobileye_mesp.c" 15378 "HW_CAN_component_specific.c" 15375 "lib_NVRAM.c" 15211 "HW_EMIOS.c" 15197 "app_mobileye_TAC.c" 15181 "app_watchdog.c" 15121 "lib_mobileye_mesp_calibration_service.c" 14931 "lib_mobileye.c" 14684 "lib_math.c" 14453 "UDS_RDBI.c" 14452 "UDS_RMBA.c" 14448 "SCA_main.c" 14446 "UDS_ECUReset.c" 14425 "IO_reset.c" 14206 "PMM_main.c" 14185 "rijndael.c" 14180 "task_CAN.c" 14118 "util_counters.c" 13912 "utils_APS_assert.c" 13572 "virtual_wall_main.c" 13383 "IO_timer.c" 13130 "app_vehicle_driving_side.c" 12911 "task_UDS.c" 12645 "IO_Failsafes.c" 12596 "HW_ME.c" 12339 "LC_hands_on_detection.c" 12133 "UDS_RQUL.c" 12091 "IO_EEPROM.c" 11884 "UDS_RQTE.c" 11877 "world_model_main.c" 11811 "HW_EEPROM.c" 11615 "lib_mobileye_mesp_frame_data_service.c" 11568 "RTOS_time.c" 11525 "HW_SPI_component_specific.c" 11277 "virtual_lane_main.c" 11132 "CalcFilt.c" 11089 "lateral_control_angle_tables.c" 10860 "main.c" 10840 "LC_telemetry.c" 10530 "ACC_target_assessment.c" 10524 "app_system_health.c" 10352 "ACC_main.c" 10339 "APC_main.c" 10317 "IO_mutex.c" 10007 "IO_digOut.c" 10004 "lib_mobileye_mesp_edr_service.c" 9784 "UDS_IOCBI.c" 9750 "HW_LIN_processor_specific.c" 9729 "IO_board_test.c" 9546 "app_mobileye.c" 9257 "FCM_threat_assessment.c" 9082 "lib_mobileye_mesp_camera_service.c" 9056 "fixarray.c" 8801 "UDS_ECU_shim.c" 8716 "fract32.c" 8560 "FCM_main.c" 8537 "IO_MobileyeFlash.c" 8493 "UDS_ECU_Hooks.c" 8310 "util_bitManipulation.c" 8286 "IO_MobileyeFlashTestStub.c" 8274 "UDS_MasterSM.c" 8000 "AlertMap.c" 7969 "fixkalman.c" 7477 "TSR_telemetry.c" 7434 "FCM_state_machine.c" 7252 "HW_CAN_processorSpecific.c" 7223 "_xcp_appl.c" 7025 "fix16_trig.c" 6987 "AlertManager.c" 6941 "utils_ttc.c" 6209 "IO_digIn.c" 5924 "tasks.c" 5745 "task_vehicle.c" 5687 "fixmatrix.c" 5677 "IO_Heater.c" 5479 "UDS_ECU_Services.c" 5392 "UDS_ReceiveSM.c" 5158 "LC_health_monitor.c" 5145 "APC_state_machine.c" 5130 "ACC_state_machine.c" 4970 "Selfpark.c" 4950 "AlertManagerHeaderConfig.c" 4656 "SCA_angle.c" 4212 "watchdog_manager.c" 3931 "lib_IQ28QorivvaMathLib.c" 3666 "XcpBasic.c" 3145 "util_CRC32.c" 3113 "ACC_input.c" 2934 "ACC_target_selection.c" 2878 "HW_I2C.c" 2640 "app_mobileye_spi.c" 2632 "IO_ADC_componentSpecific.c" 2598 "IO_I2C.c" 2162 "UDS_clearDTC.c" 1889 "fix16_sqrt.c" 1612 "uint32.c" 1564 "IO_CAN_alerts.c" 1365 "LC_state_machine.c" 1151 "IO_EEPROM_component_specific.c" 1034 "SCA_state_machine.c" 605 "HW_EEPROM_common.c" 297 "CanReceiver_Generated.c" 48 "IO_edgeDetect.c" ;
VAL_ 1481 APS_sw015_RadarLowVisibility 3 "True_High_Severity" 2 "True_Medium_Severity" 1 "True_Low_Severity" 0 "False" ;
VAL_ 1481 APS_sw015_RadarMisalignment 3 "True_High_Severity" 2 "True_Medium_Severity" 1 "True_Low_Severity" 0 "False" ;
VAL_ 1481 APS_sw015_LowSun 3 "True_High_Severity" 2 "True_Medium_Severity" 1 "True_Low_Severity" 0 "False" ;
VAL_ 1481 APS_sw015_BlurredImage 3 "True_High_Severity" 2 "True_Medium_Severity" 1 "True_Low_Severity" 0 "False" ;
VAL_ 1481 APS_sw015_FullBlockage 3 "True_High_Severity" 2 "True_Medium_Severity" 1 "True_Low_Severity" 0 "False" ;
VAL_ 1481 APS_sw015_PartialBlockage 3 "True_High_Severity" 2 "True_Medium_Severity" 1 "True_Low_Severity" 0 "False" ;
VAL_ 1481 APS_sw015_AutofixOutOfCalib 3 "True_High_Severity" 2 "True_Medium_Severity" 1 "True_Low_Severity" 0 "False" ;
VAL_ 1481 APS_sw015_AutofixOutOfCalibYaw 3 "True_High_Severity" 2 "True_Medium_Severity" 1 "True_Low_Severity" 0 "False" ;
VAL_ 1481 APS_sw015_AutofixOOfCalibHorizon 3 "True_High_Severity" 2 "True_Medium_Severity" 1 "True_Low_Severity" 0 "False" ;
VAL_ 1481 APS_sw015_Splashes 3 "True_High_Severity" 2 "True_Medium_Severity" 1 "True_Low_Severity" 0 "False" ;
VAL_ 1481 APS_sw015_SmearedSpots 3 "True_High_Severity" 2 "True_Medium_Severity" 1 "True_Low_Severity" 0 "False" ;
VAL_ 1481 APS_sw015_SmearedHalos 3 "True_High_Severity" 2 "True_Medium_Severity" 1 "True_Low_Severity" 0 "False" ;
VAL_ 1481 APS_sw015_FoggyLights 3 "True_High_Severity" 2 "True_Medium_Severity" 1 "True_Low_Severity" 0 "False" ;
VAL_ 1481 APS_sw015_SunRay 3 "True_High_Severity" 2 "True_Medium_Severity" 1 "True_Low_Severity" 0 "False" ;
VAL_ 1481 APS_sw015_ImpairedVD 3 "True_High_Severity" 2 "True_Medium_Severity" 1 "True_Low_Severity" 0 "False" ;
VAL_ 1481 APS_sw015_SelfGlare 3 "True_High_Severity" 2 "True_Medium_Severity" 1 "True_Low_Severity" 0 "False" ;
VAL_ 1481 APS_sw015_OutOfFocusImage 3 "True_High_Severity" 2 "True_Medium_Severity" 1 "True_Low_Severity" 0 "False" ;
VAL_ 1481 APS_sw017_Camera_Msg_Lanes_MIA 1 "True" 0 "False" ;
VAL_ 1481 APS_sw017_Camera_Msg_Objects_MIA 1 "True" 0 "False" ;
VAL_ 1481 APS_sw017_Camera_Msg_Tsr_MIA 1 "True" 0 "False" ;
VAL_ 1481 APS_sw017_Camera_Msg_Hlb_MIA 1 "True" 0 "False" ;
VAL_ 1481 APS_sw017_Camera_Msg_Common_MIA 1 "True" 0 "False" ;
VAL_ 1481 APS_sw017_Camera_Msg_FCW_PCW_MIA 1 "True" 0 "False" ;
VAL_ 1481 APS_sw017_Camera_Msg_TFL_MIA 1 "True" 0 "False" ;
VAL_ 1481 APS_sw017_Any_Lanes_Msg_Recd 1 "True" 0 "False" ;
VAL_ 1481 APS_sw017_Any_Objects_Msg_Recd 1 "True" 0 "False" ;
VAL_ 1481 APS_sw017_Any_TFL_Msg_Recd 1 "True" 0 "False" ;
VAL_ 1481 APS_sw017_Any_Tsr_Msg_Recd 1 "True" 0 "False" ;
VAL_ 1481 APS_sw017_Any_Hlb_Msg_Recd 1 "True" 0 "False" ;
VAL_ 1481 APS_sw017_Any_Common_Msg_Recd 1 "True" 0 "False" ;
VAL_ 1481 APS_sw017_Any_FCW_PCW_Msg_Recd 1 "True" 0 "False" ;
VAL_ 1481 APS_sw018_railID 3 "1v2_rail" 2 "1v8_rail" 1 "3v3_rail" 0 "5v0_rail" ;
VAL_ 1481 APS_sw018_powerSequnceError 1 "True" 0 "False" ;
VAL_ 1481 APS_sw018_railControl 1 "RAIL_ENABLED" 0 "RAIL_DISABLED" ;
VAL_ 1481 APS_sw019_taskId 32 "MAX_TASK_ID" 31 "TASKS_ISOTERM_A72" 30 "TASKS_ISOTERM_SMS" 29 "TASKS_APP_1HZ" 28 "TASKS_APP_1KHZ" 27 "TASKS_SMS_SERIAL" 26 "TASKS_CAN_AP_RX" 25 "TASKS_CAN_AP_TX" 24 "TASKS_TMU" 23 "TASKS_WDG_TASK" 22 "TASKS_MBX_RELAY" 21 "TASKS_MBX_SCS_RX_HIGH" 20 "TASKS_MBX_SCS_RX_LOW" 19 "TASKS_MBX_SCS_TX_HIGH" 18 "TASKS_MBX_SCS_TX_LOW" 17 "TASKS_MBX_AP_RX_HIGH" 16 "TASKS_MBX_AP_RX_LOW" 15 "TASKS_MBX_AP_TX_HIGH" 14 "TASKS_MBX_AP_TX_LOW" 13 "TASKS_VEH_CAN" 12 "TASKS_RADAR_CAN" 11 "TASKS_CH_CAN" 10 "TASKS_PARTY_CAN" 9 "TASK_DEBUG_SMS_SERIAL_RX" 8 "TASK_DEBUG_SERIAL_TX" 7 "TASKS_SMS_SMS_UART_RX" 6 "TASKS_SMS_SMS_UART_TX" 5 "TASKS_VEHICLE" 4 "TASKS_MOBILEYE" 3 "TASKS_UDS" 2 "TASKS_CAN" 1 "TASKS_INIT" 0 "TASKS_RESERVED" ;
VAL_ 1481 APS_sw021_tempSensorId 4 "DDR_TEMP_SENSOR" 3 "CAMERA_TEMP_SENSOR" 2 "EYE_Q_TEMP_SENSOR_1" 1 "EYE_Q_TEMP_SENSOR_0" 0 "EXTERNAL_TEMP_SENSOR" ;
VAL_ 1481 APS_sw022_operation 4 "Erase All" 3 "Delete" 2 "Read" 1 "Write" 0 "Initialize" ;
VAL_ 1481 APS_sw024_currentVehicleApp 162 "APS_VA_LOC_MONITOR" 161 "APS_VA_EAC_MONITOR" 160 "APS_VA_VL_PROFILER" 159 "APS_VA_VL_GM_VEH_EXIT" 158 "APS_VA_VL_GM_MISC_END_VEH_ID5" 157 "APS_VA_VL_GM_MISC_END_VEH_ID4" 156 "APS_VA_VL_GM_MISC_END_VEH_ID3" 155 "APS_VA_VL_GM_MISC_END_VEH_ID2" 154 "APS_VA_VL_GM_MISC_END_VEH_ID1" 153 "APS_VA_VL_GM_MISC_END_VEH_ID0" 152 "APS_VA_VL_GM_HEADING_VEH_ID5" 151 "APS_VA_VL_GM_HEADING_VEH_ID4" 150 "APS_VA_VL_GM_HEADING_VEH_ID3" 149 "APS_VA_VL_GM_HEADING_VEH_ID2" 148 "APS_VA_VL_GM_HEADING_VEH_ID1" 147 "APS_VA_VL_GM_HEADING_VEH_ID0" 146 "APS_VA_VL_GM_NODP_LONG_VEH_ID5" 145 "APS_VA_VL_GM_NODP_LONG_VEH_ID4" 144 "APS_VA_VL_GM_NODP_LONG_VEH_ID3" 143 "APS_VA_VL_GM_NODP_LONG_VEH_ID2" 142 "APS_VA_VL_GM_NODP_LONG_VEH_ID1" 141 "APS_VA_VL_GM_NODP_LONG_VEH_ID0" 140 "APS_VA_VL_GM_NODP_LAT_VEH_ID5" 139 "APS_VA_VL_GM_NODP_LAT_VEH_ID4" 138 "APS_VA_VL_GM_NODP_LAT_VEH_ID3" 137 "APS_VA_VL_GM_NODP_LAT_VEH_ID2" 136 "APS_VA_VL_GM_NODP_LAT_VEH_ID1" 135 "APS_VA_VL_GM_NODP_LAT_VEH_ID0" 134 "APS_VA_VL_GM_NODP_FUSE_VEH_ID5" 133 "APS_VA_VL_GM_NODP_FUSE_VEH_ID4" 132 "APS_VA_VL_GM_NODP_FUSE_VEH_ID3" 131 "APS_VA_VL_GM_NODP_FUSE_VEH_ID2" 130 "APS_VA_VL_GM_NODP_FUSE_VEH_ID1" 129 "APS_VA_VL_GM_NODP_FUSE_VEH_ID0" 128 "APS_VA_VL_GM_DP_FUSE_VEH_ID5" 127 "APS_VA_VL_GM_DP_FUSE_VEH_ID4" 126 "APS_VA_VL_GM_DP_FUSE_VEH_ID3" 125 "APS_VA_VL_GM_DP_FUSE_VEH_ID2" 124 "APS_VA_VL_GM_DP_FUSE_VEH_ID1" 123 "APS_VA_VL_GM_DP_FUSE_VEH_ID0" 122 "APS_VA_VL_GM_DP_OLD_VEH_ID5" 121 "APS_VA_VL_GM_DP_OLD_VEH_ID4" 120 "APS_VA_VL_GM_DP_OLD_VEH_ID3" 119 "APS_VA_VL_GM_DP_OLD_VEH_ID2" 118 "APS_VA_VL_GM_DP_OLD_VEH_ID1" 117 "APS_VA_VL_GM_DP_OLD_VEH_ID0" 116 "APS_VA_VL_GM_DP_NEW_VEH_ID5" 115 "APS_VA_VL_GM_DP_NEW_VEH_ID4" 114 "APS_VA_VL_GM_DP_NEW_VEH_ID3" 113 "APS_VA_VL_GM_DP_NEW_VEH_ID2" 112 "APS_VA_VL_GM_DP_NEW_VEH_ID1" 111 "APS_VA_VL_GM_DP_NEW_VEH_ID0" 110 "APS_VA_VL_GM_DP_PRECHK_VEH_ID5" 109 "APS_VA_VL_GM_DP_PRECHK_VEH_ID4" 108 "APS_VA_VL_GM_DP_PRECHK_VEH_ID3" 107 "APS_VA_VL_GM_DP_PRECHK_VEH_ID2" 106 "APS_VA_VL_GM_DP_PRECHK_VEH_ID1" 105 "APS_VA_VL_GM_DP_PRECHK_VEH_ID0" 104 "APS_VA_VL_GM_INV_COV_VEH_ID5" 103 "APS_VA_VL_GM_INV_COV_VEH_ID4" 102 "APS_VA_VL_GM_INV_COV_VEH_ID3" 101 "APS_VA_VL_GM_INV_COV_VEH_ID2" 100 "APS_VA_VL_GM_INV_COV_VEH_ID1" 99 "APS_VA_VL_GM_INV_COV_VEH_ID0" 98 "APS_VA_VL_GM_OBS_XFM_VEH_ID5" 97 "APS_VA_VL_GM_OBS_XFM_VEH_ID4" 96 "APS_VA_VL_GM_OBS_XFM_VEH_ID3" 95 "APS_VA_VL_GM_OBS_XFM_VEH_ID2" 94 "APS_VA_VL_GM_OBS_XFM_VEH_ID1" 93 "APS_VA_VL_GM_OBS_XFM_VEH_ID0" 92 "APS_VA_VL_GM_COV_VEH_ID5" 91 "APS_VA_VL_GM_COV_VEH_ID4" 90 "APS_VA_VL_GM_COV_VEH_ID3" 89 "APS_VA_VL_GM_COV_VEH_ID2" 88 "APS_VA_VL_GM_COV_VEH_ID1" 87 "APS_VA_VL_GM_COV_VEH_ID0" 86 "APS_VA_VL_GM_CHK_LANE_VEH_ID5" 85 "APS_VA_VL_GM_CHK_LANE_VEH_ID4" 84 "APS_VA_VL_GM_CHK_LANE_VEH_ID3" 83 "APS_VA_VL_GM_CHK_LANE_VEH_ID2" 82 "APS_VA_VL_GM_CHK_LANE_VEH_ID1" 81 "APS_VA_VL_GM_CHK_LANE_VEH_ID0" 80 "APS_VA_VL_GM_CHK_ID_VEH_ID5" 79 "APS_VA_VL_GM_CHK_ID_VEH_ID4" 78 "APS_VA_VL_GM_CHK_ID_VEH_ID3" 77 "APS_VA_VL_GM_CHK_ID_VEH_ID2" 76 "APS_VA_VL_GM_CHK_ID_VEH_ID1" 75 "APS_VA_VL_GM_CHK_ID_VEH_ID0" 74 "APS_VA_ROB" 73 "APS_VA_VL_GM_EVAL_SAVE" 72 "APS_VA_VL_GM_EVAL_NEW_VEH_5" 71 "APS_VA_VL_GM_EVAL_NEW_VEH_4" 70 "APS_VA_VL_GM_EVAL_NEW_VEH_3" 69 "APS_VA_VL_GM_EVAL_NEW_VEH_2" 68 "APS_VA_VL_GM_EVAL_NEW_VEH_1" 67 "APS_VA_VL_GM_EVAL_NEW_VEH_0" 66 "APS_VA_VL_GM_EVAL_VEH_5" 65 "APS_VA_VL_GM_EVAL_VEH_4" 64 "APS_VA_VL_GM_EVAL_VEH_3" 63 "APS_VA_VL_GM_EVAL_VEH_2" 62 "APS_VA_VL_GM_EVAL_VEH_1" 61 "APS_VA_VL_GM_EVAL_VEH_0" 60 "APS_VA_VL_GM_EVAL_NAV" 59 "APS_VA_VL_GM_EVAL_HPP" 58 "APS_VA_VL_GM_EVAL_RL" 57 "APS_VA_VL_GM_EVAL_LL" 56 "APS_VA_VL_GM_EVAL_MODEL" 55 "APS_VA_VL_GM_EVAL_SETUP" 54 "APS_VA_VL_GM_EVAL" 53 "APS_VA_VL_GM_VEH_ID5" 52 "APS_VA_VL_GM_VEH_ID4" 51 "APS_VA_VL_GM_VEH_ID3" 50 "APS_VA_VL_GM_VEH_ID2" 49 "APS_VA_VL_GM_VEH_ID1" 48 "APS_VA_VL_GM_VEH_ID0" 47 "APS_VA_VL_GM_VEH_2" 46 "APS_VA_VL_GM_NAV_2" 45 "APS_VA_VL_GM_FS_2" 44 "APS_VA_VL_GM_HPP_2" 43 "APS_VA_VL_GM_LANE_2" 42 "APS_VA_VL_GM_NAV_1" 41 "APS_VA_VL_GM_VEH_1" 40 "APS_VA_VL_GM_FS_1" 39 "APS_VA_VL_GM_HPP_1" 38 "APS_VA_VL_GM_LANE_1" 37 "APS_VA_VL_GM_SETUP" 36 "APS_VA_VL_UU" 35 "APS_VA_VL_CDH" 34 "APS_VA_VL_MP" 33 "APS_VA_VL_ETC" 32 "APS_VA_VL_GM" 31 "APS_VA_VL_CMC" 30 "APS_VA_VL_CFELC" 29 "APS_VA_VL_UELP" 28 "APS_VA_VL_CCM" 27 "APS_VA_VL_CDE" 26 "APS_VA_VL_SM" 25 "APS_VA_VL_UFC" 24 "APS_VA_VL_FM" 23 "APS_VA_VL_UNO" 22 "APS_VA_VL_ULWE" 21 "APS_VA_VL_CFKO" 20 "APS_VA_VL_RLV" 19 "APS_VA_VL_SO" 18 "APS_VA_ROAD_FURNITURE" 17 "APS_VA_VIRTUAL_WALL" 16 "APS_VA_VIRTUAL_LANE" 15 "APS_VA_WORLD_MODEL" 14 "APS_VA_TRAJECTORY_PLANNER" 13 "APS_VA_CSA" 12 "APS_VA_TSR" 11 "APS_VA_LDW" 10 "APS_VA_ACC" 9 "APS_VA_FCM" 8 "APS_VA_LC" 7 "APS_VA_BSD" 6 "APS_VA_AHB" 5 "APS_VA_SCA" 4 "APS_VA_APC" 3 "APS_VA_PMM" 2 "APS_VA_VEHICLE" 1 "APS_VA_INIT" 0 "APS_VA_NONE" ;
VAL_ 1481 APS_sw025_state_before_override 14 "LC_INTERNAL_STATE_NUM_STATES" 13 "LC_INTERNAL_STATE_FULL_ABORTED" 12 "LC_INTERNAL_STATE_FULL_ABORTING" 11 "LC_INTERNAL_STATE_AUTOSTEER_ABORTED" 10 "LC_INTERNAL_STATE_AUTOSTEER_ABORTING" 9 "LC_INTERNAL_STATE_AUTOSTEER_CANCELING" 8 "LC_INTERNAL_STATE_AUTOSTEER_ACTIVE" 7 "LC_INTERNAL_STATE_AUTOSTEER_PREACTIVE" 6 "LC_INTERNAL_STATE_ACC_ACTIVE_AUTOSTEER_AVAILABLE" 5 "LC_INTERNAL_STATE_ACC_ACTIVE_AUTOSTEER_UNAVAILABLE" 4 "LC_INTERNAL_STATE_AUTOSTEER_AVAILABLE" 3 "LC_INTERNAL_STATE_ACC_AVAIALABLE" 2 "LC_INTERNAL_STATE_UNAVAILABLE" 1 "LC_INTERNAL_STATE_DISABLED" 0 "LC_INTERNAL_STATE_FAULT" ;
VAL_ 1481 APS_sw025_leftLaneUsage 3 "BLACKLISTED" 2 "FUSED" 1 "AVAILABLE" 0 "REJECTED_UNAVAILABLE" ;
VAL_ 1481 APS_sw025_rightLaneUsage 3 "BLACKLISTED" 2 "FUSED" 1 "AVAILABLE" 0 "REJECTED_UNAVAILABLE" ;
VAL_ 1481 APS_sw025_vehiclesUsage 3 "BLACKLISTED" 2 "FUSED" 1 "AVAILABLE" 0 "REJECTED_UNAVAILABLE" ;
VAL_ 1481 APS_sw025_hppUsage 3 "BLACKLISTED" 2 "FUSED" 1 "AVAILABLE" 0 "REJECTED_UNAVAILABLE" ;
VAL_ 1481 APS_sw025_navigationUsage 3 "BLACKLISTED" 2 "FUSED" 1 "AVAILABLE" 0 "REJECTED_UNAVAILABLE" ;
VAL_ 1481 APS_sw025_modelUsage 3 "BLACKLISTED" 2 "FUSED" 1 "AVAILABLE" 0 "REJECTED_UNAVAILABLE" ;
VAL_ 1481 APS_sw025_bottsDotsUsage 3 "BLACKLISTED" 2 "FUSED" 1 "AVAILABLE" 0 "REJECTED_UNAVAILABLE" ;
VAL_ 1481 APS_sw025_offsetSide 3 "OFFSET_BOTH_OBJECTS" 2 "OFFSET_LEFT_OBJECT" 1 "OFFSET_RIGHT_OBJECT" 0 "NO_OFFSET" ;
VAL_ 1481 APS_sw026_task_id 3 "Vehicle" 2 "Mobileye" 1 "UDS" 0 "CAN" ;
VAL_ 1481 APS_sw030_heaterState 3 "UNAVAILABLE" 2 "SHORT" 1 "OPEN" 0 "NORMAL" ;
VAL_ 1481 APS_sw031_canBus 7 "Unknown" 3 "PT" 2 "PARTY" 1 "RAD0" 0 "CH" ;
VAL_ 1481 APS_sw031_errorType 8 "Generic" 7 "CAN Bus" 6 "Mailbox" 5 "Overrun" 4 "Invalid Data" 3 "Sequence" 2 "Checksum" 1 "Length" 0 "None" ;
VAL_ 1481 APS_sw032_canBus 7 "Unknown" 3 "PT" 2 "PARTY" 1 "RAD0" 0 "CH" ;
VAL_ 1481 APS_sw032_errorType 2 "Generic" 1 "Overrun" 0 "None" ;
VAL_ 1481 APS_sw033_gtwMia 128 "CH_BC_status_MIA" 7 "CH_GTW_carConfig2_MIA" 6 "CH_VIP_405HS_MIA" 5 "CH_GTW_time_MIA" 4 "CH_GTW_status_MIA" 3 "CH_GTW_odo_MIA" 2 "CH_GTW_chNm_MIA" 1 "CH_GTW_carConfig_MIA" 0 "Nominal" ;
VAL_ 1481 APS_sw034_sccmMia 2 "CH_STW_ANGLHP_STAT_MIA" 1 "CH_STW_ACTN_RQ_MIA" 0 "Nominal" ;
VAL_ 1481 APS_sw035_espMia 9 "ESP_B_MIA" 8 "ESP_wheelSpeeds_MIA" 7 "ESP_115h_MIA" 6 "DISCONTINUED_ESP_E_MIA" 5 "ESP_C_MIA" 4 "DISCONTINUED_ESP_A_MIA" 3 "ESP_145h_MIA" 2 "ESP_135h_MIA" 1 "ESP_125h_MIA" 0 "Nominal" ;
VAL_ 1481 APS_sw036_bdyMia 130 "CH_BCS2C_restraintStatus_MIA" 129 "CH_BCS2L_restraintStatus_MIA" 128 "CH_BCS2R_restraintStatus_MIA" 1 "BDY_status_MIA" 0 "Nominal" ;
VAL_ 1481 APS_sw037_issue 1 "Invalid parameters" 0 "Failed to read" ;
VAL_ 1481 APS_sw038_RadarMisalignment 1 "True" 0 "False" ;
VAL_ 1481 APS_sw038_OutOfFocusImage 1 "True" 0 "False" ;
VAL_ 1481 APS_sw038_AutofixOutOfCalib 1 "True" 0 "False" ;
VAL_ 1481 APS_sw038_AutofixOutOfCalibHorzn 1 "True" 0 "False" ;
VAL_ 1481 APS_sw038_AutofixOutOfCalibYaw 1 "True" 0 "False" ;
VAL_ 1481 APS_sw038_FullBlockage 1 "True" 0 "False" ;
VAL_ 1481 APS_sw039_sdm_rcm_Mia 128 "CH_RCM_STATUS_MIA" 1 "CH_SDM1_MIA" 0 "Nominal" ;
VAL_ 1481 APS_sw042_health_state 7 "AP_HEALTH_SNA" 6 "AP_HEALTH_UNUSED" 5 "AP_HEALTH_FAULT" 4 "AP_HEALTH_ABORTING" 3 "AP_HEALTH_SEVERELY_DEGRADED" 2 "AP_HEALTH_DEGRADED" 1 "AP_HEALTH_NOMINAL" 0 "AP_HEALTH_UNAVAILABLE" ;
VAL_ 1481 APS_sw042_abort_reason 27 "LC_ABORT_USER_OVERRIDE_STRIKEOUT" 26 "LC_ABORT_SEATBELT_UNBUCKLED" 25 "LC_ABORT_AEB" 24 "LC_ABORT_DRIVE_ON_MAPS" 23 "LC_ABORT_ECU_THERMAL_ISSUE" 22 "LC_ABORT_CRUISE_WENT_UNAVAILABLE" 21 "RR_ABORT_CONTROL_NOT_ALLOWED" 20 "RR_ABORT_CONTROLLER_HEALTH" 19 "RR_ABORT_WATCHDOG_HEALTH_CRITICAL" 18 "LC_ABORT_APP_ME_STATE" 17 "LC_ABORT_ME_MAIN_STATE" 16 "LC_ABORT_CAMERA_MSG_MIA" 15 "LC_ABORT_CAMERA_WATCHDOG" 14 "LC_ABORT_TRAILER_MODE_ACTIVATION" 13 "LC_ABORT_SIDE_COLLISION_IMMINENT" 12 "LC_ABORT_ACC_CANCEL" 11 "LC_ABORT_CAMERA_FAILSAFES" 10 "LC_ABORT_EPAS_ERROR_CODE" 9 "LC_ABORT_PLANNER_OUTPUT_INVALID" 8 "LC_ABORT_FOLLOWER_OUTPUT_INVALID" 7 "LC_ABORT_VEHICLE_SPEED_ABOVE_MAX" 6 "LC_ABORT_HEALTH_MONITOR" 5 "LC_ABORT_DRIVING_OFF_NAV" 4 "LC_ABORT_CID_SWITCH_DISABLED" 3 "LC_ABORT_CRUISE_FAULT" 2 "LC_ABORT_COMPONENT_MIA" 1 "LC_ABORT_EPAS_EAC_DENIED" 0 "LC_ABORT_NONE" ;
VAL_ 1481 APS_sw042_state_before_abort 15 "LC_INTERNAL_STATE_PRECANCEL" 14 "LC_INTERNAL_STATE_DRIVER_STEERING_OVERRIDE" 13 "LC_INTERNAL_STATE_PREABORTED" 12 "LC_INTERNAL_STATE_FAULT" 11 "LC_INTERNAL_STATE_ABORTED" 10 "LC_INTERNAL_STATE_ABORTING" 9 "LC_INTERNAL_STATE_CHECK_ACTIVATION_WHILE_UNAVAILABLE" 8 "LC_INTERNAL_STATE_CHECK_ACTIVATION_WHILE_DISABLED" 7 "LC_INTERNAL_STATE_ACTIVE_RESTRICTED" 6 "LC_INTERNAL_STATE_ACTIVE_NOMINAL" 5 "LC_INTERNAL_STATE_PREACTIVATION" 4 "LC_INTERNAL_STATE_CHECK_FOR_ACTIVATION" 3 "LC_INTERNAL_STATE_AVAILABLE" 2 "LC_INTERNAL_STATE_UNAVAILABLE" 1 "LC_INTERNAL_STATE_DISABLED" 0 "LC_INTERNAL_STATE_NO_AUTOPILOT" ;
VAL_ 1481 APS_sw042_epas_error_code 15 "SNA" 13 "EAC_ERROR_PINION_VEL_DIFF" 12 "EAC_ERROR_LOW_ASSIST" 11 "EAC_ERROR_HIGH_TORSION_SAFETY" 10 "EAC_ERROR_HIGH_MMOT_SAFETY" 9 "EAC_ERROR_HIGH_ANGLE_RATE_SAFETY" 8 "EAC_ERROR_HIGH_ANGLE_SAFETY" 7 "EAC_ERROR_HIGH_ANGLE_RATE_REQ" 6 "EAC_ERROR_HIGH_ANGLE_REQ" 5 "EAR_ERROR_MAX_STEER_DELTA" 4 "EAC_ERROR_TMP_FAULT" 3 "EAC_ERROR_HANDS_ON" 2 "EAC_ERROR_MAX_SPEED" 1 "EAC_ERROR_MIN_SPEED" 0 "EAC_ERROR_IDLE" ;
VAL_ 1481 APS_sw043_mobileye_status 24 "MOBILEYE_STATUS_UNDEFINED" 23 "MOBILEYE_STATUS_TEARDOWN_FLASH_ACCESS_MODE" 22 "MOBILEYE_STATUS_FLASH_READ_MODE" 21 "MOBILEYE_STATUS_SETUP_FLASH_ACCESS_MODE" 20 "MOBILEYE_STATUS_RUNNING_SPTAC_MODE" 19 "MOBILEYE_STATUS_SPTAC_INIT_SENT" 18 "MOBILEYE_STATUS_WAITING_FOR_SPTAC_INIT" 17 "MOBILEYE_STATUS_BURN_EDR_MODE" 16 "MOBILEYE_STATUS_SPC_INIT_SENT" 15 "MOBILEYE_STATUS_WAITING_FOR_SPC_INIT" 14 "MOBILEYE_STATUS_ERROR" 13 "MOBILEYE_STATUS_LATCHING_FAILURE" 12 "MOBILEYE_STATUS_UPDATING" 11 "MOBILEYE_STATUS_RUNNING_DV_MODE" 10 "MOBILEYE_STATUS_WAITING_FOR_DV" 9 "MOBILEYE_STATUS_RUNNING_TAC_MODE" 8 "MOBILEYE_STATUS_RUNNING_SPC_MODE" 7 "MOBILEYE_STATUS_RUNNING_VISION_MODE" 6 "MOBILEYE_STATUS_TAC_INIT_SENT" 5 "MOBILEYE_STATUS_WAITING_FOR_TAC_INIT" 4 "MOBILEYE_STATUS_VISION_INIT_SENT" 3 "MOBILEYE_STATUS_WAITING_FOR_VISION_INIT" 2 "MOBILEYE_STATUS_WAITING_FOR_BOOT" 1 "MOBILEYE_STATUS_POWER_OFF" 0 "MOBILEYE_STATUS_POWER_CYCLE" ;
VAL_ 1481 APS_sw043_mesp_health_main_state 172 "EYEQ_MESP_MAIN_STATE_TAC2" 170 "EYEQ_MESP_MAIN_STATE_DV" 146 "EYEQ_MESP_MAIN_STATE_VISION_INIT_PENDING" 133 "EYEQ_MESP_MAIN_STATE_TAC2_INIT_PENDING" 130 "EYEQ_MESP_MAIN_STATE_SPC_INIT_PENDING" 129 "EYEQ_MESP_MAIN_STATE_SPTAC_INIT_PENDING" 34 "EYEQ_MESP_MAIN_STATE_SPC" 33 "EYEQ_MESP_MAIN_STATE_SPTAC" 2 "EYEQ_MESP_MAIN_STATE_VISION" ;
VAL_ 1481 APS_sw044_meMainState 8 "ERROR" 7 "DV" 6 "TAC2" 5 "TAC2_INIT_PENDING" 4 "SPC" 3 "SPC_INIT_PENDING" 2 "VISION" 1 "VISION_INIT_PENDING" 0 "NOT_INITIALIZED" ;
VAL_ 1481 APS_sw044_appStatus 24 "MOBILEYE_STATUS_UNDEFINED" 23 "MOBILEYE_STATUS_TEARDOWN_FLASH_ACCESS_MODE" 22 "MOBILEYE_STATUS_FLASH_READ_MODE" 21 "MOBILEYE_STATUS_SETUP_FLASH_ACCESS_MODE" 20 "MOBILEYE_STATUS_RUNNING_SPTAC_MODE" 19 "MOBILEYE_STATUS_SPTAC_INIT_SENT" 18 "MOBILEYE_STATUS_WAITING_FOR_SPTAC_INIT" 17 "MOBILEYE_STATUS_BURN_EDR_MODE" 16 "MOBILEYE_STATUS_SPC_INIT_SENT" 15 "MOBILEYE_STATUS_WAITING_FOR_SPC_INIT" 14 "MOBILEYE_STATUS_ERROR" 13 "MOBILEYE_STATUS_LATCHING_FAILURE" 12 "MOBILEYE_STATUS_UPDATING" 11 "MOBILEYE_STATUS_RUNNING_DV_MODE" 10 "MOBILEYE_STATUS_WAITING_FOR_DV" 9 "MOBILEYE_STATUS_RUNNING_TAC_MODE" 8 "MOBILEYE_STATUS_RUNNING_SPC_MODE" 7 "MOBILEYE_STATUS_RUNNING_VISION_MODE" 6 "MOBILEYE_STATUS_TAC_INIT_SENT" 5 "MOBILEYE_STATUS_WAITING_FOR_TAC_INIT" 4 "MOBILEYE_STATUS_VISION_INIT_SENT" 3 "MOBILEYE_STATUS_WAITING_FOR_VISION_INIT" 2 "MOBILEYE_STATUS_WAITING_FOR_BOOT" 1 "MOBILEYE_STATUS_POWER_OFF" 0 "MOBILEYE_STATUS_POWER_CYCLE" ;
VAL_ 1481 APS_sw045_radMia 21 "RAD0_RADC_TGU_info_MIA" 20 "RAD0_RADC_SGU_info_MIA" 19 "RAD0_RADC_ACCTargObj1_A_MIA" 18 "RAD0_RADC_ACCTargObj1_B_MIA" 17 "RAD0_RADC_ACCTargObj1_C_MIA" 16 "RAD0_RADC_ACCTargObj2_A_MIA" 15 "RAD0_RADC_ACCTargObj2_B_MIA" 14 "RAD0_RADC_ACCTargObj2_C_MIA" 13 "RAD0_RADC_ACCTargObj3_C_MIA" 12 "RAD0_RADC_ACCTargObj4_C_MIA" 11 "RAD0_RADC_ACCTargObj5_A_MIA" 10 "RAD0_RADC_ACCTargObj5_B_MIA" 9 "RAD0_RADC_ACCTargObj5_C_MIA" 8 "RAD0_RADC_FCWTargObj_A_MIA" 7 "RAD0_RADC_FCWTargObj_B_MIA" 6 "RAD0_RADC_FCWTargObj_C_MIA" 5 "RAD0_RADC_Packet_Ender_MIA" 4 "RAD0_RADC_Packet_Starter_MIA" 3 "RAD0_RADC_info_MIA" 2 "RAD0_RADRL_alertMatrix_MIA" 1 "RAD0_RADC_alertMatrix_MIA" 0 "Nominal" ;
VAL_ 1481 APS_sw047_edrStatus 6 "EVENT_TRIGGER_REJECTED" 5 "EVENT_SAVED_TO_FLASH" 4 "EVENT_SAVED_TO_LB" 3 "EVENT_TRIGGERED" 2 "EVENT_ERASED" 1 "FAULTED" 0 "EMPTY" ;
VAL_ 1481 APS_sw047_edrType 13 "PMM_IPSO_TYPE" 12 "ROB_SILENT_TYPE" 11 "ROB_ACTIVE_TYPE" 10 "FREESPACE_ELDW" 9 "AIRBAG_NEAR_DEPLOY" 8 "PMM" 7 "IN_PATH_STAT_OBJ" 6 "SILENT_AEB" 5 "UDS" 4 "FCW" 3 "HEAVY_BRAKING" 2 "AEB" 1 "AIRBAG_DEPLOY" 0 "UNDEFINED" ;
VAL_ 1481 APS_sw047_edrReturn 4000 "ERROR_EDR_MANAGER" 3000 "ERROR_DUMP_FAILED" 2000 "ERROR_LOG_DATA_FAILED" 1027 "ERROR_EDR_MANAGER_INVALID" 1026 "ERROR_POST_TRIGGER_NUM_TOO_LARGE" 1025 "ERROR_BB_NOT_FORMATTED" 1024 "ERROR_BB_VALIDATE_PROBLEM" 1023 "ERROR_FAILED_NO_DESC_AVALIABLE" 1022 "ERROR_NOT_ENOUGH_FRAMES_IN_LB" 1021 "ERROR_FAILED_WRITE_DATA_TO_BB" 1020 "ERROR_FAILED_NO_DATA_AVALIABLE" 1019 "ERROR_LB_CLIP_NOT_AVALIABLE" 1018 "ERROR_LB_ALREADY_CURRENT" 1017 "ERROR_WRONG_STATE" 1016 "ERROR_WRONG_LOGGER_BUFFER" 1015 "ERROR_FAILED_DUMP_LB_TO_BB" 1014 "ERROR_FAILED_FORMAT_BB" 1013 "ERROR_FAILED_TO_BURN_TO_REG_BB" 1012 "ERROR_NOTHING_TO_UPDATE" 1011 "ERROR_WRONG_CURR_TAG" 1010 "ERROR_BB_REG_ERROROR" 1009 "ERROR_DATA_SIZE_MISMATCH" 1008 "ERROR_FUNC_FAILED" 1006 "ERROR_PROCESS_OTHER_TASK" 1005 "ERROR_NO_DATA_TO_SAVE" 1004 "ERROR_FLASH_BB_LOCK" 1003 "ERROR_IMAGE_LOGGER_NOT_FOUND" 1002 "ERROR_BB_NOT_FOUND" 1001 "ERROR_INIT" 1000 "ERROR_UNDEFINED" 107 "ERROR_FUNC_NOT_EXIST" 0 "SUCCESS" ;
VAL_ 1481 APS_sw047_edrStateMachine 255 "EDR_FATAL_ERROR" 54 "PROCESS_EDR_NB_EXECUTE" 53 "PROCESS_EDR_EXECUTE_PART_2" 52 "PROCESS_EDR_EXECUTE_PART_1" 51 "PROCESS_EDR_MAP_LB_TO_BB" 34 "PROCESS_EDR_BB_CANCEL_FORMAT" 33 "PROCESS_EDR_BB_FORMAT" 32 "PROCESS_EDR_BB_GET_DESC" 30 "PROCESS_EDR_BB_QUERY" 16 "PROCESS_EDR_LB_SWITCH" 14 "PROCESS_EDR_LB_SET_DATA" 13 "PROCESS_EDR_LB_SET_DESC" 12 "PROCESS_EDR_LB_TRIGGER_EVENT" 11 "PROCESS_EDR_LB_QUERY" 10 "PROCESS_EDR_LB_GET_CURR" 4 "EDR_BURN_COMPLETE" 2 "EDR_TRIGGERED" 1 "RUNNING" 0 "IDLE" ;
VAL_ 1481 APS_sw049_boot_version_msw 65535 "FLASH_SECTION_EMPTY" 24589 "NO_MISMATCH" 0 "FLASH_READ_FAILURE" ;
VAL_ 1481 APS_sw049_app_version_msw 65535 "FLASH_SECTION_EMPTY" 24589 "NO_MISMATCH" 0 "FLASH_READ_FAILURE" ;
VAL_ 1481 APS_sw049_ffs_version_msw 65535 "FLASH_SECTION_EMPTY" 24589 "NO_MISMATCH" 0 "FLASH_READ_FAILURE" ;
VAL_ 1481 APS_sw051_a01ecuInternalPerf 1 "True" 0 "False" ;
VAL_ 1481 APS_sw051_a02flashPerformance 1 "True" 0 "False" ;
VAL_ 1481 APS_sw051_a03vBatHigh 1 "True" 0 "False" ;
VAL_ 1481 APS_sw051_a09configMismatch 1 "True" 0 "False" ;
VAL_ 1481 APS_sw051_a52radomeHtrInop 1 "True" 0 "False" ;
VAL_ 1481 APS_sw052_a07sensorBlinded 1 "True" 0 "False" ;
VAL_ 1481 APS_sw056_diMia 5 "CH_DI_state2_MIA" 4 "CH_DI_espControl_MIA" 3 "CH_DI_torque2_MIA" 2 "CH_DI_torque1_MIA" 1 "CH_DI_state_MIA" 0 "Nominal" ;
VAL_ 1481 APS_sw057_chCtrlMia 1 "TRUE" 0 "FALSE" ;
VAL_ 1481 APS_sw057_csaOfframpCurvMia 1 "TRUE" 0 "FALSE" ;
VAL_ 1481 APS_sw057_csaRoadCurvMia 1 "TRUE" 0 "FALSE" ;
VAL_ 1481 APS_sw057_dasControlMia 1 "TRUE" 0 "FALSE" ;
VAL_ 1481 APS_sw057_dasMapDataMia 1 "TRUE" 0 "FALSE" ;
VAL_ 1481 APS_sw057_gpsVehSpeedMia 1 "TRUE" 0 "FALSE" ;
VAL_ 1481 APS_sw057_locStatusMia 1 "TRUE" 0 "FALSE" ;
VAL_ 1481 APS_sw057_radarMapDataMia 1 "TRUE" 0 "FALSE" ;
VAL_ 1481 APS_sw057_roadCurvMia 1 "TRUE" 0 "FALSE" ;
VAL_ 1481 APS_sw057_solarDataMia 1 "TRUE" 0 "FALSE" ;
VAL_ 1481 APS_sw057_telemetryControlMia 1 "TRUE" 0 "FALSE" ;
VAL_ 1481 APS_sw057_statusMia 1 "TRUE" 0 "FALSE" ;
VAL_ 1481 APS_sw057_autopilotControlMia 1 "TRUE" 0 "FALSE" ;
VAL_ 1481 APS_sw058_epbMia 1 "CH_EPB_status_MIA" 0 "Nominal" ;
VAL_ 1481 APS_sw059_parkMia 11 "CH_PARK_pasRearMiddle_MIA" 10 "CH_PARK_sensorStatusRear_MIA" 9 "CH_PARK_oloDict_MIA" 8 "CH_PARK_status2_MIA" 7 "CH_PARK_pasFrontMiddle_MIA" 6 "CH_PARK_sensorStatusFront_MIA" 5 "CH_PARK_status_MIA" 4 "CH_PARK_oocStatus_MIA" 3 "CH_PARK_sdiRear_MIA" 2 "CH_PARK_pscStatus_MIA" 1 "CH_PARK_sdiFront_MIA" 0 "Nominal" ;
VAL_ 1481 APS_sw060_collisionWarningSource 7 "SOURCE_BCW_PEDESTRIAN" 6 "SOURCE_BCW_MCVLR" 5 "SOURCE_BCW_CIPV2" 4 "SOURCE_BCW_CIPV" 3 "SOURCE_BCW_CUTIN" 2 "SOURCE_STOPLINE" 1 "SOURCE_FCW_VEHICLE" 0 "SOURCE_FCW_PEDESTRIAN" ;
VAL_ 1481 APS_sw061_airSuspensionMia 128 "CH_TAS_STATES_MIA" 1 "CH_ASD_A2_MIA" 0 "Nominal" ;
VAL_ 1481 APS_sw064_epasMia 2 "PARTY_EPAS_sysStatus_MIA" 1 "CH_EPAS_sysStatus_MIA" 0 "Nominal" ;
VAL_ 1481 APS_sw065_app_mobileye_status 24 "MOBILEYE_STATUS_UNDEFINED" 23 "MOBILEYE_STATUS_TEARDOWN_FLASH_ACCESS_MODE" 22 "MOBILEYE_STATUS_FLASH_READ_MODE" 21 "MOBILEYE_STATUS_SETUP_FLASH_ACCESS_MODE" 20 "MOBILEYE_STATUS_RUNNING_SPTAC_MODE" 19 "MOBILEYE_STATUS_SPTAC_INIT_SENT" 18 "MOBILEYE_STATUS_WAITING_FOR_SPTAC_INIT" 17 "MOBILEYE_STATUS_BURN_EDR_MODE" 16 "MOBILEYE_STATUS_SPC_INIT_SENT" 15 "MOBILEYE_STATUS_WAITING_FOR_SPC_INIT" 14 "MOBILEYE_STATUS_ERROR" 13 "MOBILEYE_STATUS_LATCHING_FAILURE" 12 "MOBILEYE_STATUS_UPDATING" 11 "MOBILEYE_STATUS_RUNNING_DV_MODE" 10 "MOBILEYE_STATUS_WAITING_FOR_DV" 9 "MOBILEYE_STATUS_RUNNING_TAC_MODE" 8 "MOBILEYE_STATUS_RUNNING_SPC_MODE" 7 "MOBILEYE_STATUS_RUNNING_VISION_MODE" 6 "MOBILEYE_STATUS_TAC_INIT_SENT" 5 "MOBILEYE_STATUS_WAITING_FOR_TAC_INIT" 4 "MOBILEYE_STATUS_VISION_INIT_SENT" 3 "MOBILEYE_STATUS_WAITING_FOR_VISION_INIT" 2 "MOBILEYE_STATUS_WAITING_FOR_BOOT" 1 "MOBILEYE_STATUS_POWER_OFF" 0 "MOBILEYE_STATUS_POWER_CYCLE" ;
VAL_ 1481 APS_sw065_mobileye_main_state 255 "EYEQ_MESP_MAIN_STATE_UNDEFINED" 172 "EYEQ_MESP_MAIN_STATE_TAC2" 170 "EYEQ_MESP_MAIN_STATE_DV" 146 "EYEQ_MESP_MAIN_STATE_VISION_INIT_PENDING" 133 "EYEQ_MESP_MAIN_STATE_TAC2_INIT_PENDING" 130 "EYEQ_MESP_MAIN_STATE_SPC_INIT_PENDING" 129 "EYEQ_MESP_MAIN_STATE_SPTAC_INIT_PENDING" 34 "EYEQ_MESP_MAIN_STATE_SPC" 33 "EYEQ_MESP_MAIN_STATE_SPTAC" 2 "EYEQ_MESP_MAIN_STATE_VISION" ;
VAL_ 1481 APS_sw066_app_mobileye_status 24 "MOBILEYE_STATUS_UNDEFINED" 23 "MOBILEYE_STATUS_TEARDOWN_FLASH_ACCESS_MODE" 22 "MOBILEYE_STATUS_FLASH_READ_MODE" 21 "MOBILEYE_STATUS_SETUP_FLASH_ACCESS_MODE" 20 "MOBILEYE_STATUS_RUNNING_SPTAC_MODE" 19 "MOBILEYE_STATUS_SPTAC_INIT_SENT" 18 "MOBILEYE_STATUS_WAITING_FOR_SPTAC_INIT" 17 "MOBILEYE_STATUS_BURN_EDR_MODE" 16 "MOBILEYE_STATUS_SPC_INIT_SENT" 15 "MOBILEYE_STATUS_WAITING_FOR_SPC_INIT" 14 "MOBILEYE_STATUS_ERROR" 13 "MOBILEYE_STATUS_LATCHING_FAILURE" 12 "MOBILEYE_STATUS_UPDATING" 11 "MOBILEYE_STATUS_RUNNING_DV_MODE" 10 "MOBILEYE_STATUS_WAITING_FOR_DV" 9 "MOBILEYE_STATUS_RUNNING_TAC_MODE" 8 "MOBILEYE_STATUS_RUNNING_SPC_MODE" 7 "MOBILEYE_STATUS_RUNNING_VISION_MODE" 6 "MOBILEYE_STATUS_TAC_INIT_SENT" 5 "MOBILEYE_STATUS_WAITING_FOR_TAC_INIT" 4 "MOBILEYE_STATUS_VISION_INIT_SENT" 3 "MOBILEYE_STATUS_WAITING_FOR_VISION_INIT" 2 "MOBILEYE_STATUS_WAITING_FOR_BOOT" 1 "MOBILEYE_STATUS_POWER_OFF" 0 "MOBILEYE_STATUS_POWER_CYCLE" ;
VAL_ 1481 APS_sw066_mobileye_main_state 255 "EYEQ_MESP_MAIN_STATE_UNDEFINED" 172 "EYEQ_MESP_MAIN_STATE_TAC2" 170 "EYEQ_MESP_MAIN_STATE_DV" 146 "EYEQ_MESP_MAIN_STATE_VISION_INIT_PENDING" 133 "EYEQ_MESP_MAIN_STATE_TAC2_INIT_PENDING" 130 "EYEQ_MESP_MAIN_STATE_SPC_INIT_PENDING" 129 "EYEQ_MESP_MAIN_STATE_SPTAC_INIT_PENDING" 34 "EYEQ_MESP_MAIN_STATE_SPC" 33 "EYEQ_MESP_MAIN_STATE_SPTAC" 2 "EYEQ_MESP_MAIN_STATE_VISION" ;
VAL_ 1481 APS_sw069_epasMia 1 "EPAS_MIA" 0 "NO_EPAS_MIA" ;
VAL_ 1481 APS_sw069_espMia 1 "ESP_MIA" 0 "NO_ESP_MIA" ;
VAL_ 1481 APS_sw069_parkMia 1 "PARK_MIA" 0 "NO_PARK_MIA" ;
VAL_ 1481 APS_sw069_sccmMia 1 "SCCM_MIA" 0 "NO_SCCM_MIA" ;
VAL_ 1481 APS_sw069_parkMismatch 1 "PARK_VERSION_MISMATCH" 0 "NO_PARK_VERSION_MISMATCH" ;
VAL_ 1481 APS_sw069_eacStatus 7 "EAC_ELK_ACTIVE" 6 "EAC_ELK_AVAILABLE" 5 "EAC_LKA_ACTIVE" 4 "EAC_LKA_ELK_AVAILABLE" 3 "EAC_FAULT" 2 "EAC_ACTIVE" 1 "EAC_AVAILABLE" 0 "EAC_INHIBITED" ;
VAL_ 1481 APS_sw069_diAPState 15 "DI_APC_SNA" 8 "DI_APC_UNPARK_COMPLETE" 7 "DI_APC_RESUMED" 6 "DI_APC_ABORTED" 5 "DI_APC_PAUSED" 4 "DI_APC_COMPLETE" 3 "DI_APC_ACTIVE" 2 "DI_APC_STARTED" 1 "DI_APC_STANDBY" 0 "DI_APC_UNAVAILABLE" ;
VAL_ 1481 APS_sw069_parkCal 1 "COMPLETE" 0 "INCOMPLETE" ;
VAL_ 1481 APS_sw070_currTireFitment 3 "SNA" 1 "STAGGERED" 0 "SQUARE" ;
VAL_ 1481 APS_sw070_lastTireFitment 3 "SNA" 1 "STAGGERED" 0 "SQUARE" ;
VAL_ 1481 APS_sw070_diGear 7 "DI_GEAR_SNA" 4 "DI_GEAR_D" 3 "DI_GEAR_N" 2 "DI_GEAR_R" 1 "DI_GEAR_P" 0 "DI_GEAR_INVALID" ;
VAL_ 1481 APS_sw071_selfParkType 7 "SNA" 6 "SP_GUIDANCE_UNAVAILABLE" 5 "SP_GUIDANCE_FAULT" 4 "SP_GUIDANCE_ABORT" 3 "SP_GUIDANCE_COMPLETE" 2 "SP_GUIDANCE_UNPARK_ACTIVE" 1 "SP_GUIDANCE_PARK_ACTIVE" 0 "SP_GUIDANCE_STANDBY" ;
VAL_ 1481 APS_sw071_roadClass 6 "CLASS_6_MINOR" 5 "CLASS_5" 4 "CLASS_4" 3 "CLASS_3" 2 "CLASS_2" 1 "CLASS_1_MAJOR" 0 "UNKNOWN_INVALID_SNA" ;
VAL_ 1481 APS_sw071_driverPresent 1 "TRUE" 0 "FALSE" ;
VAL_ 1481 APS_sw071_airSuspension 6 "VERY_HIGH_LEVEL" 5 "HIGH_LEVEL" 4 "NORMAL_LEVEL" 3 "LOW_LEVEL" ;
VAL_ 1481 APS_sw071_activationType 2 "AUTOSUMMON" 1 "KEYFOB" 0 "CELL_PHONE" ;
VAL_ 1481 APS_sw073_escalateLDWreason 3 "LC_ELDW_REASON_STW_TAKEOVER" 2 "LC_ELDW_REASON_DOUBLE_PULL" 1 "LC_ELDW_REASON_SINGLE_PULL" 0 "LC_ELDW_REASON_NONE" ;
VAL_ 1481 APS_sw073_rawMobileyeLDW 3 "RESERVED" 2 "LDW_RIGHT" 1 "LDW_LEFT" 0 "NO_WARNING" ;
VAL_ 1481 APS_sw073_freespaceLDW 3 "RESERVED" 2 "LDW_RIGHT" 1 "LDW_LEFT" 0 "NO_WARNING" ;
VAL_ 1481 APS_sw074_roadClass 6 "CLASS_6_MINOR" 5 "CLASS_5" 4 "CLASS_4" 3 "CLASS_3" 2 "CLASS_2" 1 "CLASS_1_MAJOR" 0 "UNKNOWN_INVALID_SNA" ;
VAL_ 1481 APS_sw074_cruiseActive 1 "CRUISE_ACTIVE" 0 "CRUISE_INACTIVE" ;
VAL_ 1481 APS_sw074_autopilotActive 1 "AUTOPILOT_ACTIVE" 0 "AUTOPILOT_INACTIVE" ;
VAL_ 1481 APS_sw075_scMia 1 "CH_SC_Status_MIA" 0 "Nominal" ;
VAL_ 1481 APS_sw131_trapClass 7 "Trap_Class_nonMaskableInterrupt" 6 "Trap_Class_systemCall" 5 "Trap_Class_assertion" 4 "Trap_Class_bus" 3 "Trap_Class_contextManagement" 2 "Trap_Class_instructionErrors" 1 "Trap_Class_internalProtection" 0 "Trap_Class_memoryManagement" ;
VAL_ 1481 APS_sw132_mismatchType 1 "APS_APP_FW_REPO_GITHASH" 0 "GTW_APP_FW_REPO_GITHASH" ;
VAL_ 1481 APS_sw135_appCriticalReason 5 "AP_CRITICAL_REASON_WATCHDOG_CRITICAL" 4 "AP_CRITICAL_REASON_MIA" 3 "AP_CRITICAL_REASON_VERSION_MISMATCH" 2 "AP_CRITICAL_REASON_GPIO_CRITICAL" 1 "AP_CRITICAL_REASON_BOOT_TIMEOUT" 0 "AP_CRITICAL_REASON_UNKNOWN" ;
VAL_ 1481 APS_sw139_overflowBus 5 "CAN_BUS_RAD1" 4 "CAN_BUS_PARK" 3 "CAN_BUS_PT" 2 "CAN_BUS_RAD0" 1 "CAN_BUS_CH" 0 "CAN_BUS_PARTY" ;
VAL_ 1481 APS_sw151_apGpioState 3 "AP_GPIO_STATE_HEALTHY" 2 "AP_GPIO_STATE_CRITICAL" 1 "AP_GPIO_STATE_DISABLED" 0 "AP_GPIO_STATE_PWR_DOWN_REBOOT" ;
VAL_ 1481 APS_sw151_apWatchDogState 7 "AP_WDOG_STATE_SNA" 3 "AP_WDOG_STATE_HEALTHY" 2 "AP_WDOG_STATE_CRITICAL" 1 "AP_WDOG_STATE_DEGRADED" 0 "AP_WDOG_STATE_UNKNOWN" ;
VAL_ 1481 APS_sw151_diGear 7 "DI_GEAR_SNA" 4 "DI_GEAR_D" 3 "DI_GEAR_N" 2 "DI_GEAR_R" 1 "DI_GEAR_P" 0 "DI_GEAR_INVALID" ;
VAL_ 1481 APS_sw151_recoveryPathway 3 "AP_RECOVERY_HEALTHY_IN_PARK" 2 "AP_RECOVERY_LOCAL_BUILD_GPIO" 1 "AP_RECOVERY_POWER_DOWN" 0 "AP_NO_RECOVERY_PATH" ;
VAL_ 1481 APS_sw151_parkerType 1 "AP_PRIMARY" 0 "AP_BACKUP" ;
VAL_ 1481 APS_sw153_eacInhibitReason 7 "APS_EAC_FAULT_LSS_DURATION" 6 "APS_EAC_FAULT_DI_MIA" 5 "APS_EAC_FAULT_DAS_MIA" 4 "APS_EAC_FAULT_EPAS_MIA" 3 "APS_EAC_FAULT_HYSTERESIS" 2 "APS_EAC_FAULT_DURATION" 1 "APS_EAC_FAULT_EPAS" 0 "APS_EAC_FAULT_NONE" ;
VAL_ 1481 APS_sw153_eacInternalState 7 "APS_EAC_NUM_STATES" 6 "APS_EAC_STATE_LSS" 5 "APS_EAC_STATE_OVERRIDE" 4 "APS_EAC_STATE_INHIBIT" 3 "APS_EAC_STATE_AUTOPARK" 2 "APS_EAC_STATE_CONTINUOUS" 1 "APS_EAC_STATE_MOMENTARY" 0 "APS_EAC_STATE_INIT" ;
VAL_ 1481 APS_sw154_ethSwitchState 1 "APS_ETH_SWITCH_LOCKED" 0 "APS_ETH_SWITCH_UNLOCKED" ;
VAL_ 1481 APS_sw159_apbCriticalReason 5 "AP_CRITICAL_REASON_WATCHDOG_CRITICAL" 4 "AP_CRITICAL_REASON_MIA" 3 "AP_CRITICAL_REASON_VERSION_MISMATCH" 2 "AP_CRITICAL_REASON_GPIO_CRITICAL" 1 "AP_CRITICAL_REASON_BOOT_TIMEOUT" 0 "AP_CRITICAL_REASON_UNKNOWN" ;
VAL_ 1481 APS_sw160_mismatchType 1 "APS_APP_FW_REPO_GITHASH" 0 "GTW_APP_FW_REPO_GITHASH" ;
VAL_ 1481 APS_sw188_otherTurbo 2 "TURBO_UNKNOWN" 1 "TURBO_B" 0 "TURBO_A" ;
VAL_ 1481 APS_sw192_CANbus 4 "CAN_BUS_UNKNOWN" 3 "CAN_BUS_VEHICLE" 2 "CAN_BUS_RAD0" 1 "CAN_BUS_CH" 0 "CAN_BUS_PARTY" ;
VAL_ 1481 APS_sw193_outOfFocusImage 1 "True" 0 "False" ;
VAL_ 1481 APS_sw193_impairedVD 1 "True" 0 "False" ;
VAL_ 1481 APS_sw193_blurredImage 1 "True" 0 "False" ;
VAL_ 1481 APS_sw193_smearedSpots 1 "True" 0 "False" ;
VAL_ 1481 APS_sw193_partialBlockage 1 "True" 0 "False" ;
VAL_ 1481 APS_sw193_fullBlockage 1 "True" 0 "False" ;
VAL_ 1481 APS_sw193_smearedHalos 1 "True" 0 "False" ;
VAL_ 1481 APS_sw194_leadDx 255 "SNA" ;
VAL_ 1481 APS_sw194_leadVx 31 "SNA" ;
VAL_ 1481 APS_sw194_leadAx 31 "SNA" ;
VAL_ 1481 APS_sw194_reasonForHold 15 "SNA" 12 "STOPS_BUTTON_TOGGLE" 11 "MISSION_PLANNER_SLOWDOWN_REQUEST" 10 "STANDSTILL_STEERING_OVERRIDE" 9 "CAM_ONLY_CONTROL" 8 "MCP_CONTROL" 7 "DRIVER_SEATBELT" 6 "TRAFFIC_LIGHT" 5 "STOP_SIGN" 4 "CAM_STOP_AND_GO" 3 "TARGET_LOSS" 2 "ULTRASONIC_OBSTACLE" 1 "CAM_PEDESTRIAN" 0 "TIMEOUT" ;
VAL_ 1481 APS_sw199_internalState 14 "APC_INT_STATE_CENTER_STW" 13 "APC_INT_STATE_GEAR_CHANGE" 12 "APC_INT_STATE_PARKED" 11 "APC_INT_STATE_COMPLETE_UNPARKED" 10 "APC_INT_STATE_COMPLETE" 9 "APC_INT_STATE_ABORT" 8 "APC_INT_STATE_RESTART" 7 "APC_INT_STATE_PAUSE_USER_CONTROL" 6 "APC_INT_STATE_PAUSE_OBSTACLE_CONTROL" 5 "APC_INT_STATE_REVERSE_CONTROL" 4 "APC_INT_STATE_FORWARD_CONTROL" 3 "APC_INT_STATE_PREGUIDANCE" 2 "APC_INT_STATE_PRECRUISE" 1 "APC_INT_STATE_SEARCHING" 0 "APC_INT_STATE_DISABLED" ;
VAL_ 1481 APS_sw199_abortCodePARK 31 "SNA" 17 "ERROR" 16 "SYSTEM_FAULT" 15 "SYSTEM_SERVICE" 14 "APS_ABORT" 13 "EPAS_FAULT" 12 "VEHICLE_DYNAMICS_INTERVENTION" 11 "HANDS_ON_DETECTED" 10 "FULL_WARNING_ON_BOTH_SIDES" 9 "PARK_SPACE_TOO_SMALL" 8 "OBSTACLE_ON_PATH" 7 "MAX_YAW_ANGLE_REACHED" 6 "MAX_SWA_DEV_EXCEEDED" 5 "OFF_TRACK" 4 "UNCONTROLLED_TRAVEL_DIST_REACHED" 3 "NO_VALID_PATH" 2 "MAX_NUM_OF_MOVES" 1 "VELOCITY_TOO_HIGH" 0 "NONE" ;
VAL_ 1481 APS_sw199_abortCodeDas 28 "APC_ABORT_TOO_MANY_GEAR_CHANGES" 27 "APC_ABORT_TRAILER_MODE" 26 "APC_ABORT_PARKER_HEARTBEAT_MISSING" 25 "APC_ABORT_HEARTBEAT_MISSING" 24 "APC_ABORT_APP_MIA" 23 "APC_ABORT_PAUSE_CYCLES" 22 "APC_ABORT_EPAS_INHIBITED" 21 "APC_ABORT_USER_KEYFOB" 20 "APC_ABORT_SC_MIA" 19 "APC_ABORT_SENSOR_FAILURE" 18 "APC_ABORT_PRECRUISE_TIMEOUT" 17 "APC_ABORT_UI_REQUEST" 16 "APC_ABORT_LOST_DI_CONTROL" 15 "APC_ABORT_PARK_GEAR" 14 "APC_ABORT_RESTART_TIMEOUT" 13 "APC_ABORT_PAUSE_USER_TIMEOUT" 12 "APC_ABORT_PAUSE_OBSTACLE_TIMEOUT" 11 "APC_ABORT_ESP_MIA" 10 "APC_ABORT_SCCM_MIA" 9 "APC_ABORT_MCU_MIA" 8 "APC_ABORT_DI_MIA" 7 "APC_ABORT_EPAS_MIA" 6 "APC_ABORT_PARK_MIA" 5 "APC_ABORT_PREGUIDANCE_TIMEOUT" 4 "APC_ABORT_INVALID_SPACE" 3 "APC_ABORT_MCU_REQUEST_MISMATCH" 2 "APC_ABORT_PARK_GUIDANCE_ENDED" 1 "APC_ABORT_LOST_ANGLE_CONTROL" 0 "APC_ABORT_NONE" ;
VAL_ 1481 APS_sw200_autopilotIntState 15 "PRECANCEL" 14 "DRIVER_STEERING_OVERRIDE" 13 "PREABORTED" 12 "FAULT" 11 "ABORTED" 10 "ABORTING" 9 "CHECK_ACTIVATION_WHILE_UNAVAILABLE" 8 "CHECK_ACTIVATION_WHILE_DISABLED" 7 "ACTIVE_RESTRICTED" 6 "ACTIVE_NOMINAL" 5 "PREACTIVATION" 4 "CHECK_FOR_ACTIVATION" 3 "AVAILABLE" 2 "UNAVAILABLE" 1 "DISABLED" 0 "NO_AUTOPILOT" ;
VAL_ 1481 APS_sw201_viewRangeOAL 5 "ANOMALY_LEVEL_5" 4 "ANOMALY_LEVEL_4" 3 "ANOMALY_LEVEL_3" 2 "ANOMALY_LEVEL_2" 1 "ANOMALY_LEVEL_1" 0 "ANOMALY_LEVEL_0" ;
VAL_ 1481 APS_sw201_steeringErrorOAL 5 "ANOMALY_LEVEL_5" 4 "ANOMALY_LEVEL_4" 3 "ANOMALY_LEVEL_3" 2 "ANOMALY_LEVEL_2" 1 "ANOMALY_LEVEL_1" 0 "ANOMALY_LEVEL_0" ;
VAL_ 1481 APS_sw201_virtualLaneInputOAL 5 "ANOMALY_LEVEL_5" 4 "ANOMALY_LEVEL_4" 3 "ANOMALY_LEVEL_3" 2 "ANOMALY_LEVEL_2" 1 "ANOMALY_LEVEL_1" 0 "ANOMALY_LEVEL_0" ;
VAL_ 1481 APS_sw203_roadClass 6 "CLASS_6_MINOR" 5 "CLASS_5" 4 "CLASS_4" 3 "CLASS_3" 2 "CLASS_2" 1 "CLASS_1_MAJOR" 0 "UNKNOWN_INVALID_SNA" ;
VAL_ 1481 APS_sw203_curbType 2 "HIGH_CURB" 1 "LOW_CURB" 0 "VIRTUAL_CURB" ;
VAL_ 1481 APS_sw203_controlType 15 "SNA" 14 "SUMMON" 10 "PAUSE" 9 "SEARCH" 8 "COMPLETE" 7 "ABORT" 6 "PARALLEL_PULL_OUT_TO_RIGHT" 5 "PARALLEL_PULL_OUT_TO_LEFT" 4 "PARK_RIGHT_CROSS" 3 "PARK_RIGHT_PARALLEL" 2 "PARK_LEFT_CROSS" 1 "PARK_LEFT_PARALLEL" 0 "NONE" ;
VAL_ 1481 APS_sw204_frLeftMiddle 255 "SNA" ;
VAL_ 1481 APS_sw204_frRightMiddle 255 "SNA" ;
VAL_ 1481 APS_sw204_frRight 255 "SNA" ;
VAL_ 1481 APS_sw204_frLeft 255 "SNA" ;
VAL_ 1481 APS_sw204_frMiddle 255 "SNA" ;
VAL_ 1481 APS_sw205_rrRightMiddle 255 "SNA" ;
VAL_ 1481 APS_sw205_rrLeftMiddle 255 "SNA" ;
VAL_ 1481 APS_sw205_rrRight 255 "SNA" ;
VAL_ 1481 APS_sw205_rrLeft 255 "SNA" ;
VAL_ 1481 APS_sw205_rrMiddle 255 "SNA" ;
VAL_ 1481 APS_sw205_oocDistance 255 "SNA" ;
VAL_ 1481 APS_sw207_lcUnavailableReason 255 "LC_UNAVAILABLE_UNKNOWN" 80 "RR_UNAVAILABLE_SYSTEM_HEALTH_CRITICAL" 79 "RR_UNAVAILABLE_PERCEPTION_HEALTH_RADAR" 78 "RR_UNAVAILABLE_PERCEPTION_HEALTH_VISION" 77 "RR_UNAVAILABLE_RADAR_BLIND" 76 "RR_UNAVAILABLE_RADAR_FAULT" 75 "RR_UNAVAILABLE_RADAR_MIA" 74 "RR_UNAVAILABLE_ECU_THERMAL_ISSUE" 73 "RR_UNAVAILABLE_AEB_ACTIVE" 72 "RR_UNAVAILABLE_AUTOPARK_STATE" 71 "RR_UNAVAILABLE_STEERING_WHEEL_ANGLE" 70 "RR_UNAVAILABLE_FAILED_AUTOSTEER_ACTIVATION" 69 "RR_UNAVAILABLE_INVALID_DI_PEDAL_POS" 68 "RR_UNAVAILABLE_INVALID_VEHICLE_SPEED" 67 "RR_UNAVAILABLE_AP_NOT_CONFIGURED" 66 "RR_UNAVAILABLE_INTEGRATOR_HEALTH_CRITICAL" 65 "RR_UNAVAILABLE_RADAR_VERSION_MISMATCH" 64 "RR_UNAVAILABLE_TRACKED_OBSTACLE_DETECTED" 63 "RR_UNAVAILABLE_SONIC_OBSTACLE_DETECTED" 62 "RR_UNAVAILABLE_PEDESTRIAN_PRESENT_OR_NO_VEHICLE" 61 "RR_UNAVAILABLE_AVAILABILITY_CHECK_HYSTERESIS" 60 "RR_UNAVAILABLE_CAMERA_BLOCKED" 59 "RR_UNAVAILABLE_CAMERA_PITCH" 58 "RR_UNAVAILABLE_CAMERA_CALIBRATION" 57 "RR_UNAVAILABLE_DI_MIA" 56 "RR_UNAVAILABLE_GTW_MIA" 55 "RR_UNAVAILABLE_EPAS_MIA" 54 "RR_UNAVAILABLE_ESP_MIA" 53 "RR_UNAVAILABLE_DI_PARTY_MIA" 52 "RR_UNAVAILABLE_EPAS_PARTY_MIA" 51 "RR_UNAVAILABLE_ESP_PARTY_MIA" 50 "RR_UNAVAILABLE_CONTROL_REFERENCE_UNHEALTHY" 49 "RR_UNAVAILABLE_CONTROL_STALE_REFERENCE" 48 "RR_UNAVAILABLE_CONTROL_STALE_LOCALIZATION" 47 "RR_UNAVAILABLE_CONTROL_BAD_UPDATE" 46 "RR_UNAVAILABLE_CONTROL_REFERENCE_TOO_SHORT" 45 "RR_UNAVAILABLE_CONTROL_INDETERMINATE" 44 "RR_UNAVAILABLE_BELOW_MIN_SPEED" 43 "LC_UNAVAILABLE_SEATBELT_UNBUCKLED" 42 "RR_UNAVAILABLE_EPAS_STEERING_ANGLE_INVALID" 41 "RR_UNAVAILABLE_SYNTHESIZED_ACC_LANES_ACTIVE" 40 "RR_UNAVAILABLE_MCU_LATERAL_CONTROL_DISABLED" 39 "RR_UNAVAILABLE_INVALID_LANE_LINE_TYPE" 38 "RR_UNAVAILABLE_ROAD_ESTIMATOR_NOT_ALLOWED" 37 "RR_UNAVAILABLE_VEHICLE_SPEED_ABOVE_MAX_HYST" 36 "RR_UNAVAILABLE_SPEED_LIMIT_EXCEEDED" 35 "RR_UNAVAILABLE_CONTROL_SOLVER_UNHEALTHY" 34 "RR_UNAVAILABLE_CONTROL_PATH_UNHEALTHY" 33 "RR_UNAVAILABLE_CONTROL_OUTSIDE_LIMITS" 32 "RR_UNAVAILABLE_USER_STRIKEOUT" 31 "RR_UNAVAILABLE_EAC_REQUEST_TIMEOUT" 30 "RR_UNAVAILABLE_HK_TW_RESTRICTED" 29 "RR_UNAVAILABLE_TRAILER_MODE_ACTIVE" 28 "RR_UNAVAILABLE_CAMERA_FAILSAFES" 27 "RR_UNAVAILABLE_STEERING_LIMITS_EXCEEDED" 26 "RR_UNAVAILABLE_VEHICLE_SPEED_ABOVE_MAX" 25 "RR_UNAVAILABLE_VEHICLE_NOT_IN_DRIVE" 24 "RR_UNAVAILABLE_CRUISE_FAULT" 23 "RR_UNAVAILABLE_COMPONENT_NOT_READY" 22 "RR_UNAVAILABLE_COMPONENT_MIA" 21 "RR_UNAVAILABLE_EPAS_EAC_DENIED" 20 "RR_UNAVAILABLE_NONE" 19 "LC_UNAVAILABLE_VEHICLE_SPEED_ABOVE_MAX_HYST" 18 "LC_UNAVAILABLE_NOT_ON_HIGHWAY" 17 "LC_UNAVAILABLE_SPEED_LIMIT_EXCEEDED" 16 "LC_UNAVAILABLE_APP_ME_STATE_NOT_VISION" 15 "LC_UNAVAILABLE_ME_MAIN_STATE_NOT_VISION" 14 "LC_UNAVAILABLE_USER_STRIKEOUT" 13 "LC_UNAVAILABLE_EAC_REQUEST_TIMEOUT" 12 "LC_UNAVAILABLE_CAM_MSG_MIA" 11 "LC_UNAVAILABLE_HK_TW_RESTRICTED" 10 "LC_UNAVAILABLE_CAM_WATCHDOG" 9 "LC_UNAVAILABLE_TRAILER_MODE_ACTIVE" 8 "LC_UNAVAILABLE_CAMERA_FAILSAFES" 7 "LC_UNAVAILABLE_STEERING_LIMITS_EXCEEDED" 6 "LC_UNAVAILABLE_VEHICLE_SPEED_ABOVE_MAX" 5 "LC_UNAVAILABLE_VEHICLE_NOT_IN_DRIVE" 4 "LC_UNAVAILABLE_CRUISE_FAULT" 3 "LC_UNAVAILABLE_COMPONENT_NOT_READY" 2 "LC_UNAVAILABLE_COMPONENT_MIA" 1 "LC_UNAVAILABLE_EPAS_EAC_DENIED" 0 "LC_UNAVAILABLE_NONE" ;
VAL_ 1481 APS_sw207_appMobileyeStatus 24 "MOBILEYE_STATUS_UNDEFINED" 23 "MOBILEYE_STATUS_TEARDOWN_FLASH_ACCESS_MODE" 22 "MOBILEYE_STATUS_FLASH_READ_MODE" 21 "MOBILEYE_STATUS_SETUP_FLASH_ACCESS_MODE" 20 "MOBILEYE_STATUS_RUNNING_SPTAC_MODE" 19 "MOBILEYE_STATUS_SPTAC_INIT_SENT" 18 "MOBILEYE_STATUS_WAITING_FOR_SPTAC_INIT" 17 "MOBILEYE_STATUS_BURN_EDR_MODE" 16 "MOBILEYE_STATUS_SPC_INIT_SENT" 15 "MOBILEYE_STATUS_WAITING_FOR_SPC_INIT" 14 "MOBILEYE_STATUS_ERROR" 13 "MOBILEYE_STATUS_LATCHING_FAILURE" 12 "MOBILEYE_STATUS_UPDATING" 11 "MOBILEYE_STATUS_RUNNING_DV_MODE" 10 "MOBILEYE_STATUS_WAITING_FOR_DV" 9 "MOBILEYE_STATUS_RUNNING_TAC_MODE" 8 "MOBILEYE_STATUS_RUNNING_SPC_MODE" 7 "MOBILEYE_STATUS_RUNNING_VISION_MODE" 6 "MOBILEYE_STATUS_TAC_INIT_SENT" 5 "MOBILEYE_STATUS_WAITING_FOR_TAC_INIT" 4 "MOBILEYE_STATUS_VISION_INIT_SENT" 3 "MOBILEYE_STATUS_WAITING_FOR_VISION_INIT" 2 "MOBILEYE_STATUS_WAITING_FOR_BOOT" 1 "MOBILEYE_STATUS_POWER_OFF" 0 "MOBILEYE_STATUS_POWER_CYCLE" ;
VAL_ 1481 APS_sw207_eyeq3MainState 172 "EYEQ_MESP_MAIN_STATE_TAC2" 170 "EYEQ_MESP_MAIN_STATE_DV" 146 "EYEQ_MESP_MAIN_STATE_VISION_INIT_PENDING" 133 "EYEQ_MESP_MAIN_STATE_TAC2_INIT_PENDING" 130 "EYEQ_MESP_MAIN_STATE_SPC_INIT_PENDING" 129 "EYEQ_MESP_MAIN_STATE_SPTAC_INIT_PENDING" 34 "EYEQ_MESP_MAIN_STATE_SPC" 33 "EYEQ_MESP_MAIN_STATE_SPTAC" 2 "EYEQ_MESP_MAIN_STATE_VISION" ;
VAL_ 1481 APS_sw218_handsOnState 15 "LC_HANDS_ON_SNA" 9 "LC_HANDS_ON_REQD_ESCALATED_CHIME_2" 8 "LC_HANDS_ON_REQD_ESCALATED_CHIME_1" 7 "LC_HANDS_ON_REQD_STRUCK_OUT" 5 "LC_HANDS_ON_REQD_CHIME_2" 4 "LC_HANDS_ON_REQD_CHIME_1" 3 "LC_HANDS_ON_REQD_VISUAL" 2 "LC_HANDS_ON_REQD_NOT_DETECTED" 1 "LC_HANDS_ON_REQD_DETECTED" 0 "LC_HANDS_ON_NOT_REQD" ;
VAL_ 1481 APS_sw227_sensorSide 1 "VEHICLE_SIDE_RIGHT" 0 "VEHICLE_SIDE_LEFT" ;
VAL_ 1481 APS_sw227_sensorNumber 1 "SENSOR_MIDDLE" 0 "SENSOR_FRONT" ;
VAL_ 1036 APS_nmKeepAwakeReason 2 "APS_KEEPAWAKE_REASON_APP_SUSPENDED" 1 "APS_KEEPAWAKE_REASON_APP_INITIALIZING" 0 "APS_KEEPAWAKE_REASON_NONE_SNA" ;
VAL_ 637 APS_eacAllow 3 "APS_EAC_SNA" 2 "APS_EAC_RESERVED" 1 "APS_EAC_ALLOW" 0 "APS_EAC_INHIBIT" ;
VAL_ 915 APS_hvacPowerRequest 1 "REQUEST_HVAC_POWER_ON" 0 "REQUEST_HVAC_POWER_OFF" ;
VAL_ 1050 APS_primaryTurbo 2 "TURBO_UNKNOWN" 1 "TURBO_B" 0 "TURBO_A" ;
VAL_ 1050 APS_A_arbState 7 "ARB_STATE_COUNT" 6 "ARB_STATE_UNKNOWN" 5 "ARB_STATE_MIA" 4 "ARB_STATE_FAULT" 3 "ARB_STATE_SECONDARY" 2 "ARB_STATE_PRIMARY" 1 "ARB_STATE_IDLE" 0 "ARB_STATE_INIT" ;
VAL_ 1050 APS_A_powerState 24 "POWER_STATE_COUNT" 23 "POWER_STATE_UNKNOWN" 22 "POWER_STATE_MIA" 21 "POWER_STATE_FAULT" 20 "POWER_STATE_SOC_OFF_ABORT" 19 "POWER_STATE_SOC_OFF" 18 "POWER_STATE_SOC_OFF_READY" 17 "POWER_STATE_AP_SUSPENDED" 16 "POWER_STATE_AP_OFF_ABORT_WAIT_FOR_ACK" 15 "POWER_STATE_AP_OFF_ABORT" 14 "POWER_STATE_AP_OFF_READY_WAIT_FOR_RESPONSE" 13 "POWER_STATE_AP_OFF_READY_WAIT_FOR_ACK" 12 "POWER_STATE_AP_OFF_READY" 11 "POWER_STATE_AP_OFF_PREPARE" 10 "POWER_STATE_AP_WAIT_FOR_SHUTDOWN" 9 "POWER_STATE_AP_ON" 8 "POWER_STATE_AP_IN_COREBOOT" 7 "POWER_STATE_AP_BOOTING" 6 "POWER_STATE_AP_ON_READY_WAIT_FOR_RESPONSE" 5 "POWER_STATE_AP_ON_READY_WAIT_FOR_ACK" 4 "POWER_STATE_AP_ON_READY" 3 "POWER_STATE_AP_ON_PREPARE_WAIT_FOR_RESPONSE" 2 "POWER_STATE_AP_ON_PREPARE_WAIT_FOR_ACK" 1 "POWER_STATE_AP_ON_PREPARE" 0 "POWER_STATE_IDLE" ;
VAL_ 1050 APS_A_sleepState 9 "SLEEP_STATE_COUNT" 8 "SLEEP_STATE_UNKNOWN" 7 "SLEEP_STATE_MIA" 6 "SLEEP_STATE_FAULT" 5 "SLEEP_STATE_ABORT" 4 "SLEEP_STATE_SLEEPING" 3 "SLEEP_STATE_GOING_TO_SLEEP" 2 "SLEEP_STATE_READY" 1 "SLEEP_STATE_WAIT_FOR_BUS_SILENCE" 0 "SLEEP_STATE_IDLE" ;
VAL_ 1050 APS_A_resetState 5 "RESET_STATE_COUNT" 4 "RESET_STATE_UNKNOWN" 3 "RESET_STATE_MIA" 2 "RESET_STATE_FAULT" 1 "RESET_STATE_RESETTING" 0 "RESET_STATE_NOT_RESETTING" ;
VAL_ 1050 APS_A_faultState 27 "FAULT_STATE_COUNT" 26 "FAULT_STATE_UNKNOWN" 25 "FAULT_STATE_MIA" 24 "FAULT_STATE_UNEXPECTED" 23 "FAULT_STATE_SCS" 22 "FAULT_STATE_SOFTWARE_FAULT" 21 "FAULT_STATE_TRIP1_FAULT" 20 "FAULT_STATE_TRIP0_FAULT" 19 "FAULT_STATE_WDT" 18 "FAULT_STATE_CPU_FAULT" 17 "FAULT_STATE_DROOP_TRIP" 16 "FAULT_STATE_DROOP_GPU" 15 "FAULT_STATE_DROOP_CPUCL2" 14 "FAULT_STATE_DROOP_CPUCL1" 13 "FAULT_STATE_DROOP_CPUCL0" 12 "FAULT_STATE_MIF_ECC_AP" 11 "FAULT_STATE_MIF7_DFI_ALERT" 10 "FAULT_STATE_MIF6_DFI_ALERT" 9 "FAULT_STATE_MIF5_DFI_ALERT" 8 "FAULT_STATE_MIF4_DFI_ALERT" 7 "FAULT_STATE_MIF3_DFI_ALERT" 6 "FAULT_STATE_MIF2_DFI_ALERT" 5 "FAULT_STATE_MIF1_DFI_ALERT" 4 "FAULT_STATE_MIF0_DFI_ALERT" 3 "FAULT_STATE_MIF_ECC_UNCORRECTED" 2 "FAULT_STATE_MIF_ECC_CORRECTED" 1 "FAULT_STATE_GIC" 0 "FAULT_STATE_NONE" ;
VAL_ 1050 APS_secondaryTurbo 2 "TURBO_UNKNOWN" 1 "TURBO_B" 0 "TURBO_A" ;
VAL_ 1050 APS_B_arbState 7 "ARB_STATE_COUNT" 6 "ARB_STATE_UNKNOWN" 5 "ARB_STATE_MIA" 4 "ARB_STATE_FAULT" 3 "ARB_STATE_SECONDARY" 2 "ARB_STATE_PRIMARY" 1 "ARB_STATE_IDLE" 0 "ARB_STATE_INIT" ;
VAL_ 1050 APS_B_powerState 24 "POWER_STATE_COUNT" 23 "POWER_STATE_UNKNOWN" 22 "POWER_STATE_MIA" 21 "POWER_STATE_FAULT" 20 "POWER_STATE_SOC_OFF_ABORT" 19 "POWER_STATE_SOC_OFF" 18 "POWER_STATE_SOC_OFF_READY" 17 "POWER_STATE_AP_SUSPENDED" 16 "POWER_STATE_AP_OFF_ABORT_WAIT_FOR_ACK" 15 "POWER_STATE_AP_OFF_ABORT" 14 "POWER_STATE_AP_OFF_READY_WAIT_FOR_RESPONSE" 13 "POWER_STATE_AP_OFF_READY_WAIT_FOR_ACK" 12 "POWER_STATE_AP_OFF_READY" 11 "POWER_STATE_AP_OFF_PREPARE" 10 "POWER_STATE_AP_WAIT_FOR_SHUTDOWN" 9 "POWER_STATE_AP_ON" 8 "POWER_STATE_AP_IN_COREBOOT" 7 "POWER_STATE_AP_BOOTING" 6 "POWER_STATE_AP_ON_READY_WAIT_FOR_RESPONSE" 5 "POWER_STATE_AP_ON_READY_WAIT_FOR_ACK" 4 "POWER_STATE_AP_ON_READY" 3 "POWER_STATE_AP_ON_PREPARE_WAIT_FOR_RESPONSE" 2 "POWER_STATE_AP_ON_PREPARE_WAIT_FOR_ACK" 1 "POWER_STATE_AP_ON_PREPARE" 0 "POWER_STATE_IDLE" ;
VAL_ 1050 APS_B_sleepState 9 "SLEEP_STATE_COUNT" 8 "SLEEP_STATE_UNKNOWN" 7 "SLEEP_STATE_MIA" 6 "SLEEP_STATE_FAULT" 5 "SLEEP_STATE_ABORT" 4 "SLEEP_STATE_SLEEPING" 3 "SLEEP_STATE_GOING_TO_SLEEP" 2 "SLEEP_STATE_READY" 1 "SLEEP_STATE_WAIT_FOR_BUS_SILENCE" 0 "SLEEP_STATE_IDLE" ;
VAL_ 1050 APS_B_resetState 5 "RESET_STATE_COUNT" 4 "RESET_STATE_UNKNOWN" 3 "RESET_STATE_MIA" 2 "RESET_STATE_FAULT" 1 "RESET_STATE_RESETTING" 0 "RESET_STATE_NOT_RESETTING" ;
VAL_ 1050 APS_B_faultState 27 "FAULT_STATE_COUNT" 26 "FAULT_STATE_UNKNOWN" 25 "FAULT_STATE_MIA" 24 "FAULT_STATE_UNEXPECTED" 23 "FAULT_STATE_SCS" 22 "FAULT_STATE_SOFTWARE_FAULT" 21 "FAULT_STATE_TRIP1_FAULT" 20 "FAULT_STATE_TRIP0_FAULT" 19 "FAULT_STATE_WDT" 18 "FAULT_STATE_CPU_FAULT" 17 "FAULT_STATE_DROOP_TRIP" 16 "FAULT_STATE_DROOP_GPU" 15 "FAULT_STATE_DROOP_CPUCL2" 14 "FAULT_STATE_DROOP_CPUCL1" 13 "FAULT_STATE_DROOP_CPUCL0" 12 "FAULT_STATE_MIF_ECC_AP" 11 "FAULT_STATE_MIF7_DFI_ALERT" 10 "FAULT_STATE_MIF6_DFI_ALERT" 9 "FAULT_STATE_MIF5_DFI_ALERT" 8 "FAULT_STATE_MIF4_DFI_ALERT" 7 "FAULT_STATE_MIF3_DFI_ALERT" 6 "FAULT_STATE_MIF2_DFI_ALERT" 5 "FAULT_STATE_MIF1_DFI_ALERT" 4 "FAULT_STATE_MIF0_DFI_ALERT" 3 "FAULT_STATE_MIF_ECC_UNCORRECTED" 2 "FAULT_STATE_MIF_ECC_CORRECTED" 1 "FAULT_STATE_GIC" 0 "FAULT_STATE_NONE" ;
VAL_ 969 APS_appStatusMonitorState 7 "STATUS_MONITOR_NUM_STATES" 6 "STATUS_MONITOR_STATE_RECOVERY" 5 "STATUS_MONITOR_STATE_SHUTTING_DOWN" 4 "STATUS_MONITOR_STATE_CRITICAL" 3 "STATUS_MONITOR_STATE_NOMINAL" 2 "STATUS_MONITOR_STATE_INIT" 1 "STATUS_MONITOR_STATE_PWR_OFF" 0 "STATUS_MONITOR_STATE_UNKNOWN" ;
VAL_ 969 APS_vehBehaviorState 8 "VEH_BEHAVIOR_NUM_STATES" 7 "VEH_BEHAVIOR_STATE_SYSTEM_FAULT" 6 "VEH_BEHAVIOR_STATE_APS_OVERRIDE" 5 "VEH_BEHAVIOR_STATE_APS_FAIL_SAFE" 4 "VEH_BEHAVIOR_STATE_APS_BRIDGE_APB" 3 "VEH_BEHAVIOR_STATE_APS_BRIDGE_APP" 2 "VEH_BEHAVIOR_STATE_APS_CONTROL" 1 "VEH_BEHAVIOR_STATE_APS_AVAILABLE" 0 "VEH_BEHAVIOR_STATE_UNKNOWN" ;
VAL_ 969 APS_canMaster 3 "CAN_MASTER_SNA" 2 "CAN_MASTER_APB" 1 "CAN_MASTER_APP" 0 "CAN_MASTER_APS" ;
VAL_ 969 APS_appGpioState 3 "AP_GPIO_STATE_HEALTHY" 2 "AP_GPIO_STATE_CRITICAL" 1 "AP_GPIO_STATE_DISABLED" 0 "AP_GPIO_STATE_PWR_DOWN_REBOOT" ;
VAL_ 969 APS_eacInternalState 7 "APS_EAC_NUM_STATES" 6 "APS_EAC_STATE_LSS" 5 "APS_EAC_STATE_OVERRIDE" 4 "APS_EAC_STATE_INHIBIT" 3 "APS_EAC_STATE_AUTOPARK" 2 "APS_EAC_STATE_CONTINUOUS" 1 "APS_EAC_STATE_MOMENTARY" 0 "APS_EAC_STATE_INIT" ;
VAL_ 969 APS_switchState 1 "APS_ETH_SWITCH_LOCKED" 0 "APS_ETH_SWITCH_UNLOCKED" ;
VAL_ 969 APS_apbStatusMonitorState 7 "STATUS_MONITOR_NUM_STATES" 6 "STATUS_MONITOR_STATE_RECOVERY" 5 "STATUS_MONITOR_STATE_SHUTTING_DOWN" 4 "STATUS_MONITOR_STATE_CRITICAL" 3 "STATUS_MONITOR_STATE_NOMINAL" 2 "STATUS_MONITOR_STATE_INIT" 1 "STATUS_MONITOR_STATE_PWR_OFF" 0 "STATUS_MONITOR_STATE_UNKNOWN" ;
VAL_ 969 APS_apbGpioState 3 "AP_GPIO_STATE_HEALTHY" 2 "AP_GPIO_STATE_CRITICAL" 1 "AP_GPIO_STATE_DISABLED" 0 "AP_GPIO_STATE_PWR_DOWN_REBOOT" ;
VAL_ 969 APS_locLimitReason 7 "LOC_LIMITS_EXTENDED" 5 "NO_RADAR_TARGET" 4 "RADAR_NOT_HEALTHY" 3 "PRIMARY_AP_NOT_HEALTHY" 2 "ACC_AND_AEB_UNAVAILABLE" 1 "NOT_IN_DRIVE" 0 "NOMINAL_DEFAULT" ;
VAL_ 969 APS_appPowerStateRequest 3 "AP_POWER_STATE_SLEEP" 2 "AP_POWER_STATE_SUSPEND" 1 "AP_POWER_STATE_SENTRY" 0 "AP_POWER_STATE_NOMINAL" ;
VAL_ 969 APS_appPowerStateReason 6 "AP_POWER_REQUEST_OVERHEATING" 5 "AP_POWER_REQUEST_HYSTERESIS" 4 "AP_GOTO_FULL_POWER" 3 "AP_NOT_IN_PARK" 2 "AP_NM_REASON_SET" 1 "AP_WDOG_UNHEALTHY" 0 "POWER_STATE_REQUEST_BY_UI" ;
VAL_ 969 APS_apbPowerStateRequest 3 "AP_POWER_STATE_SLEEP" 2 "AP_POWER_STATE_SUSPEND" 1 "AP_POWER_STATE_SENTRY" 0 "AP_POWER_STATE_NOMINAL" ;
VAL_ 969 APS_apbPowerStateReason 6 "AP_POWER_REQUEST_OVERHEATING" 5 "AP_POWER_REQUEST_HYSTERESIS" 4 "AP_GOTO_FULL_POWER" 3 "AP_NOT_IN_PARK" 2 "AP_NM_REASON_SET" 1 "AP_WDOG_UNHEALTHY" 0 "POWER_STATE_REQUEST_BY_UI" ;
VAL_ 969 APS_heaterStateDebug 7 "APS_HEATER_SNA" 4 "APS_HEATER_FAULT_SHORT" 3 "APS_HEATER_FAULT_OPEN" 2 "APS_HEATER_ON_NOT_HEATING" 1 "APS_HEATER_ON_HEATING" 0 "APS_HEATER_OFF" ;
VAL_ 1115 APS_setSpeed 4095 "SNA" ;
VAL_ 1115 APS_accState 15 "FAULT_SNA" 13 "ACC_CANCEL_GENERIC_SILENT" 11 "APC_SELFPARK_START" 10 "APC_UNPARK_COMPLETE" 9 "APC_PAUSE" 8 "APC_ABORT" 7 "APC_COMPLETE" 6 "APC_FORWARD" 5 "APC_BACKWARD" 4 "ACC_ON" 3 "ACC_HOLD" 0 "ACC_CANCEL_GENERIC" ;
VAL_ 1115 APS_aebEvent 3 "AEB_SNA" 2 "AEB_FAULT" 1 "AEB_ACTIVE" 0 "AEB_NOT_ACTIVE" ;
VAL_ 1115 APS_jerkMin 511 "SNA" ;
VAL_ 1115 APS_jerkMax 255 "SNA" ;
VAL_ 1115 APS_accelMin 511 "SNA" ;
VAL_ 1115 APS_accelMax 511 "SNA" ;
VAL_ 971 APS_apcInternalState 14 "APC_INT_STATE_CENTER_STW" 13 "APC_INT_STATE_GEAR_CHANGE" 12 "APC_INT_STATE_PARKED" 11 "APC_INT_STATE_COMPLETE_UNPARKED" 10 "APC_INT_STATE_COMPLETE" 9 "APC_INT_STATE_ABORT" 8 "APC_INT_STATE_RESTART" 7 "APC_INT_STATE_PAUSE_USER_CONTROL" 6 "APC_INT_STATE_PAUSE_OBSTACLE_CONTROL" 5 "APC_INT_STATE_REVERSE_CONTROL" 4 "APC_INT_STATE_FORWARD_CONTROL" 3 "APC_INT_STATE_PREGUIDANCE" 2 "APC_INT_STATE_PRECRUISE" 1 "APC_INT_STATE_SEARCHING" 0 "APC_INT_STATE_DISABLED" ;
VAL_ 971 APS_apcAbortCode 28 "APC_ABORT_TOO_MANY_GEAR_CHANGES" 27 "APC_ABORT_TRAILER_MODE" 26 "APC_ABORT_PARKER_HEARTBEAT_MISSING" 25 "APC_ABORT_HEARTBEAT_MISSING" 24 "APC_ABORT_APP_MIA" 23 "APC_ABORT_PAUSE_CYCLES" 22 "APC_ABORT_EPAS_INHIBITED" 21 "APC_ABORT_USER_KEYFOB" 20 "APC_ABORT_SC_MIA" 19 "APC_ABORT_SENSOR_FAILURE" 18 "APC_ABORT_PRECRUISE_TIMEOUT" 17 "APC_ABORT_UI_REQUEST" 16 "APC_ABORT_LOST_DI_CONTROL" 15 "APC_ABORT_PARK_GEAR" 14 "APC_ABORT_RESTART_TIMEOUT" 13 "APC_ABORT_PAUSE_USER_TIMEOUT" 12 "APC_ABORT_PAUSE_OBSTACLE_TIMEOUT" 11 "APC_ABORT_ESP_MIA" 10 "APC_ABORT_SCCM_MIA" 9 "APC_ABORT_MCU_MIA" 8 "APC_ABORT_DI_MIA" 7 "APC_ABORT_EPAS_MIA" 6 "APC_ABORT_PARK_MIA" 5 "APC_ABORT_PREGUIDANCE_TIMEOUT" 4 "APC_ABORT_INVALID_SPACE" 3 "APC_ABORT_MCU_REQUEST_MISMATCH" 2 "APC_ABORT_PARK_GUIDANCE_ENDED" 1 "APC_ABORT_LOST_ANGLE_CONTROL" 0 "APC_ABORT_NONE" ;
VAL_ 267 FL_Lvl 255 "SNA" 254 "Init" ;
VAL_ 267 FR_Lvl 255 "SNA" 254 "Init" ;
VAL_ 267 RL_Lvl 255 "SNA" 254 "Init" ;
VAL_ 267 RR_Lvl 255 "SNA" 254 "Init" ;
VAL_ 283 Wala_LC_red 1 "WARNING_LAMP_ON" 0 "WARNING_LAMP_OFF" ;
VAL_ 283 Wala_LC_yel 1 "WARNING_LAMP_ON" 0 "WARNING_LAMP_OFF" ;
VAL_ 283 LC_LimpHomeMode 7 "LIMP_HOME_MODE_70" 6 "LIMP_HOME_MODE_60" 5 "LIMP_HOME_MODE_50" 4 "LIMP_HOME_MODE_40" 3 "LIMP_HOME_MODE_30" 2 "LIMP_HOME_MODE_20" 1 "LIMP_HOME_MODE_10" 0 "NO_LIMP_HOME_MODE" ;
VAL_ 283 SysDisabled 1 "LEVEL_CONTROL_DISABLED" 0 "LEVEL_CONTROL_ENABLED" ;
VAL_ 283 TargetLevel 7 "VERY_LOW_LEVEL" 6 "VERY_HIGH_LEVEL" 5 "HIGH_LEVEL" 4 "NORMAL_LEVEL" 3 "LOW_LEVEL" 2 "NOT_DEFINED_2" 1 "NOT_DEFINED_1" 0 "NOT_DEFINED_0" ;
VAL_ 283 CurrentLevel 6 "VERY_HIGH_LEVEL" 5 "HIGH_LEVEL" 4 "NORMAL_LEVEL" 3 "LOW_LEVEL" ;
VAL_ 577 BCCEN_seeYouHomeLightingReq 1 "LIGHT_REQUEST" 0 "LIGHT_NO_REQUEST" ;
VAL_ 577 BCCEN_footwellLightsStatus 3 "LIGHT_SNA" 2 "LIGHT_FAULT" 1 "LIGHT_ON" 0 "LIGHT_OFF" ;
VAL_ 577 BCCEN_ambientLightingRequest 1 "LIGHT_REQUEST" 0 "LIGHT_NO_REQUEST" ;
VAL_ 577 BCCEN_courtesyLightingRequest 1 "LIGHT_REQUEST" 0 "LIGHT_NO_REQUEST" ;
VAL_ 577 BCCEN_approachLightingRequest 1 "LIGHT_REQUEST" 0 "LIGHT_NO_REQUEST" ;
VAL_ 577 BCCEN_ambientLightsStatus 3 "LIGHT_SNA" 2 "LIGHT_FAULT" 1 "LIGHT_ON" 0 "LIGHT_OFF" ;
VAL_ 577 BCCEN_switchLightingRequest 1 "LIGHT_REQUEST" 0 "LIGHT_NO_REQUEST" ;
VAL_ 577 BCCEN_hazardLightRequest 8 "HAZARD_REQUEST_UDS" 7 "HAZARD_REQUEST_DAS" 6 "HAZARD_REQUEST_CAR_ALARM" 5 "HAZARD_REQUEST_CRASH" 4 "HAZARD_REQUEST_MISLOCK" 3 "HAZARD_REQUEST_UNLOCK" 2 "HAZARD_REQUEST_LOCK" 1 "HAZARD_REQUEST_BUTTON" 0 "HAZARD_REQUEST_NONE" ;
VAL_ 652 BCS2L_firstRowRecallIndex 1 "BC_FIRST_ROW_RECALL_PASSENGER" 0 "BC_FIRST_ROW_RECALL_DRIVER" ;
VAL_ 653 BCS2R_firstRowRecallIndex 1 "BC_FIRST_ROW_RECALL_PASSENGER" 0 "BC_FIRST_ROW_RECALL_DRIVER" ;
VAL_ 778 BDY_wiperState 2 "FAULT" 1 "ON" 0 "OFF" ;
VAL_ 778 BDY_flashMainSwitch 7 "default_main_switch" 2 "Main_beam_toggle" 1 "Momentary_flash" 0 "Flash_off" ;
VAL_ 778 BDY_rlsActive 1 "RLS_ACTIVE" 0 "RLS_INACTIVE_OR_NOT_PRESENT" ;
VAL_ 778 BDY_rlsHumidity 255 "SNA" ;
VAL_ 778 BDY_rlsWindowTemperature 255 "SNA" ;
